VERSION ""

NS_ :

BS_:

BU_: ETH

BO_ 800 BMS_alertMatrix: 8 Vector__XXX
 SG_ BMS_matrixIndex M : 0|4@1+ (1,0) [0|0] "" Vector__XXX
 SG_ BMS_a001_Pack_Config_Mismatch m0 : 4|1@1+ (1,0) [0|0] "" Vector__XXX
 SG_ BMS_a061_SW_BrickV_Change m1 : 4|1@1+ (1,0) [0|0] "" Vector__XXX
 SG_ BMS_a121_SW_NVRAM_Config_Error m2 : 4|1@1+ (1,0) [0|0] "" Vector__XXX
 SG_ BMS_a181_SW_Shunt_Over_Temperature m3 : 4|1@1+ (1,0) [0|0] "" Vector__XXX
 SG_ BMS_a002_Pack_Performance_Config_Mismatch m0 : 5|1@1+ (1,0) [0|0] "" Vector__XXX
 SG_ BMS_a062_SW_BrickV_Imbalance m1 : 5|1@1+ (1,0) [0|0] "" Vector__XXX
 SG_ BMS_a122_SW_BMS_Therm_Irrational m2 : 5|1@1+ (1,0) [0|0] "" Vector__XXX
 SG_ BMS_a182_LifeModel_NoCurrentLoss_Change m3 : 5|1@1+ (1,0) [0|0] "" Vector__XXX
 SG_ BMS_a003_SW_Pack_Birth_Date_Missing m0 : 6|1@1+ (1,0) [0|0] "" Vector__XXX
 SG_ BMS_a063_SW_ChargePort_Fault m1 : 6|1@1+ (1,0) [0|0] "" Vector__XXX
 SG_ BMS_a123_SW_Internal_Isolation m2 : 6|1@1+ (1,0) [0|0] "" Vector__XXX
 SG_ BMS_a183_LifeModel_StoDcrGrowth_Change m3 : 6|1@1+ (1,0) [0|0] "" Vector__XXX
 SG_ BMS_a004_Cal_Vs_Serial_Birth_Date_Mismatch m0 : 7|1@1+ (1,0) [0|0] "" Vector__XXX
 SG_ BMS_a064_SW_SOC_Imbalance m1 : 7|1@1+ (1,0) [0|0] "" Vector__XXX
 SG_ BMS_a124_Battery_Coolant_Flood m2 : 7|1@1+ (1,0) [0|0] "" Vector__XXX
 SG_ BMS_a184_LifeModel_CyclingLoss_Change m3 : 7|1@1+ (1,0) [0|0] "" Vector__XXX
 SG_ BMS_a065_SW_CAC_Imbalance m1 : 8|1@1+ (1,0) [0|0] "" Vector__XXX
 SG_ BMS_a185_LifeModel_CyclingDcrGrowth_Change m3 : 8|1@1+ (1,0) [0|0] "" Vector__XXX
 SG_ BMS_a066_SOC_Imbalance_Warning m1 : 9|1@1+ (1,0) [0|0] "" Vector__XXX
 SG_ BMS_a126_SW_Thermistor_Failure m2 : 9|1@1+ (1,0) [0|0] "" Vector__XXX
 SG_ BMS_a186_RippleHeatingChargeFault m3 : 9|1@1+ (1,0) [0|0] "" Vector__XXX
 SG_ BMS_a067_CAC_Imbalance_Limiting m1 : 10|1@1+ (1,0) [0|0] "" Vector__XXX
 SG_ BMS_a127_SW_shunt_SNA m2 : 10|1@1+ (1,0) [0|0] "" Vector__XXX
 SG_ BMS_a187_RippleHeatingEmergencyShutdown m3 : 10|1@1+ (1,0) [0|0] "" Vector__XXX
 SG_ BMS_a068_CAC_Imbalance_Limp m1 : 11|1@1+ (1,0) [0|0] "" Vector__XXX
 SG_ BMS_a128_SW_shunt_MIA m2 : 11|1@1+ (1,0) [0|0] "" Vector__XXX
 SG_ BMS_a188_PowershareChargeCurrentViolation m3 : 11|1@1+ (1,0) [0|0] "" Vector__XXX
 SG_ BMS_a069_SW_Low_Power m1 : 12|1@1+ (1,0) [0|0] "" Vector__XXX
 SG_ BMS_a129_SW_VSH_Failure m2 : 12|1@1+ (1,0) [0|0] "" Vector__XXX
 SG_ BMS_a189_PowershareDischargeCurrentViolation m3 : 12|1@1+ (1,0) [0|0] "" Vector__XXX
 SG_ BMS_a070_BrickV_Imbalance_Limiting m1 : 13|1@1+ (1,0) [0|0] "" Vector__XXX
 SG_ BMS_a130_IO_CAN_Error m2 : 13|1@1+ (1,0) [0|0] "" Vector__XXX
 SG_ BMS_a190_PowershareMaxVoltageViolation m3 : 13|1@1+ (1,0) [0|0] "" Vector__XXX
 SG_ BMS_a071_SW_SM_TransCon_Not_Met m1 : 14|1@1+ (1,0) [0|0] "" Vector__XXX
 SG_ BMS_a131_Bleed_FET_Failure m2 : 14|1@1+ (1,0) [0|0] "" Vector__XXX
 SG_ BMS_a191_PowershareMinVoltageViolation m3 : 14|1@1+ (1,0) [0|0] "" Vector__XXX
 SG_ BMS_a072_Module_Brick_Split m1 : 15|1@1+ (1,0) [0|0] "" Vector__XXX
 SG_ BMS_a132_HW_BMB_OTP_Uncorrctbl m2 : 15|1@1+ (1,0) [0|0] "" Vector__XXX
 SG_ BMS_a192_PowershareExternalChargeRegulation m3 : 15|1@1+ (1,0) [0|0] "" Vector__XXX
 SG_ BMS_a073_Unexpected_Loss_Of_Lv m1 : 16|1@1+ (1,0) [0|0] "" Vector__XXX
 SG_ BMS_a133_IO_CAN_Bus_Off m2 : 16|1@1+ (1,0) [0|0] "" Vector__XXX
 SG_ BMS_a193_PowershareMaxBrickVoltageViolation m3 : 16|1@1+ (1,0) [0|0] "" Vector__XXX
 SG_ BMS_a074_Max_Charge_Level_Reduced m1 : 17|1@1+ (1,0) [0|0] "" Vector__XXX
 SG_ BMS_a134_SW_Delayed_Ctr_Off m2 : 17|1@1+ (1,0) [0|0] "" Vector__XXX
 SG_ BMS_a194_PowershareLimitViolation m3 : 17|1@1+ (1,0) [0|0] "" Vector__XXX
 SG_ BMS_a075_SW_Chg_Disable_Failure m1 : 18|1@1+ (1,0) [0|0] "" Vector__XXX
 SG_ BMS_a135_HW_BMB_Diagnostics_Failure m2 : 18|1@1+ (1,0) [0|0] "" Vector__XXX
 SG_ BMS_a195_SW_DeltaTempOverThreshold m3 : 18|1@1+ (1,0) [0|0] "" Vector__XXX
 SG_ BMS_a016_Pack_Module_Id_Mismatch m0 : 19|1@1+ (1,0) [0|0] "" Vector__XXX
 SG_ BMS_a076_SW_Dch_While_Charging m1 : 19|1@1+ (1,0) [0|0] "" Vector__XXX
 SG_ BMS_a136_SW_Module_OT_Warning m2 : 19|1@1+ (1,0) [0|0] "" Vector__XXX
 SG_ BMS_a196_SW_PackVoltageUnderThreshold m3 : 19|1@1+ (1,0) [0|0] "" Vector__XXX
 SG_ BMS_a017_SW_Brick_OV m0 : 20|1@1+ (1,0) [0|0] "" Vector__XXX
 SG_ BMS_a077_SW_Charger_Regulation m1 : 20|1@1+ (1,0) [0|0] "" Vector__XXX
 SG_ BMS_a137_SW_Brick_UV_Warning m2 : 20|1@1+ (1,0) [0|0] "" Vector__XXX
 SG_ BMS_a197_SW_High_SOC_OV m3 : 20|1@1+ (1,0) [0|0] "" Vector__XXX
 SG_ BMS_d257_internalIsolationFault m4 : 20|1@1+ (1,0) [0|0] "" Vector__XXX
 SG_ BMS_a018_SW_Brick_UV m0 : 21|1@1+ (1,0) [0|0] "" Vector__XXX
 SG_ BMS_a078_Rapid_Dch_While_Charging m1 : 21|1@1+ (1,0) [0|0] "" Vector__XXX
 SG_ BMS_a138_SW_Brick_OV_Warning m2 : 21|1@1+ (1,0) [0|0] "" Vector__XXX
 SG_ BMS_a198_SW_SOC_Abrupt_Change m3 : 21|1@1+ (1,0) [0|0] "" Vector__XXX
 SG_ BMS_d258_externalIsolationFault m4 : 21|1@1+ (1,0) [0|0] "" Vector__XXX
 SG_ BMS_a019_SW_Module_OT m0 : 22|1@1+ (1,0) [0|0] "" Vector__XXX
 SG_ BMS_a079_Max_Charge_Level_Exceeded m1 : 22|1@1+ (1,0) [0|0] "" Vector__XXX
 SG_ BMS_a139_SW_DC_Link_V_Irrational m2 : 22|1@1+ (1,0) [0|0] "" Vector__XXX
 SG_ BMS_d259_highVoltageInterlockFailure m4 : 22|1@1+ (1,0) [0|0] "" Vector__XXX
 SG_ BMS_a020_SW_Brick_Instability m0 : 23|1@1+ (1,0) [0|0] "" Vector__XXX
 SG_ BMS_a080_SW_Pack_Ctr_Impedance m1 : 23|1@1+ (1,0) [0|0] "" Vector__XXX
 SG_ BMS_a140_HW_BMB_Status_Fault m2 : 23|1@1+ (1,0) [0|0] "" Vector__XXX
 SG_ BMS_d260_chargePortInterlockFailure m4 : 23|1@1+ (1,0) [0|0] "" Vector__XXX
 SG_ BMS_a021_SW_Dr_Limits_Regulation m0 : 24|1@1+ (1,0) [0|0] "" Vector__XXX
 SG_ BMS_a081_SW_Ctr_Close_Blocked m1 : 24|1@1+ (1,0) [0|0] "" Vector__XXX
 SG_ BMS_a141_SW_BMB_Status_Warning m2 : 24|1@1+ (1,0) [0|0] "" Vector__XXX
 SG_ BMS_d261_batteryPackCellVoltageHigh m4 : 24|1@1+ (1,0) [0|0] "" Vector__XXX
 SG_ BMS_a022_SW_Over_Current m0 : 25|1@1+ (1,0) [0|0] "" Vector__XXX
 SG_ BMS_a082_SW_Ctr_Force_Open m1 : 25|1@1+ (1,0) [0|0] "" Vector__XXX
 SG_ BMS_a142_SW_Isolation_Degradation m2 : 25|1@1+ (1,0) [0|0] "" Vector__XXX
 SG_ BMS_d262_batteryPackLowStateOfCharge m4 : 25|1@1+ (1,0) [0|0] "" Vector__XXX
 SG_ BMS_a023_SW_Stack_OV m0 : 26|1@1+ (1,0) [0|0] "" Vector__XXX
 SG_ BMS_a083_SW_Ctr_Close_Failure m1 : 26|1@1+ (1,0) [0|0] "" Vector__XXX
 SG_ BMS_a143_SW_CAC_Change m2 : 26|1@1+ (1,0) [0|0] "" Vector__XXX
 SG_ BMS_d263_batterySystemCurrentHigh m4 : 26|1@1+ (1,0) [0|0] "" Vector__XXX
 SG_ BMS_a024_SW_Islanded_Brick m0 : 27|1@1+ (1,0) [0|0] "" Vector__XXX
 SG_ BMS_a084_SW_Sleep_Wake_Aborted m1 : 27|1@1+ (1,0) [0|0] "" Vector__XXX
 SG_ BMS_a144_Hvp_Config_Mismatch m2 : 27|1@1+ (1,0) [0|0] "" Vector__XXX
 SG_ BMS_d264_invalidFirmwareConfig m4 : 27|1@1+ (1,0) [0|0] "" Vector__XXX
 SG_ BMS_a025_SW_PwrBalance_Anomaly m0 : 28|1@1+ (1,0) [0|0] "" Vector__XXX
 SG_ BMS_a085_SW_Pack_Contactor_Mismatch m1 : 28|1@1+ (1,0) [0|0] "" Vector__XXX
 SG_ BMS_a145_SW_SOC_Change m2 : 28|1@1+ (1,0) [0|0] "" Vector__XXX
 SG_ BMS_d265_replaceBatteryPack m4 : 28|1@1+ (1,0) [0|0] "" Vector__XXX
 SG_ BMS_a026_SW_HFCurrent_Anomaly m0 : 29|1@1+ (1,0) [0|0] "" Vector__XXX
 SG_ BMS_a086_SW_FC_Contactor_Mismatch m1 : 29|1@1+ (1,0) [0|0] "" Vector__XXX
 SG_ BMS_a146_SW_Brick_Overdischarged m2 : 29|1@1+ (1,0) [0|0] "" Vector__XXX
 SG_ BMS_d266_energyReserveVoltageLow m4 : 29|1@1+ (1,0) [0|0] "" Vector__XXX
 SG_ BMS_a027_SW_Repeated_Isolation_Failure_In_Drive m0 : 30|1@1+ (1,0) [0|0] "" Vector__XXX
 SG_ BMS_a087_SW_Feim_Test_Blocked m1 : 30|1@1+ (1,0) [0|0] "" Vector__XXX
 SG_ BMS_a147_SW_SOC_High_Ah_Error m2 : 30|1@1+ (1,0) [0|0] "" Vector__XXX
 SG_ BMS_d267_batteryPackCellVoltageSenseHarnessFailure m4 : 30|1@1+ (1,0) [0|0] "" Vector__XXX
 SG_ BMS_a028_ShuntAsicCurrentOffsetDeviation m0 : 31|1@1+ (1,0) [0|0] "" Vector__XXX
 SG_ BMS_a088_SW_VcFront_MIA_InDrive m1 : 31|1@1+ (1,0) [0|0] "" Vector__XXX
 SG_ BMS_a148_SW_Unsupported_BMB_ASIC_Type m2 : 31|1@1+ (1,0) [0|0] "" Vector__XXX
 SG_ BMS_d268_hvpInvalidFirmwareConfig m4 : 31|1@1+ (1,0) [0|0] "" Vector__XXX
 SG_ BMS_a029_dSoc_Limiting m0 : 32|1@1+ (1,0) [0|0] "" Vector__XXX
 SG_ BMS_a089_SW_VcFront_MIA m1 : 32|1@1+ (1,0) [0|0] "" Vector__XXX
 SG_ BMS_a149_SW_Missing_Config_Block m2 : 32|1@1+ (1,0) [0|0] "" Vector__XXX
 SG_ BMS_d269_highVoltageFuseABlown m4 : 32|1@1+ (1,0) [0|0] "" Vector__XXX
 SG_ BMS_a030_Impedance_Deviation m0 : 33|1@1+ (1,0) [0|0] "" Vector__XXX
 SG_ BMS_a090_SW_Gateway_MIA m1 : 33|1@1+ (1,0) [0|0] "" Vector__XXX
 SG_ BMS_a150_SW_Missing_Part_Number m2 : 33|1@1+ (1,0) [0|0] "" Vector__XXX
 SG_ BMS_d270_hvpCommsLost m4 : 33|1@1+ (1,0) [0|0] "" Vector__XXX
 SG_ BMS_a031_AlertsSetDuringSleep m0 : 34|1@1+ (1,0) [0|0] "" Vector__XXX
 SG_ BMS_a091_SW_ChargePort_MIA m1 : 34|1@1+ (1,0) [0|0] "" Vector__XXX
 SG_ BMS_a151_SW_external_isolation m2 : 34|1@1+ (1,0) [0|0] "" Vector__XXX
 SG_ BMS_d271_batteryPackSensorFailure m4 : 34|1@1+ (1,0) [0|0] "" Vector__XXX
 SG_ BMS_a032_VoltageLoss m0 : 35|1@1+ (1,0) [0|0] "" Vector__XXX
 SG_ BMS_a092_SW_ChargePort_Mia_On_Hvs m1 : 35|1@1+ (1,0) [0|0] "" Vector__XXX
 SG_ BMS_a152_Isolation_In_Dc_Charge m2 : 35|1@1+ (1,0) [0|0] "" Vector__XXX
 SG_ BMS_d272_batteryPackSensorCommsLost m4 : 35|1@1+ (1,0) [0|0] "" Vector__XXX
 SG_ BMS_a033_VoltageDeviation m0 : 36|1@1+ (1,0) [0|0] "" Vector__XXX
 SG_ BMS_a153_GridFormFaulted m2 : 36|1@1+ (1,0) [0|0] "" Vector__XXX
 SG_ BMS_d273_vcFrontCommsLost m4 : 36|1@1+ (1,0) [0|0] "" Vector__XXX
 SG_ BMS_a034_SW_Passive_Isolation m0 : 37|1@1+ (1,0) [0|0] "" Vector__XXX
 SG_ BMS_a094_SW_Drive_Inverter_MIA m1 : 37|1@1+ (1,0) [0|0] "" Vector__XXX
 SG_ BMS_a154_SW_Brick_OV_Warning_Stop_Charge m2 : 37|1@1+ (1,0) [0|0] "" Vector__XXX
 SG_ BMS_d274_packCurrentSensorACircuitFailure m4 : 37|1@1+ (1,0) [0|0] "" Vector__XXX
 SG_ BMS_a035_SW_Isolation m0 : 38|1@1+ (1,0) [0|0] "" Vector__XXX
 SG_ BMS_a095_SW_UI_MIA m1 : 38|1@1+ (1,0) [0|0] "" Vector__XXX
 SG_ BMS_a155_SW_Weak_short_impedence m2 : 38|1@1+ (1,0) [0|0] "" Vector__XXX
 SG_ BMS_d275_packPosContactorACircuitFailure m4 : 38|1@1+ (1,0) [0|0] "" Vector__XXX
 SG_ BMS_a036_SW_HvpHvilFault m0 : 39|1@1+ (1,0) [0|0] "" Vector__XXX
 SG_ BMS_a156_SW_BMB_Vref_bad m2 : 39|1@1+ (1,0) [0|0] "" Vector__XXX
 SG_ BMS_d276_packPosContactorAStuckClosed m4 : 39|1@1+ (1,0) [0|0] "" Vector__XXX
 SG_ BMS_a037_SW_Flood_Port_Open m0 : 40|1@1+ (1,0) [0|0] "" Vector__XXX
 SG_ BMS_a097_SW_BMB_Over_CAN_Communication m1 : 40|1@1+ (1,0) [0|0] "" Vector__XXX
 SG_ BMS_a157_SW_Hist_Update_Missed m2 : 40|1@1+ (1,0) [0|0] "" Vector__XXX
 SG_ BMS_d277_packNegContactorACircuitFailure m4 : 40|1@1+ (1,0) [0|0] "" Vector__XXX
 SG_ BMS_a098_SW_BMB_Data_Integrity_Loss m1 : 41|1@1+ (1,0) [0|0] "" Vector__XXX
 SG_ BMS_a158_SW_HVP_HVI_Comms m2 : 41|1@1+ (1,0) [0|0] "" Vector__XXX
 SG_ BMS_d278_packNegContactorAStuckClosed m4 : 41|1@1+ (1,0) [0|0] "" Vector__XXX
 SG_ BMS_a039_SW_DC_Link_Over_Voltage m0 : 42|1@1+ (1,0) [0|0] "" Vector__XXX
 SG_ BMS_a099_SW_BMB_Communication m1 : 42|1@1+ (1,0) [0|0] "" Vector__XXX
 SG_ BMS_a159_SW_HVP_ECU_Error m2 : 42|1@1+ (1,0) [0|0] "" Vector__XXX
 SG_ BMS_d279_fastChargePosContactorACircuitFailure m4 : 42|1@1+ (1,0) [0|0] "" Vector__XXX
 SG_ BMS_a040_SW_Watch_Dog_HW_Triggered m0 : 43|1@1+ (1,0) [0|0] "" Vector__XXX
 SG_ BMS_a100_ThermalEventSuspected m1 : 43|1@1+ (1,0) [0|0] "" Vector__XXX
 SG_ BMS_a160_SW_FC_Ctr_Clean_Failed m2 : 43|1@1+ (1,0) [0|0] "" Vector__XXX
 SG_ BMS_d280_fastChargePosContactorAStuckClosed m4 : 43|1@1+ (1,0) [0|0] "" Vector__XXX
 SG_ BMS_a041_SW_Destructive_Reset_Source m0 : 44|1@1+ (1,0) [0|0] "" Vector__XXX
 SG_ BMS_a161_SW_BMB_Vref_warning m2 : 44|1@1+ (1,0) [0|0] "" Vector__XXX
 SG_ BMS_d281_fastChargePosContactorAStuckOpen m4 : 44|1@1+ (1,0) [0|0] "" Vector__XXX
 SG_ BMS_a042_SW_MPU_Error m0 : 45|1@1+ (1,0) [0|0] "" Vector__XXX
 SG_ BMS_a162_SW_No_Power_For_Support m2 : 45|1@1+ (1,0) [0|0] "" Vector__XXX
 SG_ BMS_d282_fastChargeNegContactorACircuitFailure m4 : 45|1@1+ (1,0) [0|0] "" Vector__XXX
 SG_ BMS_a043_SW_Watch_Dog_Reset m0 : 46|1@1+ (1,0) [0|0] "" Vector__XXX
 SG_ BMS_a163_GridFormAborted m2 : 46|1@1+ (1,0) [0|0] "" Vector__XXX
 SG_ BMS_d283_fastChargeNegContactorAStuckClosed m4 : 46|1@1+ (1,0) [0|0] "" Vector__XXX
 SG_ BMS_a044_SW_Assertion m0 : 47|1@1+ (1,0) [0|0] "" Vector__XXX
 SG_ BMS_a164_SW_Uncontrolled_Regen m2 : 47|1@1+ (1,0) [0|0] "" Vector__XXX
 SG_ BMS_d284_fastChargeNegContactorAStuckOpen m4 : 47|1@1+ (1,0) [0|0] "" Vector__XXX
 SG_ BMS_a045_SW_Exception m0 : 48|1@1+ (1,0) [0|0] "" Vector__XXX
 SG_ BMS_a105_SW_One_Module_Tsense m1 : 48|1@1+ (1,0) [0|0] "" Vector__XXX
 SG_ BMS_a165_SW_Pack_Partial_Weld m2 : 48|1@1+ (1,0) [0|0] "" Vector__XXX
 SG_ BMS_d285_packVoltageSensorACircuitFailure m4 : 48|1@1+ (1,0) [0|0] "" Vector__XXX
 SG_ BMS_a046_SW_Task_Stack_Usage m0 : 49|1@1+ (1,0) [0|0] "" Vector__XXX
 SG_ BMS_a106_SW_All_Module_Tsense m1 : 49|1@1+ (1,0) [0|0] "" Vector__XXX
 SG_ BMS_a166_SW_Pack_Full_Weld m2 : 49|1@1+ (1,0) [0|0] "" Vector__XXX
 SG_ BMS_d286_dcLinkVoltageHigh m4 : 49|1@1+ (1,0) [0|0] "" Vector__XXX
 SG_ BMS_a047_SW_Task_Stack_Overflow m0 : 50|1@1+ (1,0) [0|0] "" Vector__XXX
 SG_ BMS_a107_SW_Stack_Voltage_MIA m1 : 50|1@1+ (1,0) [0|0] "" Vector__XXX
 SG_ BMS_a167_SW_FC_Partial_Weld m2 : 50|1@1+ (1,0) [0|0] "" Vector__XXX
 SG_ BMS_d287_systemIsolationWarning m4 : 50|1@1+ (1,0) [0|0] "" Vector__XXX
 SG_ BMS_a048_SW_Watch_Dog_Warning m0 : 51|1@1+ (1,0) [0|0] "" Vector__XXX
 SG_ BMS_a108_SW_BMB_Device_OT m1 : 51|1@1+ (1,0) [0|0] "" Vector__XXX
 SG_ BMS_a168_SW_FC_Full_Weld m2 : 51|1@1+ (1,0) [0|0] "" Vector__XXX
 SG_ BMS_d288_batteryPackCellVoltageLow m4 : 51|1@1+ (1,0) [0|0] "" Vector__XXX
 SG_ BMS_a049_SW_Thermal_Event m0 : 52|1@1+ (1,0) [0|0] "" Vector__XXX
 SG_ BMS_a109_HW_BMB_Mute_Status_Mismatch m1 : 52|1@1+ (1,0) [0|0] "" Vector__XXX
 SG_ BMS_a169_SW_FC_Pack_Weld m2 : 52|1@1+ (1,0) [0|0] "" Vector__XXX
 SG_ BMS_d289_batteryPackAOverTemperature m4 : 52|1@1+ (1,0) [0|0] "" Vector__XXX
 SG_ BMS_a050_SW_Brick_Voltage_MIA m0 : 53|1@1+ (1,0) [0|0] "" Vector__XXX
 SG_ BMS_a110_LifeModel_AvgOffset_Change m1 : 53|1@1+ (1,0) [0|0] "" Vector__XXX
 SG_ BMS_a170_SW_Limp_Mode m2 : 53|1@1+ (1,0) [0|0] "" Vector__XXX
 SG_ BMS_d290_batteryPackTempSensorACircuitFailure m4 : 53|1@1+ (1,0) [0|0] "" Vector__XXX
 SG_ BMS_a051_SW_HVC_Vref_Bad m0 : 54|1@1+ (1,0) [0|0] "" Vector__XXX
 SG_ BMS_a111_LifeModel_Spread_Change m1 : 54|1@1+ (1,0) [0|0] "" Vector__XXX
 SG_ BMS_a171_SW_Stack_Voltage_Sense m2 : 54|1@1+ (1,0) [0|0] "" Vector__XXX
 SG_ BMS_a052_SW_PCS_MIA m0 : 55|1@1+ (1,0) [0|0] "" Vector__XXX
 SG_ BMS_a112_LifeModel_Discontinuity m1 : 55|1@1+ (1,0) [0|0] "" Vector__XXX
 SG_ BMS_a172_SW_Isolation_Failure_In_Drive_Warning m2 : 55|1@1+ (1,0) [0|0] "" Vector__XXX
 SG_ BMS_a173_FullPackEnergyDegraded m2 : 56|1@1+ (1,0) [0|0] "" Vector__XXX
 SG_ BMS_a054_SW_Ver_Supply_Fault m0 : 57|1@1+ (1,0) [0|0] "" Vector__XXX
 SG_ BMS_a174_SW_Charge_Failure m2 : 57|1@1+ (1,0) [0|0] "" Vector__XXX
 SG_ BMS_a055_SW_HvChain_Model_Fault m0 : 58|1@1+ (1,0) [0|0] "" Vector__XXX
 SG_ BMS_a115_Energy_Rubberbanding_Reset m1 : 58|1@1+ (1,0) [0|0] "" Vector__XXX
 SG_ BMS_a175_Charge_Failure_External m2 : 58|1@1+ (1,0) [0|0] "" Vector__XXX
 SG_ BMS_a056_SW_Standby_Supply_Fault m0 : 59|1@1+ (1,0) [0|0] "" Vector__XXX
 SG_ BMS_a176_SW_GracefulPowerOff m2 : 59|1@1+ (1,0) [0|0] "" Vector__XXX
 SG_ BMS_a057_SW_Bandolier_Model_Warning m0 : 60|1@1+ (1,0) [0|0] "" Vector__XXX
 SG_ BMS_a117_SW_Delta_SOC_Weak_Short m1 : 60|1@1+ (1,0) [0|0] "" Vector__XXX
 SG_ BMS_a177_SW_Energy_Buffer_Size m2 : 60|1@1+ (1,0) [0|0] "" Vector__XXX
 SG_ BMS_a058_SW_Bandolier_Model_Reset m0 : 61|1@1+ (1,0) [0|0] "" Vector__XXX
 SG_ BMS_a178_SW_Uncontrolled_Regen_PwrB m2 : 61|1@1+ (1,0) [0|0] "" Vector__XXX
 SG_ BMS_a059_SW_Pack_Voltage_Sensing m0 : 62|1@1+ (1,0) [0|0] "" Vector__XXX
 SG_ BMS_a119_Fast_Open_Vsh_Detected m1 : 62|1@1+ (1,0) [0|0] "" Vector__XXX
 SG_ BMS_a179_HvpGpoRequestActive m2 : 62|1@1+ (1,0) [0|0] "" Vector__XXX
 SG_ BMS_a060_SW_Leakage_Test_Failure m0 : 63|1@1+ (1,0) [0|0] "" Vector__XXX
 SG_ BMS_a180_SW_ECU_reset_blocked m2 : 63|1@1+ (1,0) [0|0] "" Vector__XXX

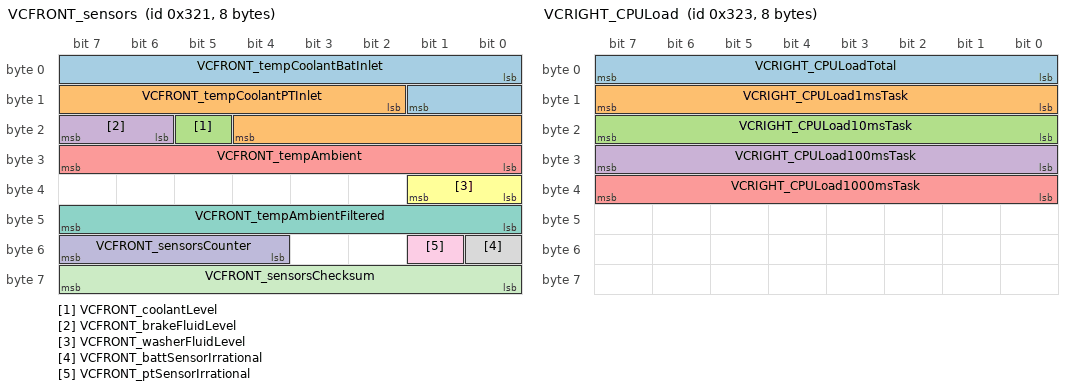
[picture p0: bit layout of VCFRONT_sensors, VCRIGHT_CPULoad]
BO_ 801 VCFRONT_sensors: 8 Vector__XXX
 SG_ VCFRONT_tempCoolantBatInlet : 0|10@1+ (0.125,-40) [0|0] "" Vector__XXX
 SG_ VCFRONT_tempCoolantPTInlet : 10|11@1+ (0.125,-40) [0|0] "" Vector__XXX
 SG_ VCFRONT_coolantLevel : 21|1@1+ (1,0) [0|0] "" Vector__XXX
 SG_ VCFRONT_brakeFluidLevel : 22|2@1+ (1,0) [0|0] "" Vector__XXX
 SG_ VCFRONT_tempAmbient : 24|8@1+ (0.5,-40) [0|0] "" Vector__XXX
 SG_ VCFRONT_washerFluidLevel : 32|2@1+ (1,0) [0|0] "" Vector__XXX
 SG_ VCFRONT_tempAmbientFiltered : 40|8@1+ (0.5,-40) [0|0] "" Vector__XXX
 SG_ VCFRONT_battSensorIrrational : 48|1@1+ (1,0) [0|0] "" Vector__XXX
 SG_ VCFRONT_ptSensorIrrational : 49|1@1+ (1,0) [0|0] "" Vector__XXX
 SG_ VCFRONT_sensorsCounter : 52|4@1+ (1,0) [0|0] "" Vector__XXX
 SG_ VCFRONT_sensorsChecksum : 56|8@1+ (1,0) [0|0] "" Vector__XXX

BO_ 803 VCRIGHT_CPULoad: 8 Vector__XXX
 SG_ VCRIGHT_CPULoadTotal : 0|8@1+ (1,0) [0|0] "" Vector__XXX
 SG_ VCRIGHT_CPULoad1msTask : 8|8@1+ (1,0) [0|0] "" Vector__XXX
 SG_ VCRIGHT_CPULoad10msTask : 16|8@1+ (1,0) [0|0] "" Vector__XXX
 SG_ VCRIGHT_CPULoad100msTask : 24|8@1+ (1,0) [0|0] "" Vector__XXX
 SG_ VCRIGHT_CPULoad1000msTask : 32|8@1+ (1,0) [0|0] "" Vector__XXX

BO_ 804 UI_gpsTime: 8 Vector__XXX
 SG_ UI_gpsTime : 0|64@1+ (1,0) [0|0] "" Vector__XXX

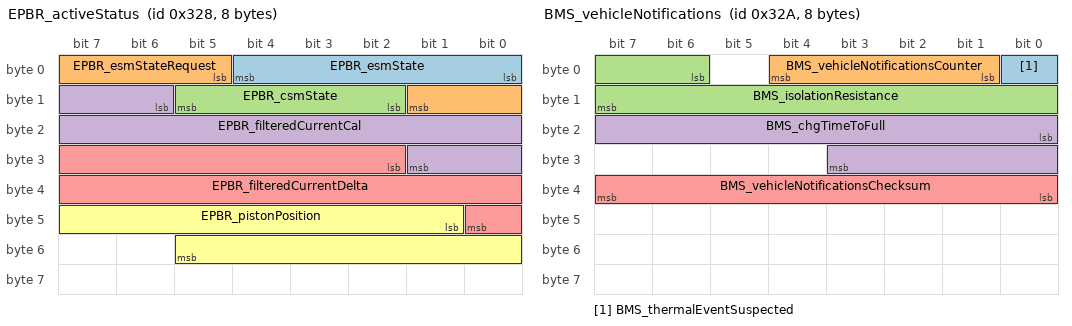
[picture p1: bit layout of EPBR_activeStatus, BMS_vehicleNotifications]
BO_ 808 EPBR_activeStatus: 8 Vector__XXX
 SG_ EPBR_esmState : 0|5@1+ (1,0) [0|0] "" Vector__XXX
 SG_ EPBR_esmStateRequest : 5|5@1+ (1,0) [0|0] "" Vector__XXX
 SG_ EPBR_csmState : 10|4@1+ (1,0) [0|0] "" Vector__XXX
 SG_ EPBR_filteredCurrentCal : 14|12@1+ (0.01,0) [0|0] "" Vector__XXX
 SG_ EPBR_filteredCurrentDelta : 26|15@1- (0.01,0) [0|0] "" Vector__XXX
 SG_ EPBR_pistonPosition : 41|13@1- (9.768009768009769,0) [0|0] "" Vector__XXX

BO_ 810 BMS_vehicleNotifications: 8 Vector__XXX
 SG_ BMS_thermalEventSuspected : 0|1@1+ (1,0) [0|0] "" Vector__XXX
 SG_ BMS_vehicleNotificationsCounter : 1|4@1+ (1,0) [0|0] "" Vector__XXX
 SG_ BMS_isolationResistance : 6|10@1+ (10,0) [0|0] "" Vector__XXX
 SG_ BMS_chgTimeToFull : 16|12@1+ (0.01666667,0) [0|0] "" Vector__XXX
 SG_ BMS_vehicleNotificationsChecksum : 32|8@1+ (1,0) [0|0] "" Vector__XXX

BO_ 812 CC_logData: 8 Vector__XXX
 SG_ CC_logIndex M : 0|8@1+ (1,0) [0|0] "" Vector__XXX
 SG_ CC_activeConnectorID m0 : 8|8@1+ (1,0) [0|0] "" Vector__XXX
 SG_ CC_conn1Current m1 : 8|8@1+ (0.5,0) [0|0] "" Vector__XXX
 SG_ CC_conn2Current m2 : 8|8@1+ (0.5,0) [0|0] "" Vector__XXX
 SG_ CC_conn3Current m3 : 8|8@1+ (0.5,0) [0|0] "" Vector__XXX
 SG_ CC_conn4Current m4 : 8|8@1+ (0.5,0) [0|0] "" Vector__XXX
 SG_ CC_lifetimeAlertCount m12 : 8|28@1+ (1,0) [0|0] "" Vector__XXX
 SG_ CC_lifetimeCtrCycles m11 : 8|28@1+ (1,0) [0|0] "" Vector__XXX
 SG_ CC_temperature1 m0 : 16|8@1- (1,88) [0|0] "" Vector__XXX
 SG_ CC_temperature2 m0 : 24|8@1- (1,88) [0|0] "" Vector__XXX
 SG_ CC_lifetimei2t m10 : 32|32@1+ (0.1,0) [0|0] "" Vector__XXX
 SG_ CC_temperature3 m0 : 32|8@1- (1,88) [0|0] "" Vector__XXX
 SG_ CC_lifetimeAvgStartupTemp m13 : 36|28@1- (0.1,0) [0|0] "" Vector__XXX
 SG_ CC_lifetimeCtrCyclesLoaded m11 : 36|28@1+ (1,0) [0|0] "" Vector__XXX
 SG_ CC_lifetimeThermalFoldbacks m12 : 36|28@1+ (1,0) [0|0] "" Vector__XXX
 SG_ CC_contactor1Closed m0 : 40|2@1+ (1,0) [0|0] "" Vector__XXX
 SG_ CC_contactor2Closed m0 : 42|2@1+ (1,0) [0|0] "" Vector__XXX
 SG_ CC_temperature4 m0 : 44|8@1- (1,88) [0|0] "" Vector__XXX

BO_ 815 SCM_alertMatrix1: 8 Vector__XXX
 SG_ SCM_a027_externalIsolationLow : 26|1@1+ (1,0) [0|0] "" Vector__XXX
 SG_ SCM_a044_proximityRationality : 43|1@1+ (1,0) [0|0] "" Vector__XXX

BO_ 816 SCCM_info: 12 Vector__XXX
 SG_ SCCM_infoIndex M : 0|8@1+ (1,0) [0|0] "" Vector__XXX
 SG_ SCCM_infoAppSvnHash m17 : 8|56@1+ (1,0) [0|0] "" Vector__XXX
 SG_ SCCM_infoBootSvnHash m18 : 8|56@1+ (1,0) [0|0] "" Vector__XXX
 SG_ SCCM_infoBootSvnRev m14 : 8|24@1+ (1,0) [0|0] "" Vector__XXX
 SG_ SCCM_infoBuildType m10 : 8|8@1+ (1,0) [0|0] "" Vector__XXX
 SG_ SCCM_infoPlatformType m13 : 8|8@1+ (1,0) [0|0] "" Vector__XXX
 SG_ SCCM_infoUdsProtoVersion m20 : 8|8@1+ (1,0) [0|0] "" Vector__XXX
 SG_ SCCM_infoBuildConfigId m10 : 16|16@1+ (1,0) [0|0] "" Vector__XXX
 SG_ SCCM_infoPcbaId m11 : 16|8@1+ (1,0) [0|0] "" Vector__XXX
 SG_ SCCM_infoSubcomponent1Version m16 : 16|32@1+ (1,0) [0|0] "" Vector__XXX
 SG_ SCCM_infoAssemblyId m11 : 24|8@1+ (1,0) [0|0] "" Vector__XXX
 SG_ SCCM_infoBootCrc m20 : 32|32@1+ (1,0) [0|0] "" Vector__XXX
 SG_ SCCM_infoBootSvnUrlHash m14 : 32|32@1+ (1,0) [0|0] "" Vector__XXX
 SG_ SCCM_infoHardwareId m10 : 32|16@1+ (1,0) [0|0] "" Vector__XXX
 SG_ SCCM_infoUsageId m11 : 32|16@1+ (1,0) [0|0] "" Vector__XXX
 SG_ SCCM_infoAppCrc m13 : 39|32@0+ (1,0) [0|0] "" Vector__XXX
 SG_ SCCM_infoComponentId m10 : 48|16@1+ (1,0) [0|0] "" Vector__XXX
 SG_ SCCM_infoSubUsageId m11 : 48|16@1+ (1,0) [0|0] "" Vector__XXX

BO_ 818 BMS_bmbMinMax: 8 Vector__XXX
 SG_ BMS_bmbMinMaxMultiplexer M : 0|2@1+ (1,0) [0|0] "" Vector__XXX
 SG_ BMS_brickVoltageMax m1 : 2|12@1+ (0.002,0) [0|0] "" Vector__XXX
 SG_ BMS_thermistorNumTMin m0 : 2|4@1+ (1,0) [0|0] "" Vector__XXX
 SG_ BMS_thermistorNumTMax m0 : 8|4@1+ (1,0) [0|0] "" Vector__XXX
 SG_ BMS_brickVoltageMin m1 : 16|12@1+ (0.002,0) [0|0] "" Vector__XXX
 SG_ BMS_thermistorTMax m0 : 16|8@1+ (0.5,-40) [0|0] "" Vector__XXX
 SG_ BMS_thermistorTMin m0 : 24|8@1+ (0.5,-40) [0|0] "" Vector__XXX
 SG_ BMS_brickNumVoltageMax m1 : 32|7@1+ (1,1) [0|0] "" Vector__XXX
 SG_ BMS_thermistorTAvg m0 : 32|8@1+ (0.5,-40) [0|0] "" Vector__XXX
 SG_ BMS_brickNumVoltageMin m1 : 40|7@1+ (1,1) [0|0] "" Vector__XXX

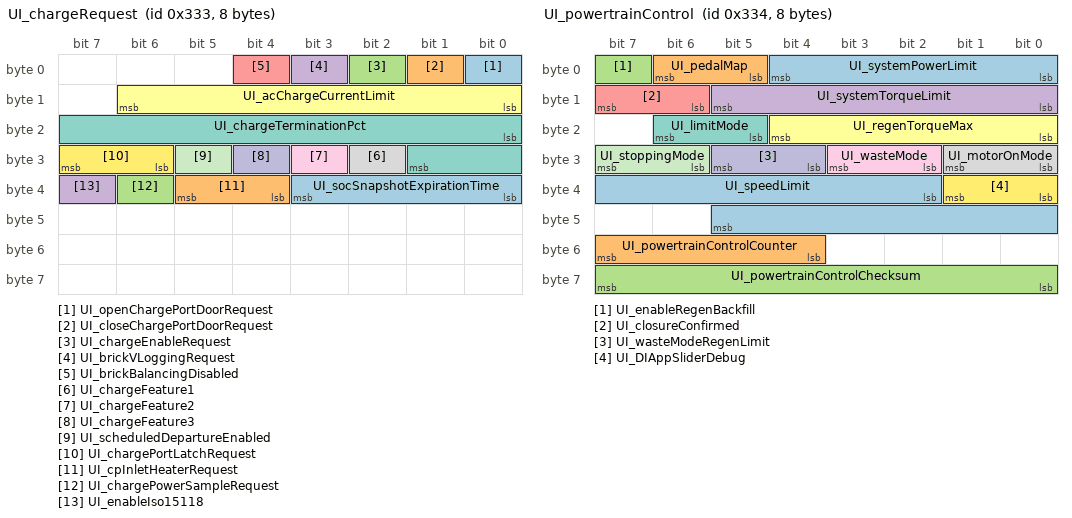
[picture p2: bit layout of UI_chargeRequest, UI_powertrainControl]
BO_ 819 UI_chargeRequest: 8 Vector__XXX
 SG_ UI_openChargePortDoorRequest : 0|1@1+ (1,0) [0|0] "" Vector__XXX
 SG_ UI_closeChargePortDoorRequest : 1|1@1+ (1,0) [0|0] "" Vector__XXX
 SG_ UI_chargeEnableRequest : 2|1@1+ (1,0) [0|0] "" Vector__XXX
 SG_ UI_brickVLoggingRequest : 3|1@1+ (1,0) [0|0] "" Vector__XXX
 SG_ UI_brickBalancingDisabled : 4|1@1+ (1,0) [0|0] "" Vector__XXX
 SG_ UI_acChargeCurrentLimit : 8|7@1+ (1,0) [0|0] "" Vector__XXX
 SG_ UI_chargeTerminationPct : 16|10@1+ (0.1,0) [0|0] "" Vector__XXX
 SG_ UI_chargeFeature1 : 26|1@1+ (1,0) [0|0] "" Vector__XXX
 SG_ UI_chargeFeature2 : 27|1@1+ (1,0) [0|0] "" Vector__XXX
 SG_ UI_chargeFeature3 : 28|1@1+ (1,0) [0|0] "" Vector__XXX
 SG_ UI_scheduledDepartureEnabled : 29|1@1+ (1,0) [0|0] "" Vector__XXX
 SG_ UI_chargePortLatchRequest : 30|2@1+ (1,0) [0|0] "" Vector__XXX
 SG_ UI_socSnapshotExpirationTime : 32|4@1+ (2,2) [0|0] "" Vector__XXX
 SG_ UI_cpInletHeaterRequest : 36|2@1+ (1,0) [0|0] "" Vector__XXX
 SG_ UI_chargePowerSampleRequest : 38|1@1+ (1,0) [0|0] "" Vector__XXX
 SG_ UI_enableIso15118 : 39|1@1+ (1,0) [0|0] "" Vector__XXX

BO_ 820 UI_powertrainControl: 8 Vector__XXX
 SG_ UI_systemPowerLimit : 0|5@1+ (20,20) [0|0] "" Vector__XXX
 SG_ UI_pedalMap : 5|2@1+ (1,0) [0|0] "" Vector__XXX
 SG_ UI_enableRegenBackfill : 7|1@1+ (1,0) [0|0] "" Vector__XXX
 SG_ UI_systemTorqueLimit : 8|6@1+ (150,1000) [0|0] "" Vector__XXX
 SG_ UI_closureConfirmed : 14|2@1+ (1,0) [0|0] "" Vector__XXX
 SG_ UI_regenTorqueMax : 16|5@1+ (5,0) [0|0] "" Vector__XXX
 SG_ UI_limitMode : 21|2@1+ (1,0) [0|0] "" Vector__XXX
 SG_ UI_motorOnMode : 24|2@1+ (1,0) [0|0] "" Vector__XXX
 SG_ UI_wasteMode : 26|2@1+ (1,0) [0|0] "" Vector__XXX
 SG_ UI_wasteModeRegenLimit : 28|2@1+ (1,0) [0|0] "" Vector__XXX
 SG_ UI_stoppingMode : 30|2@1+ (1,0) [0|0] "" Vector__XXX
 SG_ UI_DIAppSliderDebug : 32|2@1+ (1,0) [0|0] "" Vector__XXX
 SG_ UI_speedLimit : 34|12@1+ (0.1,0) [0|0] "" Vector__XXX
 SG_ UI_powertrainControlCounter : 52|4@1+ (1,0) [0|0] "" Vector__XXX
 SG_ UI_powertrainControlChecksum : 56|8@1+ (1,0) [0|0] "" Vector__XXX

BO_ 821 DIR_info: 8 Vector__XXX
 SG_ DIR_infoIndex M : 0|8@1+ (1,0) [0|0] "" Vector__XXX
 SG_ DIR_appGitHash m17 : 8|56@1+ (1,0) [0|0] "" Vector__XXX
 SG_ DIR_bootGitHash m18 : 8|56@1+ (1,0) [0|0] "" Vector__XXX
 SG_ DIR_buildType m10 : 8|3@1+ (1,0) [0|0] "" Vector__XXX
 SG_ DIR_infoBootLdUdsProtocolVersion m20 : 8|8@1+ (1,0) [0|0] "" Vector__XXX
 SG_ DIR_motorType m12 : 8|6@1+ (1,0) [0|0] "" Vector__XXX
 SG_ DIR_oilPumpBuildType m16 : 8|3@1+ (1,0) [0|0] "" Vector__XXX
 SG_ DIR_oilPumpPcbaId m33 : 8|8@1+ (1,0) [0|0] "" Vector__XXX
 SG_ DIR_platformTyp m19 : 8|8@1+ (1,0) [0|0] "" Vector__XXX
 SG_ DIR_refRotorFlux m35 : 8|16@1+ (0.0001,0) [0|0] "" Vector__XXX
 SG_ DIR_speedWearTotal m36 : 8|8@1+ (0.4,0) [0|0] "" Vector__XXX
 SG_ DIR_subcomponentGitHash m31 : 8|56@1+ (1,0) [0|0] "" Vector__XXX
 SG_ DIR_buildConfigurationId m10 : 16|16@1+ (1,0) [0|0] "" Vector__XXX
 SG_ DIR_oilPumpAppCrc m16 : 16|32@1+ (1,0) [0|0] "" Vector__XXX
 SG_ DIR_oilPumpAssemblyId m33 : 16|8@1+ (1,0) [0|0] "" Vector__XXX
 SG_ DIR_pcbaId m11 : 16|8@1+ (1,0) [0|0] "" Vector__XXX
 SG_ DIR_siliconType m12 : 16|1@1+ (1,0) [0|0] "" Vector__XXX
 SG_ DIR_assemblyId m11 : 24|8@1+ (1,0) [0|0] "" Vector__XXX
 SG_ DIR_mechSafeStateType m12 : 24|2@1+ (1,0) [0|0] "" Vector__XXX
 SG_ DIR_oilPumpUsageId m33 : 24|16@1+ (1,0) [0|0] "" Vector__XXX
 SG_ DIR_refRotorOffset m35 : 24|12@1- (0.1,0) [0|0] "" Vector__XXX
 SG_ DIR_torqueWearTotal m36 : 24|8@1+ (0.02,0) [0|0] "" Vector__XXX
 SG_ DIR_applicationCrc m13 : 32|32@1+ (1,0) [0|0] "" Vector__XXX
 SG_ DIR_bootloaderCrc m20 : 32|32@1+ (1,0) [0|0] "" Vector__XXX
 SG_ DIR_hardwareId m10 : 32|8@1+ (1,0) [0|0] "" Vector__XXX
 SG_ DIR_usageId m11 : 32|16@1+ (1,0) [0|0] "" Vector__XXX
 SG_ DIR_FPGA_version m16 : 48|8@1+ (1,0) [0|0] "" Vector__XXX
 SG_ DIR_componentId m10 : 48|16@1+ (1,0) [0|0] "" Vector__XXX
 SG_ DIR_subUsageId m11 : 48|16@1+ (1,0) [0|0] "" Vector__XXX

BO_ 824 UMC_alertMatrix1: 8 Vector__XXX
 SG_ UMC_a001_gndMonIntrptLineSide : 0|1@1+ (1,0) [0|0] "" Vector__XXX
 SG_ UMC_a002_GFCITripped : 1|1@1+ (1,0) [0|0] "" Vector__XXX
 SG_ UMC_a003_GFCISelfTestFault : 2|1@1+ (1,0) [0|0] "" Vector__XXX
 SG_ UMC_a004_inputOverVoltage : 3|1@1+ (1,0) [0|0] "" Vector__XXX
 SG_ UMC_a005_inputUnderVoltage : 4|1@1+ (1,0) [0|0] "" Vector__XXX
 SG_ UMC_a006_contactorWelded : 5|1@1+ (1,0) [0|0] "" Vector__XXX
 SG_ UMC_a007_pcbaOT : 6|1@1+ (1,0) [0|0] "" Vector__XXX
 SG_ UMC_a008_wallPlugOT : 7|1@1+ (1,0) [0|0] "" Vector__XXX
 SG_ UMC_a009_vehConnOT : 8|1@1+ (1,0) [0|0] "" Vector__XXX
 SG_ UMC_a010_inputOT : 9|1@1+ (1,0) [0|0] "" Vector__XXX
 SG_ UMC_a011_proxDisconnected : 10|1@1+ (1,0) [0|0] "" Vector__XXX
 SG_ UMC_a012_pilotFault : 11|1@1+ (1,0) [0|0] "" Vector__XXX
 SG_ UMC_a013_SA_Temperature : 12|1@1+ (1,0) [0|0] "" Vector__XXX
 SG_ UMC_a014_SA_Genealogy : 13|1@1+ (1,0) [0|0] "" Vector__XXX
 SG_ UMC_a015_SA_Connection : 14|1@1+ (1,0) [0|0] "" Vector__XXX
 SG_ UMC_a016_pcbaOTFoldback : 15|1@1+ (1,0) [0|0] "" Vector__XXX
 SG_ UMC_a017_wallPlugOTFoldback : 16|1@1+ (1,0) [0|0] "" Vector__XXX
 SG_ UMC_a018_vehConnOTFoldback : 17|1@1+ (1,0) [0|0] "" Vector__XXX
 SG_ UMC_a019_inputOTFoldback : 18|1@1+ (1,0) [0|0] "" Vector__XXX
 SG_ UMC_a020_applicationCRC : 19|1@1+ (1,0) [0|0] "" Vector__XXX
 SG_ UMC_a021_dataBus : 20|1@1+ (1,0) [0|0] "" Vector__XXX
 SG_ UMC_a022_criticalRAM : 21|1@1+ (1,0) [0|0] "" Vector__XXX
 SG_ UMC_a023_adcSelfTest : 22|1@1+ (1,0) [0|0] "" Vector__XXX
 SG_ UMC_a024_gndResistanceHigh : 23|1@1+ (1,0) [0|0] "" Vector__XXX
 SG_ UMC_a025_cntrOpenExpectedClose : 24|1@1+ (1,0) [0|0] "" Vector__XXX
 SG_ UMC_a026_vRefOutOfRange : 25|1@1+ (1,0) [0|0] "" Vector__XXX
 SG_ UMC_a027_watchdogExpired : 26|1@1+ (1,0) [0|0] "" Vector__XXX
 SG_ UMC_a028_processorBooted : 27|1@1+ (1,0) [0|0] "" Vector__XXX
 SG_ UMC_a029_acPowerLoss : 28|1@1+ (1,0) [0|0] "" Vector__XXX
 SG_ UMC_a030_acLostPllLock : 29|1@1+ (1,0) [0|0] "" Vector__XXX
 SG_ UMC_a031_relayCoilVIrrational : 30|1@1+ (1,0) [0|0] "" Vector__XXX
 SG_ UMC_a032_chcVitalsRequestFailure : 31|1@1+ (1,0) [0|0] "" Vector__XXX
 SG_ UMC_a033_chcUpdateFault : 32|1@1+ (1,0) [0|0] "" Vector__XXX
 SG_ UMC_a034_v2lSAUnsupported : 33|1@1+ (1,0) [0|0] "" Vector__XXX
 SG_ UMC_a035_v2lHVACDetected : 34|1@1+ (1,0) [0|0] "" Vector__XXX
 SG_ UMC_a037_GFCICalibration : 36|1@1+ (1,0) [0|0] "" Vector__XXX
 SG_ UMC_a038_chcVitalsFault : 37|1@1+ (1,0) [0|0] "" Vector__XXX
 SG_ UMC_a039_inputOverCurrent : 38|1@1+ (1,0) [0|0] "" Vector__XXX
 SG_ UMC_a040_gndDisconnected : 39|1@1+ (1,0) [0|0] "" Vector__XXX
 SG_ UMC_a041_handleTempIrrational : 40|1@1+ (1,0) [0|0] "" Vector__XXX

BO_ 825 VCSEC_authentication: 8 Vector__XXX
 SG_ VCSEC_BLEConnectionCounter : 0|4@1+ (1,0) [0|0] "" Vector__XXX
 SG_ VCSEC_authRejectionReason : 4|3@1+ (1,0) [0|0] "" Vector__XXX
 SG_ VCSEC_IDRequested : 7|1@1+ (1,0) [0|0] "" Vector__XXX
 SG_ VCSEC_operationMode : 8|2@1+ (1,0) [0|0] "" Vector__XXX
 SG_ VCSEC_vehicleLockStatus : 12|4@1+ (1,0) [0|0] "" Vector__XXX
 SG_ VCSEC_authenticationStatus : 16|2@1+ (1,0) [0|0] "" Vector__XXX
 SG_ VCSEC_chargePortLockStatus : 18|1@1+ (1,0) [0|0] "" Vector__XXX
 SG_ VCSEC_leftFrontLockStatus : 19|1@1+ (1,0) [0|0] "" Vector__XXX
 SG_ VCSEC_leftRearLockStatus : 20|1@1+ (1,0) [0|0] "" Vector__XXX
 SG_ VCSEC_rightFrontLockStatus : 21|1@1+ (1,0) [0|0] "" Vector__XXX
 SG_ VCSEC_rightRearLockStatus : 22|1@1+ (1,0) [0|0] "" Vector__XXX
 SG_ VCSEC_trunkLockStatus : 23|1@1+ (1,0) [0|0] "" Vector__XXX
 SG_ VCSEC_lockRequestType : 24|5@1+ (1,0) [0|0] "" Vector__XXX
 SG_ VCSEC_summonRequest : 29|3@1+ (1,0) [0|0] "" Vector__XXX
 SG_ VCSEC_3rdPartyPLGRequest : 32|2@1+ (1,0) [0|0] "" Vector__XXX
 SG_ VCSEC_3rdPartyFrunkPLGRequest : 34|2@1+ (1,0) [0|0] "" Vector__XXX
 SG_ VCSEC_MCUCommandType : 36|3@1+ (1,0) [0|0] "" Vector__XXX
 SG_ VCSEC_frunkLockStatus : 39|1@1+ (1,0) [0|0] "" Vector__XXX
 SG_ VCSEC_usingModifiedMACAddress : 40|1@1+ (1,0) [0|0] "" Vector__XXX
 SG_ VCSEC_isKeyWithinSummonRange : 41|1@1+ (1,0) [0|0] "" Vector__XXX
 SG_ VCSEC_isBLEDeviceWithinSummonRange : 42|1@1+ (1,0) [0|0] "" Vector__XXX
 SG_ VCSEC_alarmStatus : 43|4@1+ (1,0) [0|0] "" Vector__XXX
 SG_ VCSEC_serviceDiagnosticRequest : 47|1@1+ (1,0) [0|0] "" Vector__XXX
 SG_ VCSEC_immobilizerState : 48|3@1+ (1,0) [0|0] "" Vector__XXX
 SG_ VCSEC_lockIndicationRequest : 51|3@1+ (1,0) [0|0] "" Vector__XXX
 SG_ VCSEC_simpleLockStatus : 54|2@1+ (1,0) [0|0] "" Vector__XXX
 SG_ VCSEC_keyChannelIndexed : 56|4@1+ (1,0) [0|0] "" Vector__XXX
 SG_ VCSEC_authRequested : 60|1@1+ (1,0) [0|0] "" Vector__XXX
 SG_ VCSEC_remoteStartActive : 61|2@1+ (1,0) [0|0] "" Vector__XXX
 SG_ VCSEC_keyPairDesired : 63|1@1+ (1,0) [0|0] "" Vector__XXX

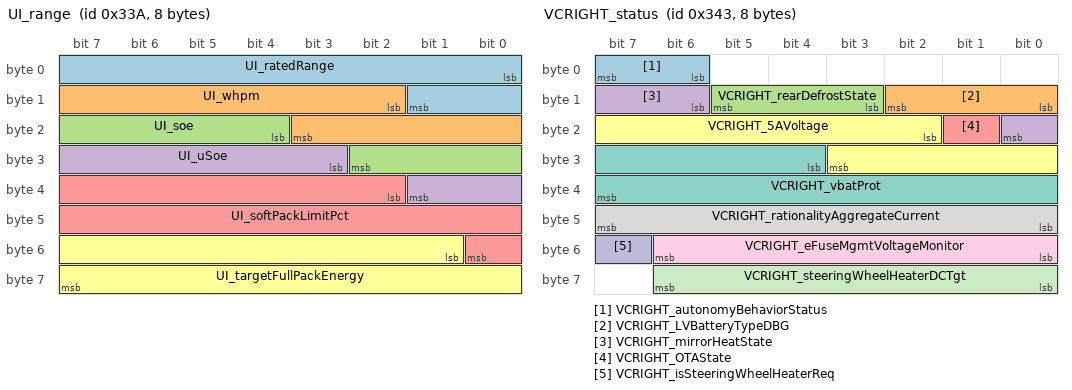
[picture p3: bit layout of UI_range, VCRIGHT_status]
BO_ 826 UI_range: 8 Vector__XXX
 SG_ UI_ratedRange : 0|10@1+ (1,0) [0|0] "" Vector__XXX
 SG_ UI_whpm : 10|10@1+ (1,0) [0|0] "" Vector__XXX
 SG_ UI_soe : 20|7@1+ (1,0) [0|0] "" Vector__XXX
 SG_ UI_uSoe : 27|7@1+ (1,0) [0|0] "" Vector__XXX
 SG_ UI_softPackLimitPct : 34|15@1+ (0.0030518509475997192,0) [0|0] "" Vector__XXX
 SG_ UI_targetFullPackEnergy : 49|15@1+ (0.0061037018951994385,0) [0|0] "" Vector__XXX

BO_ 829 CP_plcInfo: 8 Vector__XXX
 SG_ CP_plcFwCrc : 0|32@1+ (1,0) [0|0] "" Vector__XXX
 SG_ CP_plcPibCrc : 32|32@1+ (1,0) [0|0] "" Vector__XXX

BO_ 832 VCFRONT_alertMatrix: 8 Vector__XXX
 SG_ VCFRONT_matrixIndex M : 0|4@1+ (1,0) [0|0] "" Vector__XXX
 SG_ VCFRONT_a001_WatchdogReset m0 : 4|1@1+ (1,0) [0|0] "" Vector__XXX
 SG_ VCFRONT_a061_XCPConnected m1 : 4|1@1+ (1,0) [0|0] "" Vector__XXX
 SG_ VCFRONT_a121_pumpBatICLatchFault m2 : 4|1@1+ (1,0) [0|0] "" Vector__XXX
 SG_ VCFRONT_a181_homelinkMIA m3 : 4|1@1+ (1,0) [0|0] "" Vector__XXX
 SG_ VCFRONT_a301_wipersFactoryDisabled m5 : 4|1@1+ (1,0) [0|0] "" Vector__XXX
 SG_ VCFRONT_a361_washerFluidLowMomentary m6 : 4|1@1+ (1,0) [0|0] "" Vector__XXX
 SG_ VCFRONT_a421_leftHeadlampUartCondition m7 : 4|1@1+ (1,0) [0|0] "" Vector__XXX
 SG_ VCFRONT_a481_vnf1048SelfTestFailure m8 : 4|1@1+ (1,0) [0|0] "" Vector__XXX
 SG_ VCFRONT_a541_LVBatteryChargeOCLevel1 m9 : 4|1@1+ (1,0) [0|0] "" Vector__XXX
 SG_ VCFRONT_a601_autopilotAirPurgeLimitReached m10 : 4|1@1+ (1,0) [0|0] "" Vector__XXX
 SG_ VCFRONT_a661_mculessLeftHeadlampCurrentAlertDbg m11 : 4|1@1+ (1,0) [0|0] "" Vector__XXX
 SG_ VCFRONT_a002_PowerLossReset m0 : 5|1@1+ (1,0) [0|0] "" Vector__XXX
 SG_ VCFRONT_a062_XCPWasConnected m1 : 5|1@1+ (1,0) [0|0] "" Vector__XXX
 SG_ VCFRONT_a122_pumpBatICWarning m2 : 5|1@1+ (1,0) [0|0] "" Vector__XXX
 SG_ VCFRONT_a182_replaceLVBattery m3 : 5|1@1+ (1,0) [0|0] "" Vector__XXX
 SG_ VCFRONT_a242_drveBlckdVltgeTooLow m4 : 5|1@1+ (1,0) [0|0] "" Vector__XXX
 SG_ VCFRONT_a302_wiperCommError m5 : 5|1@1+ (1,0) [0|0] "" Vector__XXX
 SG_ VCFRONT_a362_TLVBMS_AllSocCorrectionTimeout m6 : 5|1@1+ (1,0) [0|0] "" Vector__XXX
 SG_ VCFRONT_a482_rightHeadlampMigrationDebug m8 : 5|1@1+ (1,0) [0|0] "" Vector__XXX
 SG_ VCFRONT_a542_refrigerantReclaim m9 : 5|1@1+ (1,0) [0|0] "" Vector__XXX
 SG_ VCFRONT_a662_mculessRightHeadlampCurrentAlertDbg m11 : 5|1@1+ (1,0) [0|0] "" Vector__XXX
 SG_ VCFRONT_a003_SWAssertion m0 : 6|1@1+ (1,0) [0|0] "" Vector__XXX
 SG_ VCFRONT_a063_SwitchFault m1 : 6|1@1+ (1,0) [0|0] "" Vector__XXX
 SG_ VCFRONT_a123_pumpPtICLatchFault m2 : 6|1@1+ (1,0) [0|0] "" Vector__XXX
 SG_ VCFRONT_a183_replaceLVBattery2 m3 : 6|1@1+ (1,0) [0|0] "" Vector__XXX
 SG_ VCFRONT_a243_LVOverchargeInstc m4 : 6|1@1+ (1,0) [0|0] "" Vector__XXX
 SG_ VCFRONT_a303_frunkAccessPostActive m5 : 6|1@1+ (1,0) [0|0] "" Vector__XXX
 SG_ VCFRONT_a363_TLVBMS_BleedBasedWeakShort m6 : 6|1@1+ (1,0) [0|0] "" Vector__XXX
 SG_ VCFRONT_a423_TLVBMS_BrickUnderVoltageFault m7 : 6|1@1+ (1,0) [0|0] "" Vector__XXX
 SG_ VCFRONT_a483_leftHeadlampStepperMotorFault m8 : 6|1@1+ (1,0) [0|0] "" Vector__XXX
 SG_ VCFRONT_a543_compressorLowFlowDeliveryDetected m9 : 6|1@1+ (1,0) [0|0] "" Vector__XXX
 SG_ VCFRONT_a663_leftHeadlampUartWaterMarkWarning m11 : 6|1@1+ (1,0) [0|0] "" Vector__XXX
 SG_ VCFRONT_a004_adaptiveHeadlightsUnavailable m0 : 7|1@1+ (1,0) [0|0] "" Vector__XXX
 SG_ VCFRONT_a064_busSleepReqTimeout m1 : 7|1@1+ (1,0) [0|0] "" Vector__XXX
 SG_ VCFRONT_a124_pumpPtICWarning m2 : 7|1@1+ (1,0) [0|0] "" Vector__XXX
 SG_ VCFRONT_a184_cabinCoolingPerformanceAbnormal m3 : 7|1@1+ (1,0) [0|0] "" Vector__XXX
 SG_ VCFRONT_a244_sleepBypassFault m4 : 7|1@1+ (1,0) [0|0] "" Vector__XXX
 SG_ VCFRONT_a304_frunkReleaseFailed m5 : 7|1@1+ (1,0) [0|0] "" Vector__XXX
 SG_ VCFRONT_a364_heaterTypeEstimationChanged m6 : 7|1@1+ (1,0) [0|0] "" Vector__XXX
 SG_ VCFRONT_a424_TLVBMS_BrickUnderVoltageOcv m7 : 7|1@1+ (1,0) [0|0] "" Vector__XXX
 SG_ VCFRONT_a484_headlampLevelingRideHeightDebug m8 : 7|1@1+ (1,0) [0|0] "" Vector__XXX
 SG_ VCFRONT_a544_LVBatteryCommsBusTurnedOff m9 : 7|1@1+ (1,0) [0|0] "" Vector__XXX
 SG_ VCFRONT_a664_rightHeadlampUartWaterMarkWarning m11 : 7|1@1+ (1,0) [0|0] "" Vector__XXX
 SG_ VCFRONT_a005_CANTXError m0 : 8|1@1+ (1,0) [0|0] "" Vector__XXX
 SG_ VCFRONT_a125_thmlFanICLatchFault m2 : 8|1@1+ (1,0) [0|0] "" Vector__XXX
 SG_ VCFRONT_a185_washerFluidLow m3 : 8|1@1+ (1,0) [0|0] "" Vector__XXX
 SG_ VCFRONT_a245_pump1EFuseFault m4 : 8|1@1+ (1,0) [0|0] "" Vector__XXX
 SG_ VCFRONT_a305_frunkPriOverCurrent m5 : 8|1@1+ (1,0) [0|0] "" Vector__XXX
 SG_ VCFRONT_a365_burnInRoutineEntered m6 : 8|1@1+ (1,0) [0|0] "" Vector__XXX
 SG_ VCFRONT_a425_TLVBMS_BusVoltageTooHigh m7 : 8|1@1+ (1,0) [0|0] "" Vector__XXX
 SG_ VCFRONT_a485_leftHeadlampMigrationDebug m8 : 8|1@1+ (1,0) [0|0] "" Vector__XXX
 SG_ VCFRONT_a545_LVBatteryTypeUnknown m9 : 8|1@1+ (1,0) [0|0] "" Vector__XXX
 SG_ VCFRONT_a605_sleepBypassPowerOff m10 : 8|1@1+ (1,0) [0|0] "" Vector__XXX
 SG_ VCFRONT_a665_leftHeadlampRetryInfo m11 : 8|1@1+ (1,0) [0|0] "" Vector__XXX
 SG_ VCFRONT_a006_CANTX_cyclicError m0 : 9|1@1+ (1,0) [0|0] "" Vector__XXX
 SG_ VCFRONT_a126_thmlFanICWarning m2 : 9|1@1+ (1,0) [0|0] "" Vector__XXX
 SG_ VCFRONT_a186_noDriveChgCableCon m3 : 9|1@1+ (1,0) [0|0] "" Vector__XXX
 SG_ VCFRONT_a246_pump2EFuseFault m4 : 9|1@1+ (1,0) [0|0] "" Vector__XXX
 SG_ VCFRONT_a306_frunkPriUnderCurrent m5 : 9|1@1+ (1,0) [0|0] "" Vector__XXX
 SG_ VCFRONT_a366_burnInRoutineExited m6 : 9|1@1+ (1,0) [0|0] "" Vector__XXX
 SG_ VCFRONT_a426_TLVBMS_BusVoltageTooLow m7 : 9|1@1+ (1,0) [0|0] "" Vector__XXX
 SG_ VCFRONT_a486_mcuGraphicsEFuseFault m8 : 9|1@1+ (1,0) [0|0] "" Vector__XXX
 SG_ VCFRONT_a546_leftLowOrHighBeamLightCondition m9 : 9|1@1+ (1,0) [0|0] "" Vector__XXX
 SG_ VCFRONT_a606_chillerBattHeatingExit m10 : 9|1@1+ (1,0) [0|0] "" Vector__XXX
 SG_ VCFRONT_a666_rightHeadlampRetryInfo m11 : 9|1@1+ (1,0) [0|0] "" Vector__XXX
 SG_ VCFRONT_a127_vcleftEFuseTrip m2 : 10|1@1+ (1,0) [0|0] "" Vector__XXX
 SG_ VCFRONT_a187_busesNotSleeping m3 : 10|1@1+ (1,0) [0|0] "" Vector__XXX
 SG_ VCFRONT_a247_evapSolenoidFault m4 : 10|1@1+ (1,0) [0|0] "" Vector__XXX
 SG_ VCFRONT_a307_frunkSecOverCurrent m5 : 10|1@1+ (1,0) [0|0] "" Vector__XXX
 SG_ VCFRONT_a367_dischargeRoutineEntered m6 : 10|1@1+ (1,0) [0|0] "" Vector__XXX
 SG_ VCFRONT_a427_TLVBMS_CacChange m7 : 10|1@1+ (1,0) [0|0] "" Vector__XXX
 SG_ VCFRONT_a487_leftHeadlampLastPositionUpdate m8 : 10|1@1+ (1,0) [0|0] "" Vector__XXX
 SG_ VCFRONT_a547_postCrashLoadShed m9 : 10|1@1+ (1,0) [0|0] "" Vector__XXX
 SG_ VCFRONT_a607_sleepPowerDebug m10 : 10|1@1+ (1,0) [0|0] "" Vector__XXX
 SG_ VCFRONT_a667_leftHeadlampRegionOrSideMismatch m11 : 10|1@1+ (1,0) [0|0] "" Vector__XXX
 SG_ VCFRONT_a008_adaptiveHeadlightsUnavailableStalk m0 : 11|1@1+ (1,0) [0|0] "" Vector__XXX
 SG_ VCFRONT_a128_vcrightEFuseTrip m2 : 11|1@1+ (1,0) [0|0] "" Vector__XXX
 SG_ VCFRONT_a188_sleepFailed m3 : 11|1@1+ (1,0) [0|0] "" Vector__XXX
 SG_ VCFRONT_a248_voltageOutOfSpec m4 : 11|1@1+ (1,0) [0|0] "" Vector__XXX
 SG_ VCFRONT_a308_frunkSecUnderCurrent m5 : 11|1@1+ (1,0) [0|0] "" Vector__XXX
 SG_ VCFRONT_a368_dischargeRoutineExited m6 : 11|1@1+ (1,0) [0|0] "" Vector__XXX
 SG_ VCFRONT_a428_TLVBMS_CacImbalance m7 : 11|1@1+ (1,0) [0|0] "" Vector__XXX
 SG_ VCFRONT_a488_rightHeadlampStepperMotorFault m8 : 11|1@1+ (1,0) [0|0] "" Vector__XXX
 SG_ VCFRONT_a548_HVFaultLoadShed m9 : 11|1@1+ (1,0) [0|0] "" Vector__XXX
 SG_ VCFRONT_a608_TLVBMS_BleedFetFailure m10 : 11|1@1+ (1,0) [0|0] "" Vector__XXX
 SG_ VCFRONT_a668_rightHeadlampRegionOrSideMismatch m11 : 11|1@1+ (1,0) [0|0] "" Vector__XXX
 SG_ VCFRONT_a009_LCCPurgeAttempted m0 : 12|1@1+ (1,0) [0|0] "" Vector__XXX
 SG_ VCFRONT_a129_pcsEFuseTrip m2 : 12|1@1+ (1,0) [0|0] "" Vector__XXX
 SG_ VCFRONT_a189_IBSMIA m3 : 12|1@1+ (1,0) [0|0] "" Vector__XXX
 SG_ VCFRONT_a249_coolantValveBadMode m4 : 12|1@1+ (1,0) [0|0] "" Vector__XXX
 SG_ VCFRONT_a309_frunkEmergencyReleasePressed m5 : 12|1@1+ (1,0) [0|0] "" Vector__XXX
 SG_ VCFRONT_a369_reducedPowerDischarge m6 : 12|1@1+ (1,0) [0|0] "" Vector__XXX
 SG_ VCFRONT_a429_TLVBMS_CapacityTestResults m7 : 12|1@1+ (1,0) [0|0] "" Vector__XXX
 SG_ VCFRONT_a489_ValveStuckFlagged m8 : 12|1@1+ (1,0) [0|0] "" Vector__XXX
 SG_ VCFRONT_a609_autopilotDriveNotAuthed m10 : 12|1@1+ (1,0) [0|0] "" Vector__XXX
 SG_ VCFRONT_a669_thermalHVPowerBudgetActive m11 : 12|1@1+ (1,0) [0|0] "" Vector__XXX
 SG_ VCFRONT_a010_ExtSupplyVoltError m0 : 13|1@1+ (1,0) [0|0] "" Vector__XXX
 SG_ VCFRONT_a130_epas3pEFuseTrip m2 : 13|1@1+ (1,0) [0|0] "" Vector__XXX
 SG_ VCFRONT_a190_linSchedulingInfo m3 : 13|1@1+ (1,0) [0|0] "" Vector__XXX
 SG_ VCFRONT_a250_headlampsNotAimed m4 : 13|1@1+ (1,0) [0|0] "" Vector__XXX
 SG_ VCFRONT_a310_vcleftOvertempSlope m5 : 13|1@1+ (1,0) [0|0] "" Vector__XXX
 SG_ VCFRONT_a370_noLVSupportSocTooLow m6 : 13|1@1+ (1,0) [0|0] "" Vector__XXX
 SG_ VCFRONT_a430_TLVBMS_ChargeCurrentLimitExceeded m7 : 13|1@1+ (1,0) [0|0] "" Vector__XXX
 SG_ VCFRONT_a490_coolantPumpsNotIdentified m8 : 13|1@1+ (1,0) [0|0] "" Vector__XXX
 SG_ VCFRONT_a610_frunkOpenFailureMetricSet m10 : 13|1@1+ (1,0) [0|0] "" Vector__XXX
 SG_ VCFRONT_a670_TLVBMS_EfuseStateIrrational m11 : 13|1@1+ (1,0) [0|0] "" Vector__XXX
 SG_ VCFRONT_a131_epas3sEFuseTrip m2 : 14|1@1+ (1,0) [0|0] "" Vector__XXX
 SG_ VCFRONT_a191_exitDriveLowLVBusVoltage m3 : 14|1@1+ (1,0) [0|0] "" Vector__XXX
 SG_ VCFRONT_a251_UIWakeupTrigger m4 : 14|1@1+ (1,0) [0|0] "" Vector__XXX
 SG_ VCFRONT_a311_vcrightOvertempSlope m5 : 14|1@1+ (1,0) [0|0] "" Vector__XXX
 SG_ VCFRONT_a371_failureToPrechargeRisk m6 : 14|1@1+ (1,0) [0|0] "" Vector__XXX
 SG_ VCFRONT_a431_TLVBMS_ChargeOverCurrent m7 : 14|1@1+ (1,0) [0|0] "" Vector__XXX
 SG_ VCFRONT_a491_rightHeadlampLastPositionUpdate m8 : 14|1@1+ (1,0) [0|0] "" Vector__XXX
 SG_ VCFRONT_a551_leftHeadlampSoftShort m9 : 14|1@1+ (1,0) [0|0] "" Vector__XXX
 SG_ VCFRONT_a611_poorRadiatorHeatRejection m10 : 14|1@1+ (1,0) [0|0] "" Vector__XXX
 SG_ VCFRONT_a012_CPUReset m0 : 15|1@1+ (1,0) [0|0] "" Vector__XXX
 SG_ VCFRONT_a132_iBoosterEFuseTrip m2 : 15|1@1+ (1,0) [0|0] "" Vector__XXX
 SG_ VCFRONT_a192_vehicleLoadShed m3 : 15|1@1+ (1,0) [0|0] "" Vector__XXX
 SG_ VCFRONT_a252_controllerWakeup m4 : 15|1@1+ (1,0) [0|0] "" Vector__XXX
 SG_ VCFRONT_a312_pcsOvertempSlope m5 : 15|1@1+ (1,0) [0|0] "" Vector__XXX
 SG_ VCFRONT_a372_TLVBMS_BmbHwOverVoltageFault m6 : 15|1@1+ (1,0) [0|0] "" Vector__XXX
 SG_ VCFRONT_a432_TLVBMS_ChargeRegulationFault m7 : 15|1@1+ (1,0) [0|0] "" Vector__XXX
 SG_ VCFRONT_a492_TLVBMS_SocImbalance m8 : 15|1@1+ (1,0) [0|0] "" Vector__XXX
 SG_ VCFRONT_a552_eFuseSelfTestFailure m9 : 15|1@1+ (1,0) [0|0] "" Vector__XXX
 SG_ VCFRONT_a612_LVUnhealthyLoadShed m10 : 15|1@1+ (1,0) [0|0] "" Vector__XXX
 SG_ VCFRONT_a013_AlertManagerFault m0 : 16|1@1+ (1,0) [0|0] "" Vector__XXX
 SG_ VCFRONT_a133_espEFuseTrip m2 : 16|1@1+ (1,0) [0|0] "" Vector__XXX
 SG_ VCFRONT_a193_mcuAudioRetry m3 : 16|1@1+ (1,0) [0|0] "" Vector__XXX
 SG_ VCFRONT_a253_maxChrgeSssionTmeout m4 : 16|1@1+ (1,0) [0|0] "" Vector__XXX
 SG_ VCFRONT_a313_epas3pOvertempSlope m5 : 16|1@1+ (1,0) [0|0] "" Vector__XXX
 SG_ VCFRONT_a373_chillerControlFlooding m6 : 16|1@1+ (1,0) [0|0] "" Vector__XXX
 SG_ VCFRONT_a433_TLVBMS_ConfigFromBmbModIdFailed m7 : 16|1@1+ (1,0) [0|0] "" Vector__XXX
 SG_ VCFRONT_a493_TLVBMS_SocImbalanceWarning m8 : 16|1@1+ (1,0) [0|0] "" Vector__XXX
 SG_ VCFRONT_a553_rightHeadlampSoftShort m9 : 16|1@1+ (1,0) [0|0] "" Vector__XXX
 SG_ VCFRONT_a613_selfTestsBlockingDrive m10 : 16|1@1+ (1,0) [0|0] "" Vector__XXX
 SG_ VCFRONT_a134_fusedHighEFuseTrip m2 : 17|1@1+ (1,0) [0|0] "" Vector__XXX
 SG_ VCFRONT_a194_iBoosterRetry m3 : 17|1@1+ (1,0) [0|0] "" Vector__XXX
 SG_ VCFRONT_a254_pumpBatStopped m4 : 17|1@1+ (1,0) [0|0] "" Vector__XXX
 SG_ VCFRONT_a314_epas3sOvertempSlope m5 : 17|1@1+ (1,0) [0|0] "" Vector__XXX
 SG_ VCFRONT_a374_lccInletSolenoidFault m6 : 17|1@1+ (1,0) [0|0] "" Vector__XXX
 SG_ VCFRONT_a434_TLVBMS_ConfigInitFailed m7 : 17|1@1+ (1,0) [0|0] "" Vector__XXX
 SG_ VCFRONT_a494_LVBatteryTempBlockingOTA m8 : 17|1@1+ (1,0) [0|0] "" Vector__XXX
 SG_ VCFRONT_a614_coolantSysDriverlessSelfTest m10 : 17|1@1+ (1,0) [0|0] "" Vector__XXX
 SG_ VCFRONT_a015_NVMMError m0 : 18|1@1+ (1,0) [0|0] "" Vector__XXX
 SG_ VCFRONT_a135_coolantLevelLow m2 : 18|1@1+ (1,0) [0|0] "" Vector__XXX
 SG_ VCFRONT_a195_drveBlckdVltgeTooHgh m3 : 18|1@1+ (1,0) [0|0] "" Vector__XXX
 SG_ VCFRONT_a255_pumpPtStopped m4 : 18|1@1+ (1,0) [0|0] "" Vector__XXX
 SG_ VCFRONT_a315_iboosterOvertempSlope m5 : 18|1@1+ (1,0) [0|0] "" Vector__XXX
 SG_ VCFRONT_a375_refVoltageOutOfSpec m6 : 18|1@1+ (1,0) [0|0] "" Vector__XXX
 SG_ VCFRONT_a435_TLVBMS_DchgCurrentLimitExceeded m7 : 18|1@1+ (1,0) [0|0] "" Vector__XXX
 SG_ VCFRONT_a495_LVBatteryRecoveryBlocked m8 : 18|1@1+ (1,0) [0|0] "" Vector__XXX
 SG_ VCFRONT_a555_LVBatteryCellRebalancing m9 : 18|1@1+ (1,0) [0|0] "" Vector__XXX
 SG_ VCFRONT_a615_TLVBMS_BatteryHeaterFault m10 : 18|1@1+ (1,0) [0|0] "" Vector__XXX
 SG_ VCFRONT_a016_NVMMRecordError m0 : 19|1@1+ (1,0) [0|0] "" Vector__XXX
 SG_ VCFRONT_a136_refrigDischTempSns m2 : 19|1@1+ (1,0) [0|0] "" Vector__XXX
 SG_ VCFRONT_a196_discnctdLVBattery m3 : 19|1@1+ (1,0) [0|0] "" Vector__XXX
 SG_ VCFRONT_a256_compTornShaftSeal m4 : 19|1@1+ (1,0) [0|0] "" Vector__XXX
 SG_ VCFRONT_a316_espOvertempSlope m5 : 19|1@1+ (1,0) [0|0] "" Vector__XXX
 SG_ VCFRONT_a376_controllerWakeupDebug m6 : 19|1@1+ (1,0) [0|0] "" Vector__XXX
 SG_ VCFRONT_a436_TLVBMS_DischargeOverCurrent m7 : 19|1@1+ (1,0) [0|0] "" Vector__XXX
 SG_ VCFRONT_a496_LVBatteryExitDriveWarning m8 : 19|1@1+ (1,0) [0|0] "" Vector__XXX
 SG_ VCFRONT_a556_falseTriggerOfDiscnctdBatteryTest m9 : 19|1@1+ (1,0) [0|0] "" Vector__XXX
 SG_ VCFRONT_a017_NVMMStatusDbg m0 : 20|1@1+ (1,0) [0|0] "" Vector__XXX
 SG_ VCFRONT_a137_refrigDischPresSns m2 : 20|1@1+ (1,0) [0|0] "" Vector__XXX
 SG_ VCFRONT_a197_prechargeDCRData3 m3 : 20|1@1+ (1,0) [0|0] "" Vector__XXX
 SG_ VCFRONT_a257_portExpanderVOR m4 : 20|1@1+ (1,0) [0|0] "" Vector__XXX
 SG_ VCFRONT_a317_vbatFusedOvertempSlope m5 : 20|1@1+ (1,0) [0|0] "" Vector__XXX
 SG_ VCFRONT_a377_wiperParkFault m6 : 20|1@1+ (1,0) [0|0] "" Vector__XXX
 SG_ VCFRONT_a437_TLVBMS_NvmRegistrationError m7 : 20|1@1+ (1,0) [0|0] "" Vector__XXX
 SG_ VCFRONT_a497_LVBatteryWarnDisconnect m8 : 20|1@1+ (1,0) [0|0] "" Vector__XXX
 SG_ VCFRONT_a138_refrigSuctTempSns m2 : 21|1@1+ (1,0) [0|0] "" Vector__XXX
 SG_ VCFRONT_a198_PRVCANOverterminate m3 : 21|1@1+ (1,0) [0|0] "" Vector__XXX
 SG_ VCFRONT_a258_resistanceEstimationRun m4 : 21|1@1+ (1,0) [0|0] "" Vector__XXX
 SG_ VCFRONT_a318_vcleftOvertempMax m5 : 21|1@1+ (1,0) [0|0] "" Vector__XXX
 SG_ VCFRONT_a378_wiperECUDebug m6 : 21|1@1+ (1,0) [0|0] "" Vector__XXX
 SG_ VCFRONT_a438_TLVBMS_PackOverTemperatureFault m7 : 21|1@1+ (1,0) [0|0] "" Vector__XXX
 SG_ VCFRONT_a498_TLVBMS_ImpedanceTestResults m8 : 21|1@1+ (1,0) [0|0] "" Vector__XXX
 SG_ VCFRONT_a558_rightHeadlampAimingDebug m9 : 21|1@1+ (1,0) [0|0] "" Vector__XXX
 SG_ VCFRONT_a618_cabinCoolingCapacityLimited m10 : 21|1@1+ (1,0) [0|0] "" Vector__XXX
 SG_ VCFRONT_a139_refrigSuctPresSns m2 : 22|1@1+ (1,0) [0|0] "" Vector__XXX
 SG_ VCFRONT_a199_PRVCANUndertrminate m3 : 22|1@1+ (1,0) [0|0] "" Vector__XXX
 SG_ VCFRONT_a259_LVVoltageDropOnHighLoadCurrent m4 : 22|1@1+ (1,0) [0|0] "" Vector__XXX
 SG_ VCFRONT_a319_vcrightOvertempMax m5 : 22|1@1+ (1,0) [0|0] "" Vector__XXX
 SG_ VCFRONT_a379_shortedCellTestRunDebug m6 : 22|1@1+ (1,0) [0|0] "" Vector__XXX
 SG_ VCFRONT_a439_TLVBMS_PackOverTemperatureWarning m7 : 22|1@1+ (1,0) [0|0] "" Vector__XXX
 SG_ VCFRONT_a499_loadShedPumpFlowRequest m8 : 22|1@1+ (1,0) [0|0] "" Vector__XXX
 SG_ VCFRONT_a559_LVBatteryLowSOC m9 : 22|1@1+ (1,0) [0|0] "" Vector__XXX
 SG_ VCFRONT_a619_frunkSwitchReleaseTimeDBG m10 : 22|1@1+ (1,0) [0|0] "" Vector__XXX
 SG_ VCFRONT_a140_coolantTempPtSns m2 : 23|1@1+ (1,0) [0|0] "" Vector__XXX
 SG_ VCFRONT_a200_vcleftSelfTestFail m3 : 23|1@1+ (1,0) [0|0] "" Vector__XXX
 SG_ VCFRONT_a260_deadLVBattery m4 : 23|1@1+ (1,0) [0|0] "" Vector__XXX
 SG_ VCFRONT_a320_pcsOvertempMax m5 : 23|1@1+ (1,0) [0|0] "" Vector__XXX
 SG_ VCFRONT_a380_chillerExvWarning m6 : 23|1@1+ (1,0) [0|0] "" Vector__XXX
 SG_ VCFRONT_a440_TLVBMS_PackSNInvalidForNvm m7 : 23|1@1+ (1,0) [0|0] "" Vector__XXX
 SG_ VCFRONT_a500_eFuseASICStateMismatch m8 : 23|1@1+ (1,0) [0|0] "" Vector__XXX
 SG_ VCFRONT_a560_compressorHighSuperheat m9 : 23|1@1+ (1,0) [0|0] "" Vector__XXX
 SG_ VCFRONT_a021_TaskSchedulerError m0 : 24|1@1+ (1,0) [0|0] "" Vector__XXX
 SG_ VCFRONT_a141_coolantTempBatSns m2 : 24|1@1+ (1,0) [0|0] "" Vector__XXX
 SG_ VCFRONT_a201_vcrightSelfTestFail m3 : 24|1@1+ (1,0) [0|0] "" Vector__XXX
 SG_ VCFRONT_a261_vcleftVoltageMismatch m4 : 24|1@1+ (1,0) [0|0] "" Vector__XXX
 SG_ VCFRONT_a321_epas3pOvertempMax m5 : 24|1@1+ (1,0) [0|0] "" Vector__XXX
 SG_ VCFRONT_a381_evaporatorExvWarning m6 : 24|1@1+ (1,0) [0|0] "" Vector__XXX
 SG_ VCFRONT_a441_TLVBMS_ResetNeededForNvmPackSwap m7 : 24|1@1+ (1,0) [0|0] "" Vector__XXX
 SG_ VCFRONT_a501_vnf1048ConfigurationMismatch m8 : 24|1@1+ (1,0) [0|0] "" Vector__XXX
 SG_ VCFRONT_a561_LVBMSEFuseOvertemperature m9 : 24|1@1+ (1,0) [0|0] "" Vector__XXX
 SG_ VCFRONT_a022_TaskInitError m0 : 25|1@1+ (1,0) [0|0] "" Vector__XXX
 SG_ VCFRONT_a082_VCRIGHT_IPC_MIA m1 : 25|1@1+ (1,0) [0|0] "" Vector__XXX
 SG_ VCFRONT_a142_exvMotorFault m2 : 25|1@1+ (1,0) [0|0] "" Vector__XXX
 SG_ VCFRONT_a202_pcsSelfTestFail m3 : 25|1@1+ (1,0) [0|0] "" Vector__XXX
 SG_ VCFRONT_a262_vcrightVoltageMismatch m4 : 25|1@1+ (1,0) [0|0] "" Vector__XXX
 SG_ VCFRONT_a322_epas3sOvertempMax m5 : 25|1@1+ (1,0) [0|0] "" Vector__XXX
 SG_ VCFRONT_a382_recircExvWarning m6 : 25|1@1+ (1,0) [0|0] "" Vector__XXX
 SG_ VCFRONT_a442_TLVBMS_SocChange m7 : 25|1@1+ (1,0) [0|0] "" Vector__XXX
 SG_ VCFRONT_a502_TLVBMS_WeakShortImpedance m8 : 25|1@1+ (1,0) [0|0] "" Vector__XXX
 SG_ VCFRONT_a562_LVBMSModuleOvertemperature m9 : 25|1@1+ (1,0) [0|0] "" Vector__XXX
 SG_ VCFRONT_a083_VCLEFT_IPC_MIA m1 : 26|1@1+ (1,0) [0|0] "" Vector__XXX
 SG_ VCFRONT_a143_pumpBatICTransFault m2 : 26|1@1+ (1,0) [0|0] "" Vector__XXX
 SG_ VCFRONT_a203_epas3pSelfTestFail m3 : 26|1@1+ (1,0) [0|0] "" Vector__XXX
 SG_ VCFRONT_a263_pcsVoltageMismatch m4 : 26|1@1+ (1,0) [0|0] "" Vector__XXX
 SG_ VCFRONT_a323_iboosterOvertempMax m5 : 26|1@1+ (1,0) [0|0] "" Vector__XXX
 SG_ VCFRONT_a383_lccExvWarning m6 : 26|1@1+ (1,0) [0|0] "" Vector__XXX
 SG_ VCFRONT_a443_TLVBMS_BmbDieOverTemperature m7 : 26|1@1+ (1,0) [0|0] "" Vector__XXX
 SG_ VCFRONT_a503_TLVBMS_BrickExtendedOvFault m8 : 26|1@1+ (1,0) [0|0] "" Vector__XXX
 SG_ VCFRONT_a563_chargePortDoorOpenBlockedByBrake m9 : 26|1@1+ (1,0) [0|0] "" Vector__XXX
 SG_ VCFRONT_a623_LVUnhealthy m10 : 26|1@1+ (1,0) [0|0] "" Vector__XXX
 SG_ VCFRONT_a084_TPMS_MIA m1 : 27|1@1+ (1,0) [0|0] "" Vector__XXX
 SG_ VCFRONT_a144_pumpPtICTransFault m2 : 27|1@1+ (1,0) [0|0] "" Vector__XXX
 SG_ VCFRONT_a204_epas3sSelfTestFail m3 : 27|1@1+ (1,0) [0|0] "" Vector__XXX
 SG_ VCFRONT_a264_iBoosterVoltageMismatch m4 : 27|1@1+ (1,0) [0|0] "" Vector__XXX
 SG_ VCFRONT_a324_espOvertempMax m5 : 27|1@1+ (1,0) [0|0] "" Vector__XXX
 SG_ VCFRONT_a384_ccLeftExvWarning m6 : 27|1@1+ (1,0) [0|0] "" Vector__XXX
 SG_ VCFRONT_a444_drv8703Fault m7 : 27|1@1+ (1,0) [0|0] "" Vector__XXX
 SG_ VCFRONT_a504_airInRefrigerantDetected m8 : 27|1@1+ (1,0) [0|0] "" Vector__XXX
 SG_ VCFRONT_a564_leftHeadlampAimingDebug m9 : 27|1@1+ (1,0) [0|0] "" Vector__XXX
 SG_ VCFRONT_a085_CCCM_MIA m1 : 28|1@1+ (1,0) [0|0] "" Vector__XXX
 SG_ VCFRONT_a145_thmlFanICTransFault m2 : 28|1@1+ (1,0) [0|0] "" Vector__XXX
 SG_ VCFRONT_a205_iBoosterSelfTestFail m3 : 28|1@1+ (1,0) [0|0] "" Vector__XXX
 SG_ VCFRONT_a265_ESPVoltageMismatch m4 : 28|1@1+ (1,0) [0|0] "" Vector__XXX
 SG_ VCFRONT_a325_vbatFusedOvertempMax m5 : 28|1@1+ (1,0) [0|0] "" Vector__XXX
 SG_ VCFRONT_a385_ccRightExvWarning m6 : 28|1@1+ (1,0) [0|0] "" Vector__XXX
 SG_ VCFRONT_a445_drv8703SpiFaultDBG m7 : 28|1@1+ (1,0) [0|0] "" Vector__XXX
 SG_ VCFRONT_a505_BLEFrontUnderVoltage m8 : 28|1@1+ (1,0) [0|0] "" Vector__XXX
 SG_ VCFRONT_a565_userPresenceDisplayStateMismatch m9 : 28|1@1+ (1,0) [0|0] "" Vector__XXX
 SG_ VCFRONT_a086_VCBATT_MIA m1 : 29|1@1+ (1,0) [0|0] "" Vector__XXX
 SG_ VCFRONT_a146_pumpBatSoftStall m2 : 29|1@1+ (1,0) [0|0] "" Vector__XXX
 SG_ VCFRONT_a206_espSelfTestFail m3 : 29|1@1+ (1,0) [0|0] "" Vector__XXX
 SG_ VCFRONT_a266_EPAS3pVoltageMismatch m4 : 29|1@1+ (1,0) [0|0] "" Vector__XXX
 SG_ VCFRONT_a326_vcleftSlowTripOC m5 : 29|1@1+ (1,0) [0|0] "" Vector__XXX
 SG_ VCFRONT_a386_exvMotorWarning m6 : 29|1@1+ (1,0) [0|0] "" Vector__XXX
 SG_ VCFRONT_a446_cabinHVACUnavailableContext m7 : 29|1@1+ (1,0) [0|0] "" Vector__XXX
 SG_ VCFRONT_a506_invalidRefrigerantSystemConfig m8 : 29|1@1+ (1,0) [0|0] "" Vector__XXX
 SG_ VCFRONT_a566_leftFrontTurnLightFault m9 : 29|1@1+ (1,0) [0|0] "" Vector__XXX
 SG_ VCFRONT_a626_LVBatteryResistanceIncrease m10 : 29|1@1+ (1,0) [0|0] "" Vector__XXX
 SG_ VCFRONT_a087_DIREL_MIA m1 : 30|1@1+ (1,0) [0|0] "" Vector__XXX
 SG_ VCFRONT_a147_pumpPtSoftStall m2 : 30|1@1+ (1,0) [0|0] "" Vector__XXX
 SG_ VCFRONT_a207_vbatFusdSelfTestFail m3 : 30|1@1+ (1,0) [0|0] "" Vector__XXX
 SG_ VCFRONT_a267_EPAS3sVoltageMismatch m4 : 30|1@1+ (1,0) [0|0] "" Vector__XXX
 SG_ VCFRONT_a327_vcrightSlowTripOC m5 : 30|1@1+ (1,0) [0|0] "" Vector__XXX
 SG_ VCFRONT_a387_shortedCellInstc m6 : 30|1@1+ (1,0) [0|0] "" Vector__XXX
 SG_ VCFRONT_a447_cabinHVACUnavailable m7 : 30|1@1+ (1,0) [0|0] "" Vector__XXX
 SG_ VCFRONT_a507_leftHeadlampAimingFault m8 : 30|1@1+ (1,0) [0|0] "" Vector__XXX
 SG_ VCFRONT_a567_rightFrontTurnLightFault m9 : 30|1@1+ (1,0) [0|0] "" Vector__XXX
 SG_ VCFRONT_a627_LVBatteryUnrecoverableByAnyDevice m10 : 30|1@1+ (1,0) [0|0] "" Vector__XXX
 SG_ VCFRONT_a088_DIRER_MIA m1 : 31|1@1+ (1,0) [0|0] "" Vector__XXX
 SG_ VCFRONT_a148_thmlFanSoftStall m2 : 31|1@1+ (1,0) [0|0] "" Vector__XXX
 SG_ VCFRONT_a208_brakeFluidLow m3 : 31|1@1+ (1,0) [0|0] "" Vector__XXX
 SG_ VCFRONT_a268_vbatFusedVoltageMismatch m4 : 31|1@1+ (1,0) [0|0] "" Vector__XXX
 SG_ VCFRONT_a328_pcsSlowTripOC m5 : 31|1@1+ (1,0) [0|0] "" Vector__XXX
 SG_ VCFRONT_a388_shortedCell m6 : 31|1@1+ (1,0) [0|0] "" Vector__XXX
 SG_ VCFRONT_a448_gtwSteeringBtnReset m7 : 31|1@1+ (1,0) [0|0] "" Vector__XXX
 SG_ VCFRONT_a508_TLVBMS_ImpedanceGrowth m8 : 31|1@1+ (1,0) [0|0] "" Vector__XXX
 SG_ VCFRONT_a568_leftDaytimeRunningLightFault m9 : 31|1@1+ (1,0) [0|0] "" Vector__XXX
 SG_ VCFRONT_a628_TLVBMS_BmbThermistorFault m10 : 31|1@1+ (1,0) [0|0] "" Vector__XXX
 SG_ VCFRONT_a029_CoreDump m0 : 32|1@1+ (1,0) [0|0] "" Vector__XXX
 SG_ VCFRONT_a089_IBST_MIA m1 : 32|1@1+ (1,0) [0|0] "" Vector__XXX
 SG_ VCFRONT_a149_BLEFrontPowerCycled m2 : 32|1@1+ (1,0) [0|0] "" Vector__XXX
 SG_ VCFRONT_a209_brakeFluidSNA m3 : 32|1@1+ (1,0) [0|0] "" Vector__XXX
 SG_ VCFRONT_a269_drveBlckdVltgeTooLow2 m4 : 32|1@1+ (1,0) [0|0] "" Vector__XXX
 SG_ VCFRONT_a329_epas3pSlowTripOC m5 : 32|1@1+ (1,0) [0|0] "" Vector__XXX
 SG_ VCFRONT_a389_frunkInhibitingReleaseAtSpeed m6 : 32|1@1+ (1,0) [0|0] "" Vector__XXX
 SG_ VCFRONT_a449_hornSwitchStuckOn m7 : 32|1@1+ (1,0) [0|0] "" Vector__XXX
 SG_ VCFRONT_a509_vcrightEFuseLoadShed m8 : 32|1@1+ (1,0) [0|0] "" Vector__XXX
 SG_ VCFRONT_a569_rightDaytimeRunningLightFault m9 : 32|1@1+ (1,0) [0|0] "" Vector__XXX
 SG_ VCFRONT_a629_TLVBMS_PackTemperatureIrrational m10 : 32|1@1+ (1,0) [0|0] "" Vector__XXX
 SG_ VCFRONT_a030_ECULogUploadRequest m0 : 33|1@1+ (1,0) [0|0] "" Vector__XXX
 SG_ VCFRONT_a090_APS_MIA m1 : 33|1@1+ (1,0) [0|0] "" Vector__XXX
 SG_ VCFRONT_a150_pumpBatLowRPMCBang m2 : 33|1@1+ (1,0) [0|0] "" Vector__XXX
 SG_ VCFRONT_a210_coolantValveCalib m3 : 33|1@1+ (1,0) [0|0] "" Vector__XXX
 SG_ VCFRONT_a330_epas3sSlowTripOC m5 : 33|1@1+ (1,0) [0|0] "" Vector__XXX
 SG_ VCFRONT_a390_heatPumpModeConvergence m6 : 33|1@1+ (1,0) [0|0] "" Vector__XXX
 SG_ VCFRONT_a450_hornSwitchNotPressedFactory m7 : 33|1@1+ (1,0) [0|0] "" Vector__XXX
 SG_ VCFRONT_a510_LVBatteryRecoveryTimeout m8 : 33|1@1+ (1,0) [0|0] "" Vector__XXX
 SG_ VCFRONT_a570_headlampsAdaptedToLeftHandTraffic m9 : 33|1@1+ (1,0) [0|0] "" Vector__XXX
 SG_ VCFRONT_a630_leftHeadlampFactoryFault m10 : 33|1@1+ (1,0) [0|0] "" Vector__XXX
 SG_ VCFRONT_a031_UDSActive m0 : 34|1@1+ (1,0) [0|0] "" Vector__XXX
 SG_ VCFRONT_a091_CMPD_MIA m1 : 34|1@1+ (1,0) [0|0] "" Vector__XXX
 SG_ VCFRONT_a151_pumpPtLowRPMCBang m2 : 34|1@1+ (1,0) [0|0] "" Vector__XXX
 SG_ VCFRONT_a211_I2CFault m3 : 34|1@1+ (1,0) [0|0] "" Vector__XXX
 SG_ VCFRONT_a271_LVBatteryPermSupported m4 : 34|1@1+ (1,0) [0|0] "" Vector__XXX
 SG_ VCFRONT_a331_iboosterSlowTripOC m5 : 34|1@1+ (1,0) [0|0] "" Vector__XXX
 SG_ VCFRONT_a391_frunkLatchSwitchFault m6 : 34|1@1+ (1,0) [0|0] "" Vector__XXX
 SG_ VCFRONT_a451_refrigerantNotCommissioned m7 : 34|1@1+ (1,0) [0|0] "" Vector__XXX
 SG_ VCFRONT_a511_DCDCSaturationLoadShed m8 : 34|1@1+ (1,0) [0|0] "" Vector__XXX
 SG_ VCFRONT_a571_headlampsAdaptedToRightHandTraffic m9 : 34|1@1+ (1,0) [0|0] "" Vector__XXX
 SG_ VCFRONT_a631_rightHeadlampFactoryFault m10 : 34|1@1+ (1,0) [0|0] "" Vector__XXX
 SG_ VCFRONT_a032_ipcWatchdogExpired m0 : 35|1@1+ (1,0) [0|0] "" Vector__XXX
 SG_ VCFRONT_a092_VCSEATD_MIA m1 : 35|1@1+ (1,0) [0|0] "" Vector__XXX
 SG_ VCFRONT_a152_thmlFanLowRPMCBang m2 : 35|1@1+ (1,0) [0|0] "" Vector__XXX
 SG_ VCFRONT_a212_IBSOverTemp m3 : 35|1@1+ (1,0) [0|0] "" Vector__XXX
 SG_ VCFRONT_a332_espSlowTripOC m5 : 35|1@1+ (1,0) [0|0] "" Vector__XXX
 SG_ VCFRONT_a392_TLVBMS_BmbHwUnderVoltageFault m6 : 35|1@1+ (1,0) [0|0] "" Vector__XXX
 SG_ VCFRONT_a452_dischargePresSensIntermittent m7 : 35|1@1+ (1,0) [0|0] "" Vector__XXX
 SG_ VCFRONT_a512_LVBMSFault_MOS_Open_hardwareOC m8 : 35|1@1+ (1,0) [0|0] "" Vector__XXX
 SG_ VCFRONT_a572_hvacCompressorEFuseTrip m9 : 35|1@1+ (1,0) [0|0] "" Vector__XXX
 SG_ VCFRONT_a033_eccNonCorrectableError m0 : 36|1@1+ (1,0) [0|0] "" Vector__XXX
 SG_ VCFRONT_a093_VCSEATP_MIA m1 : 36|1@1+ (1,0) [0|0] "" Vector__XXX
 SG_ VCFRONT_a153_userPresenceDisplayMismatchClrd m2 : 36|1@1+ (1,0) [0|0] "" Vector__XXX
 SG_ VCFRONT_a213_LVOvercharge m3 : 36|1@1+ (1,0) [0|0] "" Vector__XXX
 SG_ VCFRONT_a273_wiperFrictionModelFault m4 : 36|1@1+ (1,0) [0|0] "" Vector__XXX
 SG_ VCFRONT_a333_vbatFusedSlowTripOC m5 : 36|1@1+ (1,0) [0|0] "" Vector__XXX
 SG_ VCFRONT_a393_ambientTempNetworkSna m6 : 36|1@1+ (1,0) [0|0] "" Vector__XXX
 SG_ VCFRONT_a453_dischargeTempSensIntermittent m7 : 36|1@1+ (1,0) [0|0] "" Vector__XXX
 SG_ VCFRONT_a513_LVBMSFault_MOS_Open_chgOC m8 : 36|1@1+ (1,0) [0|0] "" Vector__XXX
 SG_ VCFRONT_a573_radarEFuseTrip m9 : 36|1@1+ (1,0) [0|0] "" Vector__XXX
 SG_ VCFRONT_a094_EPAS3P_MIA m1 : 37|1@1+ (1,0) [0|0] "" Vector__XXX
 SG_ VCFRONT_a154_prechargeDCRData1 m2 : 37|1@1+ (1,0) [0|0] "" Vector__XXX
 SG_ VCFRONT_a274_failureToPrechargeRisk2 m4 : 37|1@1+ (1,0) [0|0] "" Vector__XXX
 SG_ VCFRONT_a334_vcleftFastTripOCMax m5 : 37|1@1+ (1,0) [0|0] "" Vector__XXX
 SG_ VCFRONT_a394_pressureSensorCheckFault m6 : 37|1@1+ (1,0) [0|0] "" Vector__XXX
 SG_ VCFRONT_a454_suctionPresSensIntermittent m7 : 37|1@1+ (1,0) [0|0] "" Vector__XXX
 SG_ VCFRONT_a514_LVBMSFault_MOS_Open_cellUV m8 : 37|1@1+ (1,0) [0|0] "" Vector__XXX
 SG_ VCFRONT_a574_frontDriveInverterEFuseTrip m9 : 37|1@1+ (1,0) [0|0] "" Vector__XXX
 SG_ VCFRONT_a634_indeterminateSwitchTransitionDetectedDbg m10 : 37|1@1+ (1,0) [0|0] "" Vector__XXX
 SG_ VCFRONT_a095_CHG_MIA m1 : 38|1@1+ (1,0) [0|0] "" Vector__XXX
 SG_ VCFRONT_a155_prechargeDCRData2 m2 : 38|1@1+ (1,0) [0|0] "" Vector__XXX
 SG_ VCFRONT_a275_TLVBMS_BmbCommunication m4 : 38|1@1+ (1,0) [0|0] "" Vector__XXX
 SG_ VCFRONT_a335_vcrightFastTripOCMax m5 : 38|1@1+ (1,0) [0|0] "" Vector__XXX
 SG_ VCFRONT_a395_pressureSensorCheckInconclusive m6 : 38|1@1+ (1,0) [0|0] "" Vector__XXX
 SG_ VCFRONT_a455_suctionTempSensIntermittent m7 : 38|1@1+ (1,0) [0|0] "" Vector__XXX
 SG_ VCFRONT_a515_LVBMSFault_MOS_Open_cellOV m8 : 38|1@1+ (1,0) [0|0] "" Vector__XXX
 SG_ VCFRONT_a575_frontOilPumpEFuseTrip m9 : 38|1@1+ (1,0) [0|0] "" Vector__XXX
 SG_ VCFRONT_a635_rtosSleepFailed m10 : 38|1@1+ (1,0) [0|0] "" Vector__XXX
 SG_ VCFRONT_a096_OCS1P_MIA m1 : 39|1@1+ (1,0) [0|0] "" Vector__XXX
 SG_ VCFRONT_a156_louverBlockage m2 : 39|1@1+ (1,0) [0|0] "" Vector__XXX
 SG_ VCFRONT_a216_powerCutoffImminent m3 : 39|1@1+ (1,0) [0|0] "" Vector__XXX
 SG_ VCFRONT_a276_TLVBMS_BmbDataIntegrityLoss m4 : 39|1@1+ (1,0) [0|0] "" Vector__XXX
 SG_ VCFRONT_a336_pcsFastTripOCMax m5 : 39|1@1+ (1,0) [0|0] "" Vector__XXX
 SG_ VCFRONT_a396_coolantLevelLowUserFacing m6 : 39|1@1+ (1,0) [0|0] "" Vector__XXX
 SG_ VCFRONT_a456_liquidPresSensIntermittent m7 : 39|1@1+ (1,0) [0|0] "" Vector__XXX
 SG_ VCFRONT_a516_hibernationActive m8 : 39|1@1+ (1,0) [0|0] "" Vector__XXX
 SG_ VCFRONT_a576_mcuLogicEFuseTrip m9 : 39|1@1+ (1,0) [0|0] "" Vector__XXX
 SG_ VCFRONT_d636_ptCoolantPumpDetectsAirInSystem m10 : 39|1@1+ (1,0) [0|0] "" Vector__XXX
 SG_ VCFRONT_a097_CMP_MIA m1 : 40|1@1+ (1,0) [0|0] "" Vector__XXX
 SG_ VCFRONT_a157_louverBreakage m2 : 40|1@1+ (1,0) [0|0] "" Vector__XXX
 SG_ VCFRONT_a277_TLVBMS_BmbStatusRegError m4 : 40|1@1+ (1,0) [0|0] "" Vector__XXX
 SG_ VCFRONT_a337_epas3pFastTripOCMax m5 : 40|1@1+ (1,0) [0|0] "" Vector__XXX
 SG_ VCFRONT_a397_temperatureSensorCheckFault m6 : 40|1@1+ (1,0) [0|0] "" Vector__XXX
 SG_ VCFRONT_a457_liquidTempSensIntermittent m7 : 40|1@1+ (1,0) [0|0] "" Vector__XXX
 SG_ VCFRONT_a517_hibernationRecovery m8 : 40|1@1+ (1,0) [0|0] "" Vector__XXX
 SG_ VCFRONT_a577_tasEFuseTrip m9 : 40|1@1+ (1,0) [0|0] "" Vector__XXX
 SG_ VCFRONT_a697_leftHeadlampNotAimed m11 : 40|1@1+ (1,0) [0|0] "" Vector__XXX
 SG_ VCFRONT_d637_battCoolantPumpDetectsAirInSystem m10 : 40|1@1+ (1,0) [0|0] "" Vector__XXX
 SG_ VCFRONT_a038_ProtFaultInfo m0 : 41|1@1+ (1,0) [0|0] "" Vector__XXX
 SG_ VCFRONT_a098_DIR_MIA m1 : 41|1@1+ (1,0) [0|0] "" Vector__XXX
 SG_ VCFRONT_a158_louverDisconnected m2 : 41|1@1+ (1,0) [0|0] "" Vector__XXX
 SG_ VCFRONT_a218_socMonitorDetectedThresholdSoc m3 : 41|1@1+ (1,0) [0|0] "" Vector__XXX
 SG_ VCFRONT_a278_TLVBMS_BmbHwOverCurrentFault m4 : 41|1@1+ (1,0) [0|0] "" Vector__XXX
 SG_ VCFRONT_a338_epas3sFastTripOCMax m5 : 41|1@1+ (1,0) [0|0] "" Vector__XXX
 SG_ VCFRONT_a398_tempSensorCheckInconclusive m6 : 41|1@1+ (1,0) [0|0] "" Vector__XXX
 SG_ VCFRONT_a458_grosslyLowRefrigerant m7 : 41|1@1+ (1,0) [0|0] "" Vector__XXX
 SG_ VCFRONT_a518_LVBMSFault_MOS_Open_packOV m8 : 41|1@1+ (1,0) [0|0] "" Vector__XXX
 SG_ VCFRONT_a578_vbatFusedLowCurrentFeedEFuseTrip m9 : 41|1@1+ (1,0) [0|0] "" Vector__XXX
 SG_ VCFRONT_a698_rightHeadlampNotAimed m11 : 41|1@1+ (1,0) [0|0] "" Vector__XXX
 SG_ VCFRONT_d638_ptCoolantTempSensorIssue m10 : 41|1@1+ (1,0) [0|0] "" Vector__XXX
 SG_ VCFRONT_a039_ProtFaultAddress m0 : 42|1@1+ (1,0) [0|0] "" Vector__XXX
 SG_ VCFRONT_a099_PARK_MIA m1 : 42|1@1+ (1,0) [0|0] "" Vector__XXX
 SG_ VCFRONT_a159_coolantValveFault m2 : 42|1@1+ (1,0) [0|0] "" Vector__XXX
 SG_ VCFRONT_a219_LVVoltFloorRchd m3 : 42|1@1+ (1,0) [0|0] "" Vector__XXX
 SG_ VCFRONT_a279_refrigLiquidTempSns m4 : 42|1@1+ (1,0) [0|0] "" Vector__XXX
 SG_ VCFRONT_a339_iboosterFastTripOCMax m5 : 42|1@1+ (1,0) [0|0] "" Vector__XXX
 SG_ VCFRONT_a399_frunkNeverReportedOpen m6 : 42|1@1+ (1,0) [0|0] "" Vector__XXX
 SG_ VCFRONT_a459_thermalFillAndDrive m7 : 42|1@1+ (1,0) [0|0] "" Vector__XXX
 SG_ VCFRONT_a579_leftHeadlightEFuseTrip m9 : 42|1@1+ (1,0) [0|0] "" Vector__XXX
 SG_ VCFRONT_d639_batteryCoolantTempSensorIssue m10 : 42|1@1+ (1,0) [0|0] "" Vector__XXX
 SG_ VCFRONT_a040_Backtrace m0 : 43|1@1+ (1,0) [0|0] "" Vector__XXX
 SG_ VCFRONT_a100_CANbus_MIA m1 : 43|1@1+ (1,0) [0|0] "" Vector__XXX
 SG_ VCFRONT_a160_compressorInhibited m2 : 43|1@1+ (1,0) [0|0] "" Vector__XXX
 SG_ VCFRONT_a220_reverseBatteryFault m3 : 43|1@1+ (1,0) [0|0] "" Vector__XXX
 SG_ VCFRONT_a280_refrigLiquidPresSns m4 : 43|1@1+ (1,0) [0|0] "" Vector__XXX
 SG_ VCFRONT_a340_espFastTripOCMax m5 : 43|1@1+ (1,0) [0|0] "" Vector__XXX
 SG_ VCFRONT_a400_TLVBMS_BmbVrefBad m6 : 43|1@1+ (1,0) [0|0] "" Vector__XXX
 SG_ VCFRONT_a460_hardIsentropicTdFailed m7 : 43|1@1+ (1,0) [0|0] "" Vector__XXX
 SG_ VCFRONT_a580_rightHeadlightEFuseTrip m9 : 43|1@1+ (1,0) [0|0] "" Vector__XXX
 SG_ VCFRONT_d640_firmwareVersionMismatch m10 : 43|1@1+ (1,0) [0|0] "" Vector__XXX
 SG_ VCFRONT_a041_HighCPULoad m0 : 44|1@1+ (1,0) [0|0] "" Vector__XXX
 SG_ VCFRONT_a101_PM_MIA m1 : 44|1@1+ (1,0) [0|0] "" Vector__XXX
 SG_ VCFRONT_a161_compressorSelfFault m2 : 44|1@1+ (1,0) [0|0] "" Vector__XXX
 SG_ VCFRONT_a221_leftTurnLightFault m3 : 44|1@1+ (1,0) [0|0] "" Vector__XXX
 SG_ VCFRONT_a281_alcoholInterlockBlockingDrive m4 : 44|1@1+ (1,0) [0|0] "" Vector__XXX
 SG_ VCFRONT_a341_vbatFusedFastTripOCMax m5 : 44|1@1+ (1,0) [0|0] "" Vector__XXX
 SG_ VCFRONT_a401_deadLVMinimalAhDischarged m6 : 44|1@1+ (1,0) [0|0] "" Vector__XXX
 SG_ VCFRONT_a461_TLVBMS_SocHighAhError m7 : 44|1@1+ (1,0) [0|0] "" Vector__XXX
 SG_ VCFRONT_a521_vcleftEFuseLoadShed m8 : 44|1@1+ (1,0) [0|0] "" Vector__XXX
 SG_ VCFRONT_a581_windshieldWiperEFuseTrip m9 : 44|1@1+ (1,0) [0|0] "" Vector__XXX
 SG_ VCFRONT_d641_ptCoolantPumpCircuitOpen m10 : 44|1@1+ (1,0) [0|0] "" Vector__XXX
 SG_ VCFRONT_a042_HighStackUsage m0 : 45|1@1+ (1,0) [0|0] "" Vector__XXX
 SG_ VCFRONT_a102_PTC_MIA m1 : 45|1@1+ (1,0) [0|0] "" Vector__XXX
 SG_ VCFRONT_a162_compressorInhibitedContext m2 : 45|1@1+ (1,0) [0|0] "" Vector__XXX
 SG_ VCFRONT_a222_rightTurnLightFault m3 : 45|1@1+ (1,0) [0|0] "" Vector__XXX
 SG_ VCFRONT_a282_coolantLevelSensorFault m4 : 45|1@1+ (1,0) [0|0] "" Vector__XXX
 SG_ VCFRONT_a342_vcleftFastTripSlope m5 : 45|1@1+ (1,0) [0|0] "" Vector__XXX
 SG_ VCFRONT_a402_LVBatteryCannotSupportVehicle m6 : 45|1@1+ (1,0) [0|0] "" Vector__XXX
 SG_ VCFRONT_a462_LVBMSFault m7 : 45|1@1+ (1,0) [0|0] "" Vector__XXX
 SG_ VCFRONT_a522_hibernationActiveLogCapture m8 : 45|1@1+ (1,0) [0|0] "" Vector__XXX
 SG_ VCFRONT_a582_goodForPCSPowerCycle m9 : 45|1@1+ (1,0) [0|0] "" Vector__XXX
 SG_ VCFRONT_d642_batteryCoolantPumpCircuitOpen m10 : 45|1@1+ (1,0) [0|0] "" Vector__XXX
 SG_ VCFRONT_a043_Task1msError m0 : 46|1@1+ (1,0) [0|0] "" Vector__XXX
 SG_ VCFRONT_a103_CP_MIA m1 : 46|1@1+ (1,0) [0|0] "" Vector__XXX
 SG_ VCFRONT_a163_compressorDisabledFSR m2 : 46|1@1+ (1,0) [0|0] "" Vector__XXX
 SG_ VCFRONT_a223_12VTempSensDiscnect m3 : 46|1@1+ (1,0) [0|0] "" Vector__XXX
 SG_ VCFRONT_a283_thmlFanLimitedByCurrent m4 : 46|1@1+ (1,0) [0|0] "" Vector__XXX
 SG_ VCFRONT_a343_vcrightFastTripSlope m5 : 46|1@1+ (1,0) [0|0] "" Vector__XXX
 SG_ VCFRONT_a403_chargeExitHardCurrentLimit m6 : 46|1@1+ (1,0) [0|0] "" Vector__XXX
 SG_ VCFRONT_a463_frunkSensorService m7 : 46|1@1+ (1,0) [0|0] "" Vector__XXX
 SG_ VCFRONT_a523_eFuseThresholdsIncorrect m8 : 46|1@1+ (1,0) [0|0] "" Vector__XXX
 SG_ VCFRONT_a583_frunkSwitchGroupDisagreementDebug m9 : 46|1@1+ (1,0) [0|0] "" Vector__XXX
 SG_ VCFRONT_a643_rightHeadlampUartCondition m10 : 46|1@1+ (1,0) [0|0] "" Vector__XXX
 SG_ VCFRONT_a044_Task10msError m0 : 47|1@1+ (1,0) [0|0] "" Vector__XXX
 SG_ VCFRONT_a104_DAS_MIA m1 : 47|1@1+ (1,0) [0|0] "" Vector__XXX
 SG_ VCFRONT_a164_eFuseLckoutMissing m2 : 47|1@1+ (1,0) [0|0] "" Vector__XXX
 SG_ VCFRONT_a224_revBatChrgPmpFault m3 : 47|1@1+ (1,0) [0|0] "" Vector__XXX
 SG_ VCFRONT_a284_chillerExvFault m4 : 47|1@1+ (1,0) [0|0] "" Vector__XXX
 SG_ VCFRONT_a344_pcsFastTripSlope m5 : 47|1@1+ (1,0) [0|0] "" Vector__XXX
 SG_ VCFRONT_a404_resistanceEstimationHardFailure m6 : 47|1@1+ (1,0) [0|0] "" Vector__XXX
 SG_ VCFRONT_a464_highFlowIndexHighSubcoolFlagged m7 : 47|1@1+ (1,0) [0|0] "" Vector__XXX
 SG_ VCFRONT_a524_rightHeadlampAimingFault m8 : 47|1@1+ (1,0) [0|0] "" Vector__XXX
 SG_ VCFRONT_a584_frunkSwitchGroupDebug m9 : 47|1@1+ (1,0) [0|0] "" Vector__XXX
 SG_ VCFRONT_a644_washPumpHealthCalculationDbg0 m10 : 47|1@1+ (1,0) [0|0] "" Vector__XXX
 SG_ VCFRONT_a045_Task100msError m0 : 48|1@1+ (1,0) [0|0] "" Vector__XXX
 SG_ VCFRONT_a105_TAS_MIA m1 : 48|1@1+ (1,0) [0|0] "" Vector__XXX
 SG_ VCFRONT_a165_unxpctdEFuseLckout m2 : 48|1@1+ (1,0) [0|0] "" Vector__XXX
 SG_ VCFRONT_a225_driveBlckdByShowroom m3 : 48|1@1+ (1,0) [0|0] "" Vector__XXX
 SG_ VCFRONT_a285_evaporatorExvFault m4 : 48|1@1+ (1,0) [0|0] "" Vector__XXX
 SG_ VCFRONT_a345_epas3pFastTripSlope m5 : 48|1@1+ (1,0) [0|0] "" Vector__XXX
 SG_ VCFRONT_a405_dcrData1 m6 : 48|1@1+ (1,0) [0|0] "" Vector__XXX
 SG_ VCFRONT_a465_lowFlowIndexHighSubcoolFlagged m7 : 48|1@1+ (1,0) [0|0] "" Vector__XXX
 SG_ VCFRONT_a525_LVBatterySWMisconfiguration m8 : 48|1@1+ (1,0) [0|0] "" Vector__XXX
 SG_ VCFRONT_a585_bothHeadlampsInternalError m9 : 48|1@1+ (1,0) [0|0] "" Vector__XXX
 SG_ VCFRONT_a645_washPumpHealthCalculationDbg1 m10 : 48|1@1+ (1,0) [0|0] "" Vector__XXX
 SG_ VCFRONT_a046_Task1000msError m0 : 49|1@1+ (1,0) [0|0] "" Vector__XXX
 SG_ VCFRONT_a106_PCS_MIA m1 : 49|1@1+ (1,0) [0|0] "" Vector__XXX
 SG_ VCFRONT_a166_rightHCMMIA m2 : 49|1@1+ (1,0) [0|0] "" Vector__XXX
 SG_ VCFRONT_a286_recircExvFault m4 : 49|1@1+ (1,0) [0|0] "" Vector__XXX
 SG_ VCFRONT_a346_epas3sFastTripSlope m5 : 49|1@1+ (1,0) [0|0] "" Vector__XXX
 SG_ VCFRONT_a406_dcrData2 m6 : 49|1@1+ (1,0) [0|0] "" Vector__XXX
 SG_ VCFRONT_a466_highFlowIndexLowSubcoolFlagged m7 : 49|1@1+ (1,0) [0|0] "" Vector__XXX
 SG_ VCFRONT_a586_rightLowOrHighBeamLightCondition m9 : 49|1@1+ (1,0) [0|0] "" Vector__XXX
 SG_ VCFRONT_a646_washPumpHealthCalculationDbg2 m10 : 49|1@1+ (1,0) [0|0] "" Vector__XXX
 SG_ VCFRONT_a047_resetReason m0 : 50|1@1+ (1,0) [0|0] "" Vector__XXX
 SG_ VCFRONT_a107_BMS_MIA m1 : 50|1@1+ (1,0) [0|0] "" Vector__XXX
 SG_ VCFRONT_a167_leftHCMMIA m2 : 50|1@1+ (1,0) [0|0] "" Vector__XXX
 SG_ VCFRONT_a287_lccExvFault m4 : 50|1@1+ (1,0) [0|0] "" Vector__XXX
 SG_ VCFRONT_a347_iboosterFastTripSlope m5 : 50|1@1+ (1,0) [0|0] "" Vector__XXX
 SG_ VCFRONT_a407_dcrMilliOhmsAboveThreshold m6 : 50|1@1+ (1,0) [0|0] "" Vector__XXX
 SG_ VCFRONT_a467_lowPowerIndexFlagged m7 : 50|1@1+ (1,0) [0|0] "" Vector__XXX
 SG_ VCFRONT_a527_LVBatteryCellImbalance m8 : 50|1@1+ (1,0) [0|0] "" Vector__XXX
 SG_ VCFRONT_a587_externalLVPowerSupply m9 : 50|1@1+ (1,0) [0|0] "" Vector__XXX
 SG_ VCFRONT_d647_louverCommLost m10 : 50|1@1+ (1,0) [0|0] "" Vector__XXX
 SG_ VCFRONT_a108_DIF_MIA m1 : 51|1@1+ (1,0) [0|0] "" Vector__XXX
 SG_ VCFRONT_a168_hcmShortToVBAT m2 : 51|1@1+ (1,0) [0|0] "" Vector__XXX
 SG_ VCFRONT_a228_pumpBatFbkSanity m3 : 51|1@1+ (1,0) [0|0] "" Vector__XXX
 SG_ VCFRONT_a288_ccLeftExvFault m4 : 51|1@1+ (1,0) [0|0] "" Vector__XXX
 SG_ VCFRONT_a348_espFastTripSlope m5 : 51|1@1+ (1,0) [0|0] "" Vector__XXX
 SG_ VCFRONT_a408_standbyChargeProfileHardExit m6 : 51|1@1+ (1,0) [0|0] "" Vector__XXX
 SG_ VCFRONT_a468_highPowerIndexFlagged m7 : 51|1@1+ (1,0) [0|0] "" Vector__XXX
 SG_ VCFRONT_a528_LVBatteryCommsDiscnctd m8 : 51|1@1+ (1,0) [0|0] "" Vector__XXX
 SG_ VCFRONT_a588_vcleftPwrRationalityCurve m9 : 51|1@1+ (1,0) [0|0] "" Vector__XXX
 SG_ VCFRONT_d648_louverBlocked m10 : 51|1@1+ (1,0) [0|0] "" Vector__XXX
 SG_ VCFRONT_a109_RCM_MIA m1 : 52|1@1+ (1,0) [0|0] "" Vector__XXX
 SG_ VCFRONT_a169_hcmPhaseEnableFail m2 : 52|1@1+ (1,0) [0|0] "" Vector__XXX
 SG_ VCFRONT_a229_pumpPtFbkSanity m3 : 52|1@1+ (1,0) [0|0] "" Vector__XXX
 SG_ VCFRONT_a289_ccRightExvFault m4 : 52|1@1+ (1,0) [0|0] "" Vector__XXX
 SG_ VCFRONT_a349_vbatFusedFastTripSlope m5 : 52|1@1+ (1,0) [0|0] "" Vector__XXX
 SG_ VCFRONT_a409_invalidConfiguration m6 : 52|1@1+ (1,0) [0|0] "" Vector__XXX
 SG_ VCFRONT_a469_prvPopDetected m7 : 52|1@1+ (1,0) [0|0] "" Vector__XXX
 SG_ VCFRONT_a529_discnctdBatteryStateUnknown m8 : 52|1@1+ (1,0) [0|0] "" Vector__XXX
 SG_ VCFRONT_a589_vcleftFastBlowDetection m9 : 52|1@1+ (1,0) [0|0] "" Vector__XXX
 SG_ VCFRONT_a649_persistAccPortPowerReqOverridden m10 : 52|1@1+ (1,0) [0|0] "" Vector__XXX
 SG_ VCFRONT_a110_GTW_MIA m1 : 53|1@1+ (1,0) [0|0] "" Vector__XXX
 SG_ VCFRONT_a170_hcmUnderVoltage m2 : 53|1@1+ (1,0) [0|0] "" Vector__XXX
 SG_ VCFRONT_a230_thmlFanFbkSanity m3 : 53|1@1+ (1,0) [0|0] "" Vector__XXX
 SG_ VCFRONT_a290_leftFogLightFault m4 : 53|1@1+ (1,0) [0|0] "" Vector__XXX
 SG_ VCFRONT_a350_espValveCurrentSenseSaturated m5 : 53|1@1+ (1,0) [0|0] "" Vector__XXX
 SG_ VCFRONT_a410_LVBatteryDataCollection1 m6 : 53|1@1+ (1,0) [0|0] "" Vector__XXX
 SG_ VCFRONT_a470_implausiblePdPlDetected m7 : 53|1@1+ (1,0) [0|0] "" Vector__XXX
 SG_ VCFRONT_a530_sharpCurrentRise m8 : 53|1@1+ (1,0) [0|0] "" Vector__XXX
 SG_ VCFRONT_a590_vcrightPwrRationalityCurve m9 : 53|1@1+ (1,0) [0|0] "" Vector__XXX
 SG_ VCFRONT_d650_lowCoolantLevel m10 : 53|1@1+ (1,0) [0|0] "" Vector__XXX
 SG_ VCFRONT_a111_EPBR_MIA m1 : 54|1@1+ (1,0) [0|0] "" Vector__XXX
 SG_ VCFRONT_a171_driveBlckdByMsmtch m2 : 54|1@1+ (1,0) [0|0] "" Vector__XXX
 SG_ VCFRONT_a231_12VTempSensShort m3 : 54|1@1+ (1,0) [0|0] "" Vector__XXX
 SG_ VCFRONT_a291_rightFogLightFault m4 : 54|1@1+ (1,0) [0|0] "" Vector__XXX
 SG_ VCFRONT_a351_emergencyFrunkButtonPressIgnored m5 : 54|1@1+ (1,0) [0|0] "" Vector__XXX
 SG_ VCFRONT_a411_LVBatteryDataCollection2 m6 : 54|1@1+ (1,0) [0|0] "" Vector__XXX
 SG_ VCFRONT_a531_lowPowerIndexFlaggedUserFacing m8 : 54|1@1+ (1,0) [0|0] "" Vector__XXX
 SG_ VCFRONT_a591_vcrightFastBlowDetection m9 : 54|1@1+ (1,0) [0|0] "" Vector__XXX
 SG_ VCFRONT_d651_ptCoolantPumpStall m10 : 54|1@1+ (1,0) [0|0] "" Vector__XXX
 SG_ VCFRONT_a112_EPBL_MIA m1 : 55|1@1+ (1,0) [0|0] "" Vector__XXX
 SG_ VCFRONT_a172_wsteHtBlckdByMsmtch m2 : 55|1@1+ (1,0) [0|0] "" Vector__XXX
 SG_ VCFRONT_a232_lowSideControllerHighFdbk m3 : 55|1@1+ (1,0) [0|0] "" Vector__XXX
 SG_ VCFRONT_a292_sideMarkerLightPipeFault m4 : 55|1@1+ (1,0) [0|0] "" Vector__XXX
 SG_ VCFRONT_a352_audioCurrentSpikeData m5 : 55|1@1+ (1,0) [0|0] "" Vector__XXX
 SG_ VCFRONT_a412_dcrData3 m6 : 55|1@1+ (1,0) [0|0] "" Vector__XXX
 SG_ VCFRONT_a472_leftHeadlampRangeUpdate m7 : 55|1@1+ (1,0) [0|0] "" Vector__XXX
 SG_ VCFRONT_a532_gtwMIAInDrive m8 : 55|1@1+ (1,0) [0|0] "" Vector__XXX
 SG_ VCFRONT_a592_vcleftCurvePowerCutoff m9 : 55|1@1+ (1,0) [0|0] "" Vector__XXX
 SG_ VCFRONT_d652_ptCoolantPumpCircuitIssue m10 : 55|1@1+ (1,0) [0|0] "" Vector__XXX
 SG_ VCFRONT_a053_wiperCommErrorUser m0 : 56|1@1+ (1,0) [0|0] "" Vector__XXX
 SG_ VCFRONT_a113_UI_MIA m1 : 56|1@1+ (1,0) [0|0] "" Vector__XXX
 SG_ VCFRONT_a173_HVBlckdByMsmtch m2 : 56|1@1+ (1,0) [0|0] "" Vector__XXX
 SG_ VCFRONT_a233_autopilot1EFuseFault m3 : 56|1@1+ (1,0) [0|0] "" Vector__XXX
 SG_ VCFRONT_a293_interiorFrunkLightFault m4 : 56|1@1+ (1,0) [0|0] "" Vector__XXX
 SG_ VCFRONT_a353_wiperHeaterUndercurrent m5 : 56|1@1+ (1,0) [0|0] "" Vector__XXX
 SG_ VCFRONT_a413_TLVBMS_BmbVrefWarning m6 : 56|1@1+ (1,0) [0|0] "" Vector__XXX
 SG_ VCFRONT_a473_rightHeadlampRangeUpdate m7 : 56|1@1+ (1,0) [0|0] "" Vector__XXX
 SG_ VCFRONT_a533_TLVBMS_MosfetOverTemperatureFault m8 : 56|1@1+ (1,0) [0|0] "" Vector__XXX
 SG_ VCFRONT_a593_vcleftFastBlowPowerCutoff m9 : 56|1@1+ (1,0) [0|0] "" Vector__XXX
 SG_ VCFRONT_d653_ptCoolantPumpCommLost m10 : 56|1@1+ (1,0) [0|0] "" Vector__XXX
 SG_ VCFRONT_a054_compressorLowFlowUserFacing m0 : 57|1@1+ (1,0) [0|0] "" Vector__XXX
 SG_ VCFRONT_a114_ESP_MIA m1 : 57|1@1+ (1,0) [0|0] "" Vector__XXX
 SG_ VCFRONT_a174_driveNotAuthed m2 : 57|1@1+ (1,0) [0|0] "" Vector__XXX
 SG_ VCFRONT_a234_autopilot2EFuseFault m3 : 57|1@1+ (1,0) [0|0] "" Vector__XXX
 SG_ VCFRONT_a294_leftSideRepeaterLightFault m4 : 57|1@1+ (1,0) [0|0] "" Vector__XXX
 SG_ VCFRONT_a354_windshieldCameraHeaterUndercurrent m5 : 57|1@1+ (1,0) [0|0] "" Vector__XXX
 SG_ VCFRONT_a414_prechargeLVLoadReduction m6 : 57|1@1+ (1,0) [0|0] "" Vector__XXX
 SG_ VCFRONT_a474_leftHeadlampInternalError m7 : 57|1@1+ (1,0) [0|0] "" Vector__XXX
 SG_ VCFRONT_a534_chillerExvCalibInitDebug m8 : 57|1@1+ (1,0) [0|0] "" Vector__XXX
 SG_ VCFRONT_a594_virtualPitchConversionDebug m9 : 57|1@1+ (1,0) [0|0] "" Vector__XXX
 SG_ VCFRONT_d654_batteryCoolantPumpStall m10 : 57|1@1+ (1,0) [0|0] "" Vector__XXX
 SG_ VCFRONT_a115_VCSEC_MIA m1 : 58|1@1+ (1,0) [0|0] "" Vector__XXX
 SG_ VCFRONT_a175_ambientTempSns m2 : 58|1@1+ (1,0) [0|0] "" Vector__XXX
 SG_ VCFRONT_a235_ptTempSnsIrrational m3 : 58|1@1+ (1,0) [0|0] "" Vector__XXX
 SG_ VCFRONT_a295_rightSideRepeaterLightFault m4 : 58|1@1+ (1,0) [0|0] "" Vector__XXX
 SG_ VCFRONT_a355_coolantSysLockout m5 : 58|1@1+ (1,0) [0|0] "" Vector__XXX
 SG_ VCFRONT_a415_prechargeLVLoadReduction2 m6 : 58|1@1+ (1,0) [0|0] "" Vector__XXX
 SG_ VCFRONT_a475_rightHeadlampInternalError m7 : 58|1@1+ (1,0) [0|0] "" Vector__XXX
 SG_ VCFRONT_a535_evapExvCalibInitDebug m8 : 58|1@1+ (1,0) [0|0] "" Vector__XXX
 SG_ VCFRONT_a595_voltageSensorMismatch m9 : 58|1@1+ (1,0) [0|0] "" Vector__XXX
 SG_ VCFRONT_d655_batteryCoolantPumpCircuitIssue m10 : 58|1@1+ (1,0) [0|0] "" Vector__XXX
 SG_ VCFRONT_a116_VCRIGHT_MIA m1 : 59|1@1+ (1,0) [0|0] "" Vector__XXX
 SG_ VCFRONT_a176_vehicleInSelfTest m2 : 59|1@1+ (1,0) [0|0] "" Vector__XXX
 SG_ VCFRONT_a236_batTempSnsIrrational m3 : 59|1@1+ (1,0) [0|0] "" Vector__XXX
 SG_ VCFRONT_a296_turnSignalIssue m4 : 59|1@1+ (1,0) [0|0] "" Vector__XXX
 SG_ VCFRONT_a356_refrigSysLockout m5 : 59|1@1+ (1,0) [0|0] "" Vector__XXX
 SG_ VCFRONT_a416_TLVBMS_BrickOverDischarged m6 : 59|1@1+ (1,0) [0|0] "" Vector__XXX
 SG_ VCFRONT_a476_LVBMSMIA m7 : 59|1@1+ (1,0) [0|0] "" Vector__XXX
 SG_ VCFRONT_a536_recircExvCalibInitDebug m8 : 59|1@1+ (1,0) [0|0] "" Vector__XXX
 SG_ VCFRONT_a596_vcrightCurvePowerCutoff m9 : 59|1@1+ (1,0) [0|0] "" Vector__XXX
 SG_ VCFRONT_d656_batteryCoolantPumpCommLost m10 : 59|1@1+ (1,0) [0|0] "" Vector__XXX
 SG_ VCFRONT_a057_HVP_MIA m0 : 60|1@1+ (1,0) [0|0] "" Vector__XXX
 SG_ VCFRONT_a117_VCLEFT_MIA m1 : 60|1@1+ (1,0) [0|0] "" Vector__XXX
 SG_ VCFRONT_a177_mcuAudioEFuseFault m2 : 60|1@1+ (1,0) [0|0] "" Vector__XXX
 SG_ VCFRONT_a237_pumpBatChipComms m3 : 60|1@1+ (1,0) [0|0] "" Vector__XXX
 SG_ VCFRONT_a297_TLVBMS_BmbHwOverTemperatureFault m4 : 60|1@1+ (1,0) [0|0] "" Vector__XXX
 SG_ VCFRONT_a357_hornUndercurrent m5 : 60|1@1+ (1,0) [0|0] "" Vector__XXX
 SG_ VCFRONT_a417_TLVBMS_BrickOverVoltageFault m6 : 60|1@1+ (1,0) [0|0] "" Vector__XXX
 SG_ VCFRONT_a477_LVBatteryUnrecoverableByVehicle m7 : 60|1@1+ (1,0) [0|0] "" Vector__XXX
 SG_ VCFRONT_a537_lccExvCalibInitDebug m8 : 60|1@1+ (1,0) [0|0] "" Vector__XXX
 SG_ VCFRONT_a597_vcrightFastBlowPowerCutoff m9 : 60|1@1+ (1,0) [0|0] "" Vector__XXX
 SG_ VCFRONT_d657_radiatorFanOperationIssue m10 : 60|1@1+ (1,0) [0|0] "" Vector__XXX
 SG_ VCFRONT_a058_inputRHighSyncDebug m0 : 61|1@1+ (1,0) [0|0] "" Vector__XXX
 SG_ VCFRONT_a118_VCFRONT_MIA m1 : 61|1@1+ (1,0) [0|0] "" Vector__XXX
 SG_ VCFRONT_a178_compLiquidPumpOut m2 : 61|1@1+ (1,0) [0|0] "" Vector__XXX
 SG_ VCFRONT_a238_pumpPtChipComms m3 : 61|1@1+ (1,0) [0|0] "" Vector__XXX
 SG_ VCFRONT_a298_radiatorLowAirFlowDetected m4 : 61|1@1+ (1,0) [0|0] "" Vector__XXX
 SG_ VCFRONT_a358_hornOvercurrent m5 : 61|1@1+ (1,0) [0|0] "" Vector__XXX
 SG_ VCFRONT_a418_TLVBMS_BrickOverVoltageWarning m6 : 61|1@1+ (1,0) [0|0] "" Vector__XXX
 SG_ VCFRONT_a478_LVBMS_MOSFET_Open m7 : 61|1@1+ (1,0) [0|0] "" Vector__XXX
 SG_ VCFRONT_a538_cclExvCalibInitDebug m8 : 61|1@1+ (1,0) [0|0] "" Vector__XXX
 SG_ VCFRONT_a598_eFuseSelfTestFailureService m9 : 61|1@1+ (1,0) [0|0] "" Vector__XXX
 SG_ VCFRONT_d658_radiatorFanCircuitIssue m10 : 61|1@1+ (1,0) [0|0] "" Vector__XXX
 SG_ VCFRONT_a059_inputResistanceHigh m0 : 62|1@1+ (1,0) [0|0] "" Vector__XXX
 SG_ VCFRONT_a119_SCCM_MIA m1 : 62|1@1+ (1,0) [0|0] "" Vector__XXX
 SG_ VCFRONT_a179_highLVAmpsIntoPCS m2 : 62|1@1+ (1,0) [0|0] "" Vector__XXX
 SG_ VCFRONT_a239_thmlFanChipComms m3 : 62|1@1+ (1,0) [0|0] "" Vector__XXX
 SG_ VCFRONT_a299_homelinkConfigurationFailed m4 : 62|1@1+ (1,0) [0|0] "" Vector__XXX
 SG_ VCFRONT_a359_postPORExcessiveAh m5 : 62|1@1+ (1,0) [0|0] "" Vector__XXX
 SG_ VCFRONT_a419_TLVBMS_BrickSocLow m6 : 62|1@1+ (1,0) [0|0] "" Vector__XXX
 SG_ VCFRONT_a479_LVBMS_ECPA_NotClosed m7 : 62|1@1+ (1,0) [0|0] "" Vector__XXX
 SG_ VCFRONT_a539_ccrExvCalibInitDebug m8 : 62|1@1+ (1,0) [0|0] "" Vector__XXX
 SG_ VCFRONT_a599_LVBatteryTypeUnsupported m9 : 62|1@1+ (1,0) [0|0] "" Vector__XXX
 SG_ VCFRONT_d659_radiatorFanCommLost m10 : 62|1@1+ (1,0) [0|0] "" Vector__XXX
 SG_ VCFRONT_a060_engineeringBuild m0 : 63|1@1+ (1,0) [0|0] "" Vector__XXX
 SG_ VCFRONT_a120_DI_DRIVE_MIA m1 : 63|1@1+ (1,0) [0|0] "" Vector__XXX
 SG_ VCFRONT_a180_DCDCNotSupportingLVBus m2 : 63|1@1+ (1,0) [0|0] "" Vector__XXX
 SG_ VCFRONT_a240_lowSideCompromised m3 : 63|1@1+ (1,0) [0|0] "" Vector__XXX
 SG_ VCFRONT_a300_louverActuatorSwapDetected m4 : 63|1@1+ (1,0) [0|0] "" Vector__XXX
 SG_ VCFRONT_a360_ungracefulAccPlusExit m5 : 63|1@1+ (1,0) [0|0] "" Vector__XXX
 SG_ VCFRONT_a420_holidayParty m6 : 63|1@1+ (1,0) [0|0] "" Vector__XXX
 SG_ VCFRONT_a480_vnf1048Fault m7 : 63|1@1+ (1,0) [0|0] "" Vector__XXX
 SG_ VCFRONT_a540_radiatorSteamDetected m8 : 63|1@1+ (1,0) [0|0] "" Vector__XXX
 SG_ VCFRONT_a600_currentSensorMismatch m9 : 63|1@1+ (1,0) [0|0] "" Vector__XXX
 SG_ VCFRONT_d660_coolantValveCircuitIssue m10 : 63|1@1+ (1,0) [0|0] "" Vector__XXX

BO_ 833 VCFRONT1_alertMatrix: 8 Vector__XXX
 SG_ VCFRONT1_matrixIndex M : 0|4@1+ (1,0) [0|0] "" Vector__XXX
 SG_ VCFRONT1_a001_WatchdogReset m0 : 4|1@1+ (1,0) [0|0] "" Vector__XXX
 SG_ VCFRONT1_a061_XCPConnected m1 : 4|1@1+ (1,0) [0|0] "" Vector__XXX
 SG_ VCFRONT1_a002_PowerLossReset m0 : 5|1@1+ (1,0) [0|0] "" Vector__XXX
 SG_ VCFRONT1_a062_XCPWasConnected m1 : 5|1@1+ (1,0) [0|0] "" Vector__XXX
 SG_ VCFRONT1_a122_ICR_MIA m2 : 5|1@1+ (1,0) [0|0] "" Vector__XXX
 SG_ VCFRONT1_a482_lvBridgeEFuseTrip m8 : 5|1@1+ (1,0) [0|0] "" Vector__XXX
 SG_ VCFRONT1_a003_SWAssertion m0 : 6|1@1+ (1,0) [0|0] "" Vector__XXX
 SG_ VCFRONT1_a063_SwitchFault m1 : 6|1@1+ (1,0) [0|0] "" Vector__XXX
 SG_ VCFRONT1_a423_rtosSleepFailed m7 : 6|1@1+ (1,0) [0|0] "" Vector__XXX
 SG_ VCFRONT1_a064_busSleepReqTimeout m1 : 7|1@1+ (1,0) [0|0] "" Vector__XXX
 SG_ VCFRONT1_a124_BB_MIA m2 : 7|1@1+ (1,0) [0|0] "" Vector__XXX
 SG_ VCFRONT1_a484_undervoltageSelfTestStuckOn m8 : 7|1@1+ (1,0) [0|0] "" Vector__XXX
 SG_ VCFRONT1_a005_CANTXError m0 : 8|1@1+ (1,0) [0|0] "" Vector__XXX
 SG_ VCFRONT1_a125_SCCM_MIA m2 : 8|1@1+ (1,0) [0|0] "" Vector__XXX
 SG_ VCFRONT1_a485_uvSelfTestLoadUnattemptedOnDbg m8 : 8|1@1+ (1,0) [0|0] "" Vector__XXX
 SG_ VCFRONT1_a006_CANTX_cyclicError m0 : 9|1@1+ (1,0) [0|0] "" Vector__XXX
 SG_ VCFRONT1_a126_EPAS3P_MIA m2 : 9|1@1+ (1,0) [0|0] "" Vector__XXX
 SG_ VCFRONT1_a486_undervoltageSelfTestBridgeSyncFailure m8 : 9|1@1+ (1,0) [0|0] "" Vector__XXX
 SG_ VCFRONT1_a127_iBoosterEFuseTrip m2 : 10|1@1+ (1,0) [0|0] "" Vector__XXX
 SG_ VCFRONT1_a128_vcrightEFuseTrip m2 : 11|1@1+ (1,0) [0|0] "" Vector__XXX
 SG_ VCFRONT1_a188_sleepFailed m3 : 11|1@1+ (1,0) [0|0] "" Vector__XXX
 SG_ VCFRONT1_a129_pcsEFuseTrip m2 : 12|1@1+ (1,0) [0|0] "" Vector__XXX
 SG_ VCFRONT1_a249_pcsOvClampTripped m4 : 12|1@1+ (1,0) [0|0] "" Vector__XXX
 SG_ VCFRONT1_a489_vnf1248SelfTestDebug m8 : 12|1@1+ (1,0) [0|0] "" Vector__XXX
 SG_ VCFRONT1_a130_autopilot2EFuseTrip m2 : 13|1@1+ (1,0) [0|0] "" Vector__XXX
 SG_ VCFRONT1_a250_pcsOvShutdownTripped m4 : 13|1@1+ (1,0) [0|0] "" Vector__XXX
 SG_ VCFRONT1_a490_vnf1248SelfTestFailure m8 : 13|1@1+ (1,0) [0|0] "" Vector__XXX
 SG_ VCFRONT1_a131_PCSCOMMON_MIA m2 : 14|1@1+ (1,0) [0|0] "" Vector__XXX
 SG_ VCFRONT1_a191_exitDriveDomainDown m3 : 14|1@1+ (1,0) [0|0] "" Vector__XXX
 SG_ VCFRONT1_a251_pcsOvShutdownSelfTestFailure m4 : 14|1@1+ (1,0) [0|0] "" Vector__XXX
 SG_ VCFRONT1_a491_vnf1248ConfigurationMismatch m8 : 14|1@1+ (1,0) [0|0] "" Vector__XXX
 SG_ VCFRONT1_a012_CPUReset m0 : 15|1@1+ (1,0) [0|0] "" Vector__XXX
 SG_ VCFRONT1_a132_epas2EFuseTrip m2 : 15|1@1+ (1,0) [0|0] "" Vector__XXX
 SG_ VCFRONT1_a252_pcsOvShutdownSelfTestStageFailure m4 : 15|1@1+ (1,0) [0|0] "" Vector__XXX
 SG_ VCFRONT1_a013_AlertManagerFault m0 : 16|1@1+ (1,0) [0|0] "" Vector__XXX
 SG_ VCFRONT1_a133_BRAKE_MIA m2 : 16|1@1+ (1,0) [0|0] "" Vector__XXX
 SG_ VCFRONT1_a253_pcsOvShutdownHighSideSelfTestDebug m4 : 16|1@1+ (1,0) [0|0] "" Vector__XXX
 SG_ VCFRONT1_a134_hvContactorsEFuseTrip m2 : 17|1@1+ (1,0) [0|0] "" Vector__XXX
 SG_ VCFRONT1_a015_NVMMError m0 : 18|1@1+ (1,0) [0|0] "" Vector__XXX
 SG_ VCFRONT1_a135_leftHeadlightEFuseTrip m2 : 18|1@1+ (1,0) [0|0] "" Vector__XXX
 SG_ VCFRONT1_a016_NVMMRecordError m0 : 19|1@1+ (1,0) [0|0] "" Vector__XXX
 SG_ VCFRONT1_a496_exitDriveWarningDomainDown m8 : 19|1@1+ (1,0) [0|0] "" Vector__XXX
 SG_ VCFRONT1_a017_NVMMStatusDbg m0 : 20|1@1+ (1,0) [0|0] "" Vector__XXX
 SG_ VCFRONT1_a077_VCBATT0_MIA m1 : 20|1@1+ (1,0) [0|0] "" Vector__XXX
 SG_ VCFRONT1_a617_APP_MIA m10 : 20|1@1+ (1,0) [0|0] "" Vector__XXX
 SG_ VCFRONT1_a018_HardFault m0 : 21|1@1+ (1,0) [0|0] "" Vector__XXX
 SG_ VCFRONT1_a078_VCBATT1_MIA m1 : 21|1@1+ (1,0) [0|0] "" Vector__XXX
 SG_ VCFRONT1_a019_BusFault m0 : 22|1@1+ (1,0) [0|0] "" Vector__XXX
 SG_ VCFRONT1_a079_VCBATT2_MIA m1 : 22|1@1+ (1,0) [0|0] "" Vector__XXX
 SG_ VCFRONT1_a080_VCFRONT0_MIA m1 : 23|1@1+ (1,0) [0|0] "" Vector__XXX
 SG_ VCFRONT1_a021_TaskSchedulerError m0 : 24|1@1+ (1,0) [0|0] "" Vector__XXX
 SG_ VCFRONT1_a081_VCFRONT1_MIA m1 : 24|1@1+ (1,0) [0|0] "" Vector__XXX
 SG_ VCFRONT1_a022_TaskInitError m0 : 25|1@1+ (1,0) [0|0] "" Vector__XXX
 SG_ VCFRONT1_a082_VCFRONT2_MIA m1 : 25|1@1+ (1,0) [0|0] "" Vector__XXX
 SG_ VCFRONT1_a262_vcrightVoltageMismatch m4 : 25|1@1+ (1,0) [0|0] "" Vector__XXX
 SG_ VCFRONT1_a263_pcsVoltageMismatch m4 : 26|1@1+ (1,0) [0|0] "" Vector__XXX
 SG_ VCFRONT1_a144_EPAS3S_MIA m2 : 27|1@1+ (1,0) [0|0] "" Vector__XXX
 SG_ VCFRONT1_a204_undervoltageLoadshedTriggered m3 : 27|1@1+ (1,0) [0|0] "" Vector__XXX
 SG_ VCFRONT1_a264_iBoosterVoltageMismatch m4 : 27|1@1+ (1,0) [0|0] "" Vector__XXX
 SG_ VCFRONT1_a205_overvoltageProtectionTriggered m3 : 28|1@1+ (1,0) [0|0] "" Vector__XXX
 SG_ VCFRONT1_a086_VCBATT_MIA m1 : 29|1@1+ (1,0) [0|0] "" Vector__XXX
 SG_ VCFRONT1_a266_EPAS2VoltageMismatch m4 : 29|1@1+ (1,0) [0|0] "" Vector__XXX
 SG_ VCFRONT1_a028_UsageFault m0 : 31|1@1+ (1,0) [0|0] "" Vector__XXX
 SG_ VCFRONT1_a029_CoreDump m0 : 32|1@1+ (1,0) [0|0] "" Vector__XXX
 SG_ VCFRONT1_a509_eFuseASICManagerStateMismatch m8 : 32|1@1+ (1,0) [0|0] "" Vector__XXX
 SG_ VCFRONT1_a030_ECULogUploadRequest m0 : 33|1@1+ (1,0) [0|0] "" Vector__XXX
 SG_ VCFRONT1_a090_APS_MIA m1 : 33|1@1+ (1,0) [0|0] "" Vector__XXX
 SG_ VCFRONT1_a031_UDSActive m0 : 34|1@1+ (1,0) [0|0] "" Vector__XXX
 SG_ VCFRONT1_a091_CMPD_MIA m1 : 34|1@1+ (1,0) [0|0] "" Vector__XXX
 SG_ VCFRONT1_a214_openCircuitDetected m3 : 37|1@1+ (1,0) [0|0] "" Vector__XXX
 SG_ VCFRONT1_a574_frontDriveInverterEFuseTrip m9 : 37|1@1+ (1,0) [0|0] "" Vector__XXX
 SG_ VCFRONT1_a036_UnknownIrq m0 : 39|1@1+ (1,0) [0|0] "" Vector__XXX
 SG_ VCFRONT1_a096_OCS1P_MIA m1 : 39|1@1+ (1,0) [0|0] "" Vector__XXX
 SG_ VCFRONT1_a216_powerCutoffImminent m3 : 39|1@1+ (1,0) [0|0] "" Vector__XXX
 SG_ VCFRONT1_a037_MemManageFault m0 : 40|1@1+ (1,0) [0|0] "" Vector__XXX
 SG_ VCFRONT1_a038_ProtFaultInfo m0 : 41|1@1+ (1,0) [0|0] "" Vector__XXX
 SG_ VCFRONT1_a098_DIR_MIA m1 : 41|1@1+ (1,0) [0|0] "" Vector__XXX
 SG_ VCFRONT1_a578_vbusFusedLoadShedEFuseTrip m9 : 41|1@1+ (1,0) [0|0] "" Vector__XXX
 SG_ VCFRONT1_a039_ProtFaultAddress m0 : 42|1@1+ (1,0) [0|0] "" Vector__XXX
 SG_ VCFRONT1_a040_Backtrace m0 : 43|1@1+ (1,0) [0|0] "" Vector__XXX
 SG_ VCFRONT1_a100_CANbus_MIA m1 : 43|1@1+ (1,0) [0|0] "" Vector__XXX
 SG_ VCFRONT1_a220_LVUnhealthy m3 : 43|1@1+ (1,0) [0|0] "" Vector__XXX
 SG_ VCFRONT1_a041_HighCPULoad m0 : 44|1@1+ (1,0) [0|0] "" Vector__XXX
 SG_ VCFRONT1_a581_harnessResistanceInfo m9 : 44|1@1+ (1,0) [0|0] "" Vector__XXX
 SG_ VCFRONT1_a042_HighStackUsage m0 : 45|1@1+ (1,0) [0|0] "" Vector__XXX
 SG_ VCFRONT1_a043_Task1msError m0 : 46|1@1+ (1,0) [0|0] "" Vector__XXX
 SG_ VCFRONT1_a103_CP_MIA m1 : 46|1@1+ (1,0) [0|0] "" Vector__XXX
 SG_ VCFRONT1_a223_bridgeOvervoltageSelfTestFailure m3 : 46|1@1+ (1,0) [0|0] "" Vector__XXX
 SG_ VCFRONT1_a044_Task10msError m0 : 47|1@1+ (1,0) [0|0] "" Vector__XXX
 SG_ VCFRONT1_a104_DAS_MIA m1 : 47|1@1+ (1,0) [0|0] "" Vector__XXX
 SG_ VCFRONT1_a164_eFuseLckoutMissing m2 : 47|1@1+ (1,0) [0|0] "" Vector__XXX
 SG_ VCFRONT1_a045_Task100msError m0 : 48|1@1+ (1,0) [0|0] "" Vector__XXX
 SG_ VCFRONT1_a105_TAS_MIA m1 : 48|1@1+ (1,0) [0|0] "" Vector__XXX
 SG_ VCFRONT1_a165_unxpctdEFuseLckout m2 : 48|1@1+ (1,0) [0|0] "" Vector__XXX
 SG_ VCFRONT1_a046_Task1000msError m0 : 49|1@1+ (1,0) [0|0] "" Vector__XXX
 SG_ VCFRONT1_a106_PCS_MIA m1 : 49|1@1+ (1,0) [0|0] "" Vector__XXX
 SG_ VCFRONT1_a107_BMS_MIA m1 : 50|1@1+ (1,0) [0|0] "" Vector__XXX
 SG_ VCFRONT1_a108_DIF_MIA m1 : 51|1@1+ (1,0) [0|0] "" Vector__XXX
 SG_ VCFRONT1_a229_LVHealthCompromised m3 : 52|1@1+ (1,0) [0|0] "" Vector__XXX
 SG_ VCFRONT1_a110_GTW_MIA m1 : 53|1@1+ (1,0) [0|0] "" Vector__XXX
 SG_ VCFRONT1_a590_vcrightPwrRationalityCurve m9 : 53|1@1+ (1,0) [0|0] "" Vector__XXX
 SG_ VCFRONT1_a111_EPBR_MIA m1 : 54|1@1+ (1,0) [0|0] "" Vector__XXX
 SG_ VCFRONT1_a591_vcrightFastBlowDetection m9 : 54|1@1+ (1,0) [0|0] "" Vector__XXX
 SG_ VCFRONT1_a112_EPBL_MIA m1 : 55|1@1+ (1,0) [0|0] "" Vector__XXX
 SG_ VCFRONT1_a113_UI_MIA m1 : 56|1@1+ (1,0) [0|0] "" Vector__XXX
 SG_ VCFRONT1_a114_ESP_MIA m1 : 57|1@1+ (1,0) [0|0] "" Vector__XXX
 SG_ VCFRONT1_a414_undervoltageSelfTestFailure m6 : 57|1@1+ (1,0) [0|0] "" Vector__XXX
 SG_ VCFRONT1_a115_VCSEC_MIA m1 : 58|1@1+ (1,0) [0|0] "" Vector__XXX
 SG_ VCFRONT1_a415_undervoltageSelfTestStuckOff m6 : 58|1@1+ (1,0) [0|0] "" Vector__XXX
 SG_ VCFRONT1_a475_vnf1248Fault m7 : 58|1@1+ (1,0) [0|0] "" Vector__XXX
 SG_ VCFRONT1_a116_VCRIGHT_MIA m1 : 59|1@1+ (1,0) [0|0] "" Vector__XXX
 SG_ VCFRONT1_a596_vcrightCurvePowerCutoff m9 : 59|1@1+ (1,0) [0|0] "" Vector__XXX
 SG_ VCFRONT1_a117_VCLEFT_MIA m1 : 60|1@1+ (1,0) [0|0] "" Vector__XXX
 SG_ VCFRONT1_a177_mcuAudioEFuseTrip m2 : 60|1@1+ (1,0) [0|0] "" Vector__XXX
 SG_ VCFRONT1_a597_vcrightFastBlowPowerCutoff m9 : 60|1@1+ (1,0) [0|0] "" Vector__XXX
 SG_ VCFRONT1_a058_inputRHighSyncDebug m0 : 61|1@1+ (1,0) [0|0] "" Vector__XXX
 SG_ VCFRONT1_a118_VCFRONT_MIA m1 : 61|1@1+ (1,0) [0|0] "" Vector__XXX
 SG_ VCFRONT1_a059_inputResistanceHigh m0 : 62|1@1+ (1,0) [0|0] "" Vector__XXX
 SG_ VCFRONT1_a119_SCCM_MIA m1 : 62|1@1+ (1,0) [0|0] "" Vector__XXX
 SG_ VCFRONT1_a060_engineeringBuild m0 : 63|1@1+ (1,0) [0|0] "" Vector__XXX
 SG_ VCFRONT1_a120_DI_DRIVE_MIA m1 : 63|1@1+ (1,0) [0|0] "" Vector__XXX

BO_ 834 VCFRONT2_alertMatrix: 8 Vector__XXX
 SG_ VCFRONT2_matrixIndex M : 0|4@1+ (1,0) [0|0] "" Vector__XXX
 SG_ VCFRONT2_a001_WatchdogReset m0 : 4|1@1+ (1,0) [0|0] "" Vector__XXX
 SG_ VCFRONT2_a061_XCPConnected m1 : 4|1@1+ (1,0) [0|0] "" Vector__XXX
 SG_ VCFRONT2_a301_wipersFactoryDisabled m5 : 4|1@1+ (1,0) [0|0] "" Vector__XXX
 SG_ VCFRONT2_a421_leftHeadlampUartCondition m7 : 4|1@1+ (1,0) [0|0] "" Vector__XXX
 SG_ VCFRONT2_a601_autopilotAirPurgeLimitReached m10 : 4|1@1+ (1,0) [0|0] "" Vector__XXX
 SG_ VCFRONT2_a661_mculessLeftHeadlampCurrentAlertDbg m11 : 4|1@1+ (1,0) [0|0] "" Vector__XXX
 SG_ VCFRONT2_a002_PowerLossReset m0 : 5|1@1+ (1,0) [0|0] "" Vector__XXX
 SG_ VCFRONT2_a062_XCPWasConnected m1 : 5|1@1+ (1,0) [0|0] "" Vector__XXX
 SG_ VCFRONT2_a122_ICR_MIA m2 : 5|1@1+ (1,0) [0|0] "" Vector__XXX
 SG_ VCFRONT2_a302_wiperCommError m5 : 5|1@1+ (1,0) [0|0] "" Vector__XXX
 SG_ VCFRONT2_a542_refrigerantReclaim m9 : 5|1@1+ (1,0) [0|0] "" Vector__XXX
 SG_ VCFRONT2_a003_SWAssertion m0 : 6|1@1+ (1,0) [0|0] "" Vector__XXX
 SG_ VCFRONT2_a063_SwitchFault m1 : 6|1@1+ (1,0) [0|0] "" Vector__XXX
 SG_ VCFRONT2_a123_VC_SECONDARY_LIGHTING_LEADER_MIA m2 : 6|1@1+ (1,0) [0|0] "" Vector__XXX
 SG_ VCFRONT2_a423_rtosSleepFailed m7 : 6|1@1+ (1,0) [0|0] "" Vector__XXX
 SG_ VCFRONT2_a543_compressorLowFlowDeliveryDetected m9 : 6|1@1+ (1,0) [0|0] "" Vector__XXX
 SG_ VCFRONT2_a663_leftHeadlampUartWaterMarkWarning m11 : 6|1@1+ (1,0) [0|0] "" Vector__XXX
 SG_ VCFRONT2_a064_busSleepReqTimeout m1 : 7|1@1+ (1,0) [0|0] "" Vector__XXX
 SG_ VCFRONT2_a124_BB_MIA m2 : 7|1@1+ (1,0) [0|0] "" Vector__XXX
 SG_ VCFRONT2_a184_cabinCoolingPerformanceAbnormal m3 : 7|1@1+ (1,0) [0|0] "" Vector__XXX
 SG_ VCFRONT2_a005_CANTXError m0 : 8|1@1+ (1,0) [0|0] "" Vector__XXX
 SG_ VCFRONT2_a125_SCCM_MIA m2 : 8|1@1+ (1,0) [0|0] "" Vector__XXX
 SG_ VCFRONT2_a365_burnInRoutineEntered m6 : 8|1@1+ (1,0) [0|0] "" Vector__XXX
 SG_ VCFRONT2_a665_leftHeadlampRetryInfo m11 : 8|1@1+ (1,0) [0|0] "" Vector__XXX
 SG_ VCFRONT2_a006_CANTX_cyclicError m0 : 9|1@1+ (1,0) [0|0] "" Vector__XXX
 SG_ VCFRONT2_a126_EPAS3P_MIA m2 : 9|1@1+ (1,0) [0|0] "" Vector__XXX
 SG_ VCFRONT2_a186_noDriveChgCableCon m3 : 9|1@1+ (1,0) [0|0] "" Vector__XXX
 SG_ VCFRONT2_a366_burnInRoutineExited m6 : 9|1@1+ (1,0) [0|0] "" Vector__XXX
 SG_ VCFRONT2_a546_leftLowOrHighBeamLightCondition m9 : 9|1@1+ (1,0) [0|0] "" Vector__XXX
 SG_ VCFRONT2_a606_chillerBattHeatingExit m10 : 9|1@1+ (1,0) [0|0] "" Vector__XXX
 SG_ VCFRONT2_a187_busesNotSleeping m3 : 10|1@1+ (1,0) [0|0] "" Vector__XXX
 SG_ VCFRONT2_a247_evapSolenoidFault m4 : 10|1@1+ (1,0) [0|0] "" Vector__XXX
 SG_ VCFRONT2_a367_dischargeRoutineEntered m6 : 10|1@1+ (1,0) [0|0] "" Vector__XXX
 SG_ VCFRONT2_a667_leftHeadlampRegionOrSideMismatch m11 : 10|1@1+ (1,0) [0|0] "" Vector__XXX
 SG_ VCFRONT2_a008_adaptiveHeadlightsUnavailableStalk m0 : 11|1@1+ (1,0) [0|0] "" Vector__XXX
 SG_ VCFRONT2_a188_sleepFailed m3 : 11|1@1+ (1,0) [0|0] "" Vector__XXX
 SG_ VCFRONT2_a368_dischargeRoutineExited m6 : 11|1@1+ (1,0) [0|0] "" Vector__XXX
 SG_ VCFRONT2_a009_LCCPurgeAttempted m0 : 12|1@1+ (1,0) [0|0] "" Vector__XXX
 SG_ VCFRONT2_a249_coolantValveBadMode m4 : 12|1@1+ (1,0) [0|0] "" Vector__XXX
 SG_ VCFRONT2_a369_reducedPowerDischarge m6 : 12|1@1+ (1,0) [0|0] "" Vector__XXX
 SG_ VCFRONT2_a489_ValveStuckFlagged m8 : 12|1@1+ (1,0) [0|0] "" Vector__XXX
 SG_ VCFRONT2_a669_thermalHVPowerBudgetActive m11 : 12|1@1+ (1,0) [0|0] "" Vector__XXX
 SG_ VCFRONT2_a250_headlampsNotAimed m4 : 13|1@1+ (1,0) [0|0] "" Vector__XXX
 SG_ VCFRONT2_a490_coolantPumpsNotIdentified m8 : 13|1@1+ (1,0) [0|0] "" Vector__XXX
 SG_ VCFRONT2_a610_driveEntryDelayed m10 : 13|1@1+ (1,0) [0|0] "" Vector__XXX
 SG_ VCFRONT2_a131_PCSCOMMON_MIA m2 : 14|1@1+ (1,0) [0|0] "" Vector__XXX
 SG_ VCFRONT2_a251_UIWakeupTrigger m4 : 14|1@1+ (1,0) [0|0] "" Vector__XXX
 SG_ VCFRONT2_a611_poorRadiatorHeatRejection m10 : 14|1@1+ (1,0) [0|0] "" Vector__XXX
 SG_ VCFRONT2_a012_CPUReset m0 : 15|1@1+ (1,0) [0|0] "" Vector__XXX
 SG_ VCFRONT2_a612_selfTestsBlockingDrive m10 : 15|1@1+ (1,0) [0|0] "" Vector__XXX
 SG_ VCFRONT2_a013_AlertManagerFault m0 : 16|1@1+ (1,0) [0|0] "" Vector__XXX
 SG_ VCFRONT2_a133_BRAKE_MIA m2 : 16|1@1+ (1,0) [0|0] "" Vector__XXX
 SG_ VCFRONT2_a254_pumpBatStopped m4 : 17|1@1+ (1,0) [0|0] "" Vector__XXX
 SG_ VCFRONT2_a374_lccInletSolenoidFault m6 : 17|1@1+ (1,0) [0|0] "" Vector__XXX
 SG_ VCFRONT2_a614_coolantSysDriverlessSelfTest m10 : 17|1@1+ (1,0) [0|0] "" Vector__XXX
 SG_ VCFRONT2_a015_NVMMError m0 : 18|1@1+ (1,0) [0|0] "" Vector__XXX
 SG_ VCFRONT2_a135_coolantLevelLow m2 : 18|1@1+ (1,0) [0|0] "" Vector__XXX
 SG_ VCFRONT2_a195_drveBlckdVltgeTooHgh m3 : 18|1@1+ (1,0) [0|0] "" Vector__XXX
 SG_ VCFRONT2_a016_NVMMRecordError m0 : 19|1@1+ (1,0) [0|0] "" Vector__XXX
 SG_ VCFRONT2_a136_refrigDischTempSns m2 : 19|1@1+ (1,0) [0|0] "" Vector__XXX
 SG_ VCFRONT2_a017_NVMMStatusDbg m0 : 20|1@1+ (1,0) [0|0] "" Vector__XXX
 SG_ VCFRONT2_a077_VCBATT0_MIA m1 : 20|1@1+ (1,0) [0|0] "" Vector__XXX
 SG_ VCFRONT2_a137_refrigDischPresSns m2 : 20|1@1+ (1,0) [0|0] "" Vector__XXX
 SG_ VCFRONT2_a377_wiperParkFault m6 : 20|1@1+ (1,0) [0|0] "" Vector__XXX
 SG_ VCFRONT2_a617_APP_MIA m10 : 20|1@1+ (1,0) [0|0] "" Vector__XXX
 SG_ VCFRONT2_a018_HardFault m0 : 21|1@1+ (1,0) [0|0] "" Vector__XXX
 SG_ VCFRONT2_a078_VCBATT1_MIA m1 : 21|1@1+ (1,0) [0|0] "" Vector__XXX
 SG_ VCFRONT2_a138_refrigSuctTempSns m2 : 21|1@1+ (1,0) [0|0] "" Vector__XXX
 SG_ VCFRONT2_a378_wiperECUDebug m6 : 21|1@1+ (1,0) [0|0] "" Vector__XXX
 SG_ VCFRONT2_a618_cabinCoolingCapacityLimited m10 : 21|1@1+ (1,0) [0|0] "" Vector__XXX
 SG_ VCFRONT2_a019_BusFault m0 : 22|1@1+ (1,0) [0|0] "" Vector__XXX
 SG_ VCFRONT2_a079_VCBATT2_MIA m1 : 22|1@1+ (1,0) [0|0] "" Vector__XXX
 SG_ VCFRONT2_a139_refrigSuctPresSns m2 : 22|1@1+ (1,0) [0|0] "" Vector__XXX
 SG_ VCFRONT2_a499_loadShedPumpFlowRequest m8 : 22|1@1+ (1,0) [0|0] "" Vector__XXX
 SG_ VCFRONT2_a080_VCFRONT0_MIA m1 : 23|1@1+ (1,0) [0|0] "" Vector__XXX
 SG_ VCFRONT2_a140_coolantTempPtSns m2 : 23|1@1+ (1,0) [0|0] "" Vector__XXX
 SG_ VCFRONT2_a380_chillerExvWarning m6 : 23|1@1+ (1,0) [0|0] "" Vector__XXX
 SG_ VCFRONT2_a560_compressorHighSuperheat m9 : 23|1@1+ (1,0) [0|0] "" Vector__XXX
 SG_ VCFRONT2_a620_pumpAirLock m10 : 23|1@1+ (1,0) [0|0] "" Vector__XXX
 SG_ VCFRONT2_a021_TaskSchedulerError m0 : 24|1@1+ (1,0) [0|0] "" Vector__XXX
 SG_ VCFRONT2_a081_VCFRONT1_MIA m1 : 24|1@1+ (1,0) [0|0] "" Vector__XXX
 SG_ VCFRONT2_a141_coolantTempBatSns m2 : 24|1@1+ (1,0) [0|0] "" Vector__XXX
 SG_ VCFRONT2_a381_evaporatorExvWarning m6 : 24|1@1+ (1,0) [0|0] "" Vector__XXX
 SG_ VCFRONT2_a621_coolantAirPurgeIncomplete m10 : 24|1@1+ (1,0) [0|0] "" Vector__XXX
 SG_ VCFRONT2_a022_TaskInitError m0 : 25|1@1+ (1,0) [0|0] "" Vector__XXX
 SG_ VCFRONT2_a082_VCFRONT2_MIA m1 : 25|1@1+ (1,0) [0|0] "" Vector__XXX
 SG_ VCFRONT2_a142_exvMotorFault m2 : 25|1@1+ (1,0) [0|0] "" Vector__XXX
 SG_ VCFRONT2_a382_recircExvWarning m6 : 25|1@1+ (1,0) [0|0] "" Vector__XXX
 SG_ VCFRONT2_a622_pumpDetectsLowCoolantFlow m10 : 25|1@1+ (1,0) [0|0] "" Vector__XXX
 SG_ VCFRONT2_a143_powerLossDuringSleep m2 : 26|1@1+ (1,0) [0|0] "" Vector__XXX
 SG_ VCFRONT2_a383_lccExvWarning m6 : 26|1@1+ (1,0) [0|0] "" Vector__XXX
 SG_ VCFRONT2_a563_chargePortDoorOpenBlockedByBrake m9 : 26|1@1+ (1,0) [0|0] "" Vector__XXX
 SG_ VCFRONT2_a144_EPAS3S_MIA m2 : 27|1@1+ (1,0) [0|0] "" Vector__XXX
 SG_ VCFRONT2_a384_ccLeftExvWarning m6 : 27|1@1+ (1,0) [0|0] "" Vector__XXX
 SG_ VCFRONT2_a504_airInRefrigerantDetected m8 : 27|1@1+ (1,0) [0|0] "" Vector__XXX
 SG_ VCFRONT2_a564_leftHeadlampAimingDebug m9 : 27|1@1+ (1,0) [0|0] "" Vector__XXX
 SG_ VCFRONT2_a385_ccRightExvWarning m6 : 28|1@1+ (1,0) [0|0] "" Vector__XXX
 SG_ VCFRONT2_a565_userPresenceDisplayStateMismatch m9 : 28|1@1+ (1,0) [0|0] "" Vector__XXX
 SG_ VCFRONT2_a086_VCBATT_MIA m1 : 29|1@1+ (1,0) [0|0] "" Vector__XXX
 SG_ VCFRONT2_a386_exvMotorWarning m6 : 29|1@1+ (1,0) [0|0] "" Vector__XXX
 SG_ VCFRONT2_a446_cabinHVACUnavailableContext m7 : 29|1@1+ (1,0) [0|0] "" Vector__XXX
 SG_ VCFRONT2_a506_invalidRefrigerantSystemConfig m8 : 29|1@1+ (1,0) [0|0] "" Vector__XXX
 SG_ VCFRONT2_a566_leftFrontTurnLightFault m9 : 29|1@1+ (1,0) [0|0] "" Vector__XXX
 SG_ VCFRONT2_a447_cabinHVACUnavailable m7 : 30|1@1+ (1,0) [0|0] "" Vector__XXX
 SG_ VCFRONT2_a507_leftHeadlampAimingFault m8 : 30|1@1+ (1,0) [0|0] "" Vector__XXX
 SG_ VCFRONT2_a028_UsageFault m0 : 31|1@1+ (1,0) [0|0] "" Vector__XXX
 SG_ VCFRONT2_a568_leftDaytimeRunningLightFault m9 : 31|1@1+ (1,0) [0|0] "" Vector__XXX
 SG_ VCFRONT2_a029_CoreDump m0 : 32|1@1+ (1,0) [0|0] "" Vector__XXX
 SG_ VCFRONT2_a030_ECULogUploadRequest m0 : 33|1@1+ (1,0) [0|0] "" Vector__XXX
 SG_ VCFRONT2_a090_APS_MIA m1 : 33|1@1+ (1,0) [0|0] "" Vector__XXX
 SG_ VCFRONT2_a150_pumpBatLowRPMCBang m2 : 33|1@1+ (1,0) [0|0] "" Vector__XXX
 SG_ VCFRONT2_a210_coolantValveCalib m3 : 33|1@1+ (1,0) [0|0] "" Vector__XXX
 SG_ VCFRONT2_a570_headlampsAdaptedToLeftHandTraffic m9 : 33|1@1+ (1,0) [0|0] "" Vector__XXX
 SG_ VCFRONT2_a630_leftHeadlampFactoryFault m10 : 33|1@1+ (1,0) [0|0] "" Vector__XXX
 SG_ VCFRONT2_a031_UDSActive m0 : 34|1@1+ (1,0) [0|0] "" Vector__XXX
 SG_ VCFRONT2_a091_CMPD_MIA m1 : 34|1@1+ (1,0) [0|0] "" Vector__XXX
 SG_ VCFRONT2_a451_refrigerantNotCommissioned m7 : 34|1@1+ (1,0) [0|0] "" Vector__XXX
 SG_ VCFRONT2_a511_DCDCSaturationLoadShed m8 : 34|1@1+ (1,0) [0|0] "" Vector__XXX
 SG_ VCFRONT2_a571_headlampsAdaptedToRightHandTraffic m9 : 34|1@1+ (1,0) [0|0] "" Vector__XXX
 SG_ VCFRONT2_a452_dischargePresSensIntermittent m7 : 35|1@1+ (1,0) [0|0] "" Vector__XXX
 SG_ VCFRONT2_a572_hvacCompressorEFuseTrip m9 : 35|1@1+ (1,0) [0|0] "" Vector__XXX
 SG_ VCFRONT2_a153_userPresenceDisplayMismatchClrd m2 : 36|1@1+ (1,0) [0|0] "" Vector__XXX
 SG_ VCFRONT2_a273_wiperFrictionModelFault m4 : 36|1@1+ (1,0) [0|0] "" Vector__XXX
 SG_ VCFRONT2_a393_ambientTempNetworkSna m6 : 36|1@1+ (1,0) [0|0] "" Vector__XXX
 SG_ VCFRONT2_a453_dischargeTempSensIntermittent m7 : 36|1@1+ (1,0) [0|0] "" Vector__XXX
 SG_ VCFRONT2_a214_ptPumpCompromised m3 : 37|1@1+ (1,0) [0|0] "" Vector__XXX
 SG_ VCFRONT2_a394_pressureSensorCheckFault m6 : 37|1@1+ (1,0) [0|0] "" Vector__XXX
 SG_ VCFRONT2_a454_suctionPresSensIntermittent m7 : 37|1@1+ (1,0) [0|0] "" Vector__XXX
 SG_ VCFRONT2_a155_autopilotDriveNotAuthed m2 : 38|1@1+ (1,0) [0|0] "" Vector__XXX
 SG_ VCFRONT2_a215_ptPumpMIA m3 : 38|1@1+ (1,0) [0|0] "" Vector__XXX
 SG_ VCFRONT2_a395_pressureSensorCheckInconclusive m6 : 38|1@1+ (1,0) [0|0] "" Vector__XXX
 SG_ VCFRONT2_a455_suctionTempSensIntermittent m7 : 38|1@1+ (1,0) [0|0] "" Vector__XXX
 SG_ VCFRONT2_a036_UnknownIrq m0 : 39|1@1+ (1,0) [0|0] "" Vector__XXX
 SG_ VCFRONT2_a096_OCS1P_MIA m1 : 39|1@1+ (1,0) [0|0] "" Vector__XXX
 SG_ VCFRONT2_a396_coolantLevelLowUserFacing m6 : 39|1@1+ (1,0) [0|0] "" Vector__XXX
 SG_ VCFRONT2_a456_liquidPresSensIntermittent m7 : 39|1@1+ (1,0) [0|0] "" Vector__XXX
 SG_ VCFRONT2_a037_MemManageFault m0 : 40|1@1+ (1,0) [0|0] "" Vector__XXX
 SG_ VCFRONT2_a217_battPumpCompromised m3 : 40|1@1+ (1,0) [0|0] "" Vector__XXX
 SG_ VCFRONT2_a397_temperatureSensorCheckFault m6 : 40|1@1+ (1,0) [0|0] "" Vector__XXX
 SG_ VCFRONT2_a457_liquidTempSensIntermittent m7 : 40|1@1+ (1,0) [0|0] "" Vector__XXX
 SG_ VCFRONT2_a697_leftHeadlampNotAimed m11 : 40|1@1+ (1,0) [0|0] "" Vector__XXX
 SG_ VCFRONT2_a038_ProtFaultInfo m0 : 41|1@1+ (1,0) [0|0] "" Vector__XXX
 SG_ VCFRONT2_a098_DIR_MIA m1 : 41|1@1+ (1,0) [0|0] "" Vector__XXX
 SG_ VCFRONT2_a218_socMonitorDetectedThresholdSoc m3 : 41|1@1+ (1,0) [0|0] "" Vector__XXX
 SG_ VCFRONT2_a398_tempSensorCheckInconclusive m6 : 41|1@1+ (1,0) [0|0] "" Vector__XXX
 SG_ VCFRONT2_a458_grosslyLowRefrigerant m7 : 41|1@1+ (1,0) [0|0] "" Vector__XXX
 SG_ VCFRONT2_a578_vbusFusedLowCurrentFeedEFuseTrip m9 : 41|1@1+ (1,0) [0|0] "" Vector__XXX
 SG_ VCFRONT2_a039_ProtFaultAddress m0 : 42|1@1+ (1,0) [0|0] "" Vector__XXX
 SG_ VCFRONT2_a159_coolantValveFault m2 : 42|1@1+ (1,0) [0|0] "" Vector__XXX
 SG_ VCFRONT2_a279_refrigLiquidTempSns m4 : 42|1@1+ (1,0) [0|0] "" Vector__XXX
 SG_ VCFRONT2_a459_thermalFillAndDrive m7 : 42|1@1+ (1,0) [0|0] "" Vector__XXX
 SG_ VCFRONT2_a040_Backtrace m0 : 43|1@1+ (1,0) [0|0] "" Vector__XXX
 SG_ VCFRONT2_a100_CANbus_MIA m1 : 43|1@1+ (1,0) [0|0] "" Vector__XXX
 SG_ VCFRONT2_a160_compressorInhibited m2 : 43|1@1+ (1,0) [0|0] "" Vector__XXX
 SG_ VCFRONT2_a280_refrigLiquidPresSns m4 : 43|1@1+ (1,0) [0|0] "" Vector__XXX
 SG_ VCFRONT2_a460_hardIsentropicTdFailed m7 : 43|1@1+ (1,0) [0|0] "" Vector__XXX
 SG_ VCFRONT2_a041_HighCPULoad m0 : 44|1@1+ (1,0) [0|0] "" Vector__XXX
 SG_ VCFRONT2_a161_compressorSelfFault m2 : 44|1@1+ (1,0) [0|0] "" Vector__XXX
 SG_ VCFRONT2_a281_alcoholInterlockBlockingDrive m4 : 44|1@1+ (1,0) [0|0] "" Vector__XXX
 SG_ VCFRONT2_a042_HighStackUsage m0 : 45|1@1+ (1,0) [0|0] "" Vector__XXX
 SG_ VCFRONT2_a162_compressorInhibitedContext m2 : 45|1@1+ (1,0) [0|0] "" Vector__XXX
 SG_ VCFRONT2_a282_coolantLevelSensorFault m4 : 45|1@1+ (1,0) [0|0] "" Vector__XXX
 SG_ VCFRONT2_a043_Task1msError m0 : 46|1@1+ (1,0) [0|0] "" Vector__XXX
 SG_ VCFRONT2_a103_CP_MIA m1 : 46|1@1+ (1,0) [0|0] "" Vector__XXX
 SG_ VCFRONT2_a163_compressorDisabledFSR m2 : 46|1@1+ (1,0) [0|0] "" Vector__XXX
 SG_ VCFRONT2_a283_thmlFanLimitedByCurrent m4 : 46|1@1+ (1,0) [0|0] "" Vector__XXX
 SG_ VCFRONT2_a044_Task10msError m0 : 47|1@1+ (1,0) [0|0] "" Vector__XXX
 SG_ VCFRONT2_a104_DAS_MIA m1 : 47|1@1+ (1,0) [0|0] "" Vector__XXX
 SG_ VCFRONT2_a284_chillerExvFault m4 : 47|1@1+ (1,0) [0|0] "" Vector__XXX
 SG_ VCFRONT2_a464_highFlowIndexHighSubcoolFlagged m7 : 47|1@1+ (1,0) [0|0] "" Vector__XXX
 SG_ VCFRONT2_a045_Task100msError m0 : 48|1@1+ (1,0) [0|0] "" Vector__XXX
 SG_ VCFRONT2_a105_TAS_MIA m1 : 48|1@1+ (1,0) [0|0] "" Vector__XXX
 SG_ VCFRONT2_a225_driveBlckdByShowroom m3 : 48|1@1+ (1,0) [0|0] "" Vector__XXX
 SG_ VCFRONT2_a285_evaporatorExvFault m4 : 48|1@1+ (1,0) [0|0] "" Vector__XXX
 SG_ VCFRONT2_a465_lowFlowIndexHighSubcoolFlagged m7 : 48|1@1+ (1,0) [0|0] "" Vector__XXX
 SG_ VCFRONT2_a585_bothHeadlampsInternalError m9 : 48|1@1+ (1,0) [0|0] "" Vector__XXX
 SG_ VCFRONT2_a046_Task1000msError m0 : 49|1@1+ (1,0) [0|0] "" Vector__XXX
 SG_ VCFRONT2_a106_PCS_MIA m1 : 49|1@1+ (1,0) [0|0] "" Vector__XXX
 SG_ VCFRONT2_a226_battPumpMIA m3 : 49|1@1+ (1,0) [0|0] "" Vector__XXX
 SG_ VCFRONT2_a286_recircExvFault m4 : 49|1@1+ (1,0) [0|0] "" Vector__XXX
 SG_ VCFRONT2_a466_highFlowIndexLowSubcoolFlagged m7 : 49|1@1+ (1,0) [0|0] "" Vector__XXX
 SG_ VCFRONT2_a107_BMS_MIA m1 : 50|1@1+ (1,0) [0|0] "" Vector__XXX
 SG_ VCFRONT2_a167_leftHCMMIA m2 : 50|1@1+ (1,0) [0|0] "" Vector__XXX
 SG_ VCFRONT2_a287_lccExvFault m4 : 50|1@1+ (1,0) [0|0] "" Vector__XXX
 SG_ VCFRONT2_a467_lowPowerIndexFlagged m7 : 50|1@1+ (1,0) [0|0] "" Vector__XXX
 SG_ VCFRONT2_a108_DIF_MIA m1 : 51|1@1+ (1,0) [0|0] "" Vector__XXX
 SG_ VCFRONT2_a288_ccLeftExvFault m4 : 51|1@1+ (1,0) [0|0] "" Vector__XXX
 SG_ VCFRONT2_a468_highPowerIndexFlagged m7 : 51|1@1+ (1,0) [0|0] "" Vector__XXX
 SG_ VCFRONT2_a289_ccRightExvFault m4 : 52|1@1+ (1,0) [0|0] "" Vector__XXX
 SG_ VCFRONT2_a409_invalidConfiguration m6 : 52|1@1+ (1,0) [0|0] "" Vector__XXX
 SG_ VCFRONT2_a469_prvPopDetected m7 : 52|1@1+ (1,0) [0|0] "" Vector__XXX
 SG_ VCFRONT2_a110_GTW_MIA m1 : 53|1@1+ (1,0) [0|0] "" Vector__XXX
 SG_ VCFRONT2_a470_implausiblePdPlDetected m7 : 53|1@1+ (1,0) [0|0] "" Vector__XXX
 SG_ VCFRONT2_a111_EPBR_MIA m1 : 54|1@1+ (1,0) [0|0] "" Vector__XXX
 SG_ VCFRONT2_a171_driveBlckdByMsmtch m2 : 54|1@1+ (1,0) [0|0] "" Vector__XXX
 SG_ VCFRONT2_a471_hcm5Debug m7 : 54|1@1+ (1,0) [0|0] "" Vector__XXX
 SG_ VCFRONT2_a531_lowPowerIndexFlaggedUserFacing m8 : 54|1@1+ (1,0) [0|0] "" Vector__XXX
 SG_ VCFRONT2_a112_EPBL_MIA m1 : 55|1@1+ (1,0) [0|0] "" Vector__XXX
 SG_ VCFRONT2_a172_wsteHtBlckdByMsmtch m2 : 55|1@1+ (1,0) [0|0] "" Vector__XXX
 SG_ VCFRONT2_a232_lowSideControllerHighFdbk m3 : 55|1@1+ (1,0) [0|0] "" Vector__XXX
 SG_ VCFRONT2_a053_wiperCommErrorUser m0 : 56|1@1+ (1,0) [0|0] "" Vector__XXX
 SG_ VCFRONT2_a113_UI_MIA m1 : 56|1@1+ (1,0) [0|0] "" Vector__XXX
 SG_ VCFRONT2_a173_HVBlckdByMsmtch m2 : 56|1@1+ (1,0) [0|0] "" Vector__XXX
 SG_ VCFRONT2_a054_compressorLowFlowUserFacing m0 : 57|1@1+ (1,0) [0|0] "" Vector__XXX
 SG_ VCFRONT2_a114_ESP_MIA m1 : 57|1@1+ (1,0) [0|0] "" Vector__XXX
 SG_ VCFRONT2_a174_driveNotAuthed m2 : 57|1@1+ (1,0) [0|0] "" Vector__XXX
 SG_ VCFRONT2_a294_leftSideRepeaterLightFault m4 : 57|1@1+ (1,0) [0|0] "" Vector__XXX
 SG_ VCFRONT2_a474_leftHeadlampInternalError m7 : 57|1@1+ (1,0) [0|0] "" Vector__XXX
 SG_ VCFRONT2_a534_chillerExvCalibInitDebug m8 : 57|1@1+ (1,0) [0|0] "" Vector__XXX
 SG_ VCFRONT2_a115_VCSEC_MIA m1 : 58|1@1+ (1,0) [0|0] "" Vector__XXX
 SG_ VCFRONT2_a235_ptTempSnsIrrational m3 : 58|1@1+ (1,0) [0|0] "" Vector__XXX
 SG_ VCFRONT2_a355_coolantSysLockout m5 : 58|1@1+ (1,0) [0|0] "" Vector__XXX
 SG_ VCFRONT2_a535_evapExvCalibInitDebug m8 : 58|1@1+ (1,0) [0|0] "" Vector__XXX
 SG_ VCFRONT2_a116_VCRIGHT_MIA m1 : 59|1@1+ (1,0) [0|0] "" Vector__XXX
 SG_ VCFRONT2_a176_vehicleInSelfTest m2 : 59|1@1+ (1,0) [0|0] "" Vector__XXX
 SG_ VCFRONT2_a236_batTempSnsIrrational m3 : 59|1@1+ (1,0) [0|0] "" Vector__XXX
 SG_ VCFRONT2_a356_refrigSysLockout m5 : 59|1@1+ (1,0) [0|0] "" Vector__XXX
 SG_ VCFRONT2_a536_recircExvCalibInitDebug m8 : 59|1@1+ (1,0) [0|0] "" Vector__XXX
 SG_ VCFRONT2_a117_VCLEFT_MIA m1 : 60|1@1+ (1,0) [0|0] "" Vector__XXX
 SG_ VCFRONT2_a537_lccExvCalibInitDebug m8 : 60|1@1+ (1,0) [0|0] "" Vector__XXX
 SG_ VCFRONT2_a058_inputRHighSyncDebug m0 : 61|1@1+ (1,0) [0|0] "" Vector__XXX
 SG_ VCFRONT2_a118_VCFRONT_MIA m1 : 61|1@1+ (1,0) [0|0] "" Vector__XXX
 SG_ VCFRONT2_a178_compLiquidPumpOut m2 : 61|1@1+ (1,0) [0|0] "" Vector__XXX
 SG_ VCFRONT2_a298_radiatorLowAirFlowDetected m4 : 61|1@1+ (1,0) [0|0] "" Vector__XXX
 SG_ VCFRONT2_a538_cclExvCalibInitDebug m8 : 61|1@1+ (1,0) [0|0] "" Vector__XXX
 SG_ VCFRONT2_a059_inputResistanceHigh m0 : 62|1@1+ (1,0) [0|0] "" Vector__XXX
 SG_ VCFRONT2_a119_SCCM_MIA m1 : 62|1@1+ (1,0) [0|0] "" Vector__XXX
 SG_ VCFRONT2_a539_ccrExvCalibInitDebug m8 : 62|1@1+ (1,0) [0|0] "" Vector__XXX
 SG_ VCFRONT2_a060_engineeringBuild m0 : 63|1@1+ (1,0) [0|0] "" Vector__XXX
 SG_ VCFRONT2_a120_DI_DRIVE_MIA m1 : 63|1@1+ (1,0) [0|0] "" Vector__XXX
 SG_ VCFRONT2_a240_lowSideCompromised m3 : 63|1@1+ (1,0) [0|0] "" Vector__XXX
 SG_ VCFRONT2_a360_ungracefulAccPlusExit m5 : 63|1@1+ (1,0) [0|0] "" Vector__XXX
 SG_ VCFRONT2_a420_holidayParty m6 : 63|1@1+ (1,0) [0|0] "" Vector__XXX
 SG_ VCFRONT2_a540_radiatorSteamDetected m8 : 63|1@1+ (1,0) [0|0] "" Vector__XXX

BO_ 835 VCRIGHT_status: 8 Vector__XXX
 SG_ VCRIGHT_autonomyBehaviorStatus : 6|2@1+ (1,0) [0|0] "" Vector__XXX
 SG_ VCRIGHT_LVBatteryTypeDBG : 8|3@1+ (1,0) [0|0] "" Vector__XXX
 SG_ VCRIGHT_rearDefrostState : 11|3@1+ (1,0) [0|0] "" Vector__XXX
 SG_ VCRIGHT_mirrorHeatState : 14|3@1+ (1,0) [0|0] "" Vector__XXX
 SG_ VCRIGHT_OTAState : 17|1@1+ (1,0) [0|0] "" Vector__XXX
 SG_ VCRIGHT_5AVoltage : 18|10@1+ (0.005443676098,0) [0|0] "" Vector__XXX
 SG_ VCRIGHT_vbatProt : 28|12@1+ (0.005443676098,0) [0|0] "" Vector__XXX
 SG_ VCRIGHT_rationalityAggregateCurrent : 40|8@1+ (0.5,0) [0|0] "" Vector__XXX
 SG_ VCRIGHT_eFuseMgmtVoltageMonitor : 48|7@1+ (0.125,0) [0|0] "" Vector__XXX
 SG_ VCRIGHT_isSteeringWheelHeaterReq : 55|1@1+ (1,0) [0|0] "" Vector__XXX
 SG_ VCRIGHT_steeringWheelHeaterDCTgt : 56|7@1+ (0.01,0) [0|0] "" Vector__XXX

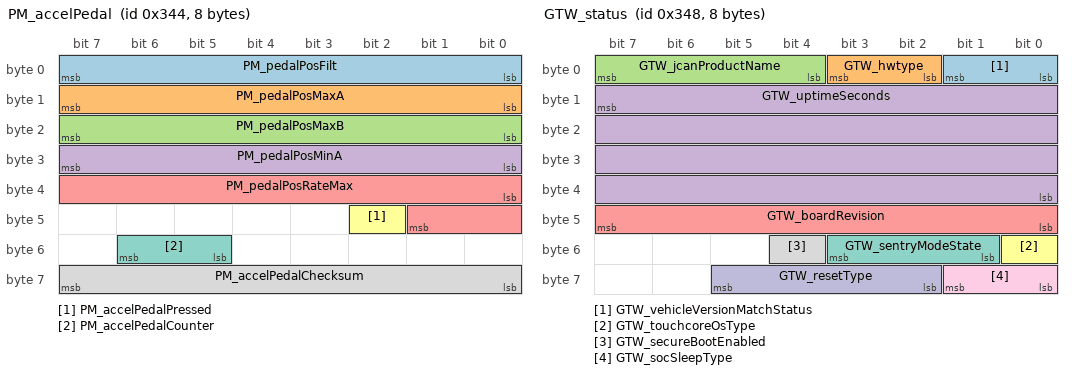
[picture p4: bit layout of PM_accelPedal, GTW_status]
BO_ 836 PM_accelPedal: 8 Vector__XXX
 SG_ PM_pedalPosFilt : 0|8@1+ (0.4,0) [0|0] "" Vector__XXX
 SG_ PM_pedalPosMaxA : 8|8@1+ (0.4,0) [0|0] "" Vector__XXX
 SG_ PM_pedalPosMaxB : 16|8@1+ (0.4,0) [0|0] "" Vector__XXX
 SG_ PM_pedalPosMinA : 24|8@1+ (0.4,0) [0|0] "" Vector__XXX
 SG_ PM_pedalPosRateMax : 32|10@1+ (3,0) [0|0] "" Vector__XXX
 SG_ PM_accelPedalPressed : 42|1@1+ (1,0) [0|0] "" Vector__XXX
 SG_ PM_accelPedalCounter : 53|2@1+ (1,0) [0|0] "" Vector__XXX
 SG_ PM_accelPedalChecksum : 56|8@1+ (1,0) [0|0] "" Vector__XXX

BO_ 837 PTC_info: 8 Vector__XXX
 SG_ PTC_infoIndex M : 0|8@1+ (1,0) [0|0] "" Vector__XXX
 SG_ PTC_infoAppGitHash m17 : 8|56@1+ (1,0) [0|0] "" Vector__XXX
 SG_ PTC_infoBootGitHash m18 : 8|56@1+ (1,0) [0|0] "" Vector__XXX
 SG_ PTC_infoBootSvnRev m14 : 8|24@1+ (1,0) [0|0] "" Vector__XXX
 SG_ PTC_infoBootUdsProtoVersion m20 : 8|8@1+ (1,0) [0|0] "" Vector__XXX
 SG_ PTC_infoBuildType m10 : 8|3@1+ (1,0) [0|0] "" Vector__XXX
 SG_ PTC_infoPlatformType m13 : 8|8@1+ (1,0) [0|0] "" Vector__XXX
 SG_ PTC_infoBuildConfigId m10 : 16|16@1+ (1,0) [0|0] "" Vector__XXX
 SG_ PTC_infoPcbaId m11 : 16|8@1+ (1,0) [0|0] "" Vector__XXX
 SG_ PTC_infoAssemblyId m11 : 24|8@1+ (1,0) [0|0] "" Vector__XXX
 SG_ PTC_infoAppCrc m13 : 32|32@1+ (1,0) [0|0] "" Vector__XXX
 SG_ PTC_infoBootCrc m20 : 32|32@1+ (1,0) [0|0] "" Vector__XXX
 SG_ PTC_infoBootSvnUrlHash m14 : 32|32@1+ (1,0) [0|0] "" Vector__XXX
 SG_ PTC_infoHardwareId m10 : 32|16@1+ (1,0) [0|0] "" Vector__XXX
 SG_ PTC_infoUsageId m11 : 32|16@1+ (1,0) [0|0] "" Vector__XXX
 SG_ PTC_infoComponentId m10 : 48|16@1+ (1,0) [0|0] "" Vector__XXX
 SG_ PTC_infoSubUsageId m11 : 48|16@1+ (1,0) [0|0] "" Vector__XXX

BO_ 840 GTW_status: 8 Vector__XXX
 SG_ GTW_vehicleVersionMatchStatus : 0|2@1+ (1,0) [0|0] "" Vector__XXX
 SG_ GTW_hwtype : 2|2@1+ (1,0) [0|0] "" Vector__XXX
 SG_ GTW_jcanProductName : 4|4@1+ (1,0) [0|0] "" Vector__XXX
 SG_ GTW_uptimeSeconds : 15|32@0+ (1,0) [0|0] "" Vector__XXX
 SG_ GTW_boardRevision : 40|8@1+ (1,0) [0|0] "" Vector__XXX
 SG_ GTW_touchcoreOsType : 48|1@1+ (1,0) [0|0] "" Vector__XXX
 SG_ GTW_sentryModeState : 49|3@1+ (1,0) [0|0] "" Vector__XXX
 SG_ GTW_secureBootEnabled : 52|1@1+ (1,0) [0|0] "" Vector__XXX
 SG_ GTW_socSleepType : 56|2@1+ (1,0) [0|0] "" Vector__XXX
 SG_ GTW_resetType : 58|4@1+ (1,0) [0|0] "" Vector__XXX

BO_ 842 VCSEC_NFCDebug: 8 Vector__XXX
 SG_ VCSEC_NFCReaderIndexDebug M : 0|2@1+ (1,0) [0|0] "" Vector__XXX
 SG_ VCSEC_BPillarNFCCardCollisionL m0 : 3|1@1+ (1,0) [0|0] "" Vector__XXX
 SG_ VCSEC_BPillarNFCCardCollisionR m1 : 3|1@1+ (1,0) [0|0] "" Vector__XXX
 SG_ VCSEC_BPillarNFCPhaseL m3 : 3|8@1+ (1,0) [0|0] "" Vector__XXX
 SG_ VCSEC_CenterNFCCardCollision m2 : 3|1@1+ (1,0) [0|0] "" Vector__XXX
 SG_ VCSEC_BPillarNFCCardUIDSizeL m0 : 4|4@1+ (1,0) [0|0] "" Vector__XXX
 SG_ VCSEC_BPillarNFCCardUIDSizeR m1 : 4|4@1+ (1,0) [0|0] "" Vector__XXX
 SG_ VCSEC_CenterNFCCardUIDSize m2 : 4|4@1+ (1,0) [0|0] "" Vector__XXX
 SG_ VCSEC_BPillarNFCTrimSettingL m0 : 8|4@1+ (1,0) [0|0] "" Vector__XXX
 SG_ VCSEC_BPillarNFCTrimSettingR m1 : 8|4@1+ (1,0) [0|0] "" Vector__XXX
 SG_ VCSEC_CenterNFCTrimSetting m2 : 8|4@1+ (1,0) [0|0] "" Vector__XXX
 SG_ VCSEC_BPillarNFCPhaseR m3 : 11|8@1+ (1,0) [0|0] "" Vector__XXX
 SG_ VCSEC_BPillarNFCWakeUpCounterL m0 : 12|16@1+ (1,0) [0|0] "" Vector__XXX
 SG_ VCSEC_BPillarNFCWakeUpCounterR m1 : 12|16@1+ (1,0) [0|0] "" Vector__XXX
 SG_ VCSEC_CenterNFCCardATQa m2 : 12|16@1+ (1,0) [0|0] "" Vector__XXX
 SG_ VCSEC_CenterNFCPhase m3 : 19|8@1+ (1,0) [0|0] "" Vector__XXX
 SG_ VCSEC_BPillarNFCReaderStateL m0 : 28|2@1+ (1,0) [0|0] "" Vector__XXX
 SG_ VCSEC_BPillarNFCReaderStateR m1 : 28|2@1+ (1,0) [0|0] "" Vector__XXX
 SG_ VCSEC_CenterNFCReaderState m2 : 28|2@1+ (1,0) [0|0] "" Vector__XXX
 SG_ VCSEC_BPillarNFCAmplitudeL m0 : 36|8@1+ (1,0) [0|0] "" Vector__XXX
 SG_ VCSEC_BPillarNFCAmplitudeR m1 : 36|8@1+ (1,0) [0|0] "" Vector__XXX
 SG_ VCSEC_CenterNFCAmplitude m2 : 36|8@1+ (1,0) [0|0] "" Vector__XXX
 SG_ VCSEC_BPillarNFCDevLayerStateL m0 : 44|8@1+ (1,0) [0|0] "" Vector__XXX
 SG_ VCSEC_BPillarNFCDevLayerStateR m1 : 44|8@1+ (1,0) [0|0] "" Vector__XXX
 SG_ VCSEC_CenterNFCDevLayerState m2 : 44|8@1+ (1,0) [0|0] "" Vector__XXX
 SG_ VCSEC_BPillarNFCAntennaCalResultL m0 : 52|8@1+ (1,0) [0|0] "" Vector__XXX
 SG_ VCSEC_BPillarNFCAntennaCalResultR m1 : 52|8@1+ (1,0) [0|0] "" Vector__XXX
 SG_ VCSEC_CenterNFCAntennaCalResult m2 : 52|8@1+ (1,0) [0|0] "" Vector__XXX
 SG_ VCSEC_BPillarNFCStateReasonL m0 : 60|3@1+ (1,0) [0|0] "" Vector__XXX
 SG_ VCSEC_BPillarNFCStateReasonR m1 : 60|3@1+ (1,0) [0|0] "" Vector__XXX
 SG_ VCSEC_CenterNFCStateReason m2 : 60|4@1+ (1,0) [0|0] "" Vector__XXX

BO_ 850 BMS_energyStatus: 8 Vector__XXX
 SG_ BMS_energyStatusMultiplexer M : 0|2@1+ (1,0) [0|0] "" Vector__XXX
 SG_ BMS_energyRemainingDisplay m2 : 8|16@1+ (0.02,0) [0|0] "" Vector__XXX
 SG_ BMS_fullChargeComplete m1 : 15|1@1+ (1,0) [0|0] "" Vector__XXX
 SG_ BMS_energyBuffer m1 : 16|16@1+ (0.01,0) [0|0] "" Vector__XXX
 SG_ BMS_nominalFullPackEnergy m0 : 16|16@1+ (0.02,0) [0|0] "" Vector__XXX
 SG_ BMS_energyRemainingTDisplay m2 : 24|16@1+ (0.02,0) [0|0] "" Vector__XXX
 SG_ BMS_expectedEnergyRemaining m1 : 32|16@1+ (0.02,0) [0|0] "" Vector__XXX
 SG_ BMS_nominalEnergyRemaining m0 : 32|16@1+ (0.02,0) [0|0] "" Vector__XXX
 SG_ BMS_energyDisplayErrorBlendRate m2 : 40|12@1+ (0.01562881562881563,0) [0|0] "" Vector__XXX
 SG_ BMS_energyToChargeComplete m1 : 48|16@1+ (0.02,0) [0|0] "" Vector__XXX
 SG_ BMS_idealEnergyRemaining m0 : 48|16@1+ (0.02,0) [0|0] "" Vector__XXX
 SG_ BMS_userFacingSoe m2 : 52|11@1+ (0.05,0) [0|0] "" Vector__XXX

BO_ 851 UI_status: 8 Vector__XXX
 SG_ UI_touchActive : 0|1@1+ (1,0) [0|0] "" Vector__XXX
 SG_ UI_audioActive : 1|1@1+ (1,0) [0|0] "" Vector__XXX
 SG_ UI_bluetoothActive : 2|1@1+ (1,0) [0|0] "" Vector__XXX
 SG_ UI_cellActive : 3|1@1+ (1,0) [0|0] "" Vector__XXX
 SG_ UI_displayReady : 4|1@1+ (1,0) [0|0] "" Vector__XXX
 SG_ UI_displayOn : 5|1@1+ (1,0) [0|0] "" Vector__XXX
 SG_ UI_wifiActive : 6|1@1+ (1,0) [0|0] "" Vector__XXX
 SG_ UI_wifiConnected : 7|1@1+ (1,0) [0|0] "" Vector__XXX
 SG_ UI_systemActive : 8|1@1+ (1,0) [0|0] "" Vector__XXX
 SG_ UI_readyForDrive : 9|1@1+ (1,0) [0|0] "" Vector__XXX
 SG_ UI_cellConnected : 10|1@1+ (1,0) [0|0] "" Vector__XXX
 SG_ UI_vpnActive : 11|1@1+ (1,0) [0|0] "" Vector__XXX
 SG_ UI_autopilotTrial : 12|2@1+ (1,0) [0|0] "" Vector__XXX
 SG_ UI_factoryReset : 14|2@1+ (1,0) [0|0] "" Vector__XXX
 SG_ UI_gpsActive : 16|1@1+ (1,0) [0|0] "" Vector__XXX
 SG_ UI_screenshotActive : 17|1@1+ (1,0) [0|0] "" Vector__XXX
 SG_ UI_radioActive : 18|1@1+ (1,0) [0|0] "" Vector__XXX
 SG_ UI_cellNetworkTechnology : 19|4@1+ (1,0) [0|0] "" Vector__XXX
 SG_ UI_cellReceiverPower : 24|8@1+ (1,-128) [0|0] "" Vector__XXX
 SG_ UI_falseTouchCounter : 32|8@1+ (1,0) [0|0] "" Vector__XXX
 SG_ UI_developmentCar : 40|1@1+ (1,0) [0|0] "" Vector__XXX
 SG_ UI_cameraActive : 41|1@1+ (1,0) [0|0] "" Vector__XXX
 SG_ UI_cellSignalBars : 42|3@1+ (1,0) [0|0] "" Vector__XXX
 SG_ UI_trailerModeTelltale : 45|2@1+ (1,0) [0|0] "" Vector__XXX
 SG_ UI_pcbTemperature : 48|8@1- (1,40) [0|0] "" Vector__XXX
 SG_ UI_cpuTemperature : 56|8@1- (1,40) [0|0] "" Vector__XXX

BO_ 853 UI_vehicleControlThermal: 8 Vector__XXX
 SG_ UI_coolantFlowRequest : 0|5@1+ (1,0) [0|0] "" Vector__XXX
 SG_ UI_inletActiveCoolTarget : 5|7@1+ (1,0) [0|0] "" Vector__XXX
 SG_ UI_disableHVPTThermalLoads : 12|1@1+ (1,0) [0|0] "" Vector__XXX
 SG_ UI_enableCompLiquidPumpOut : 13|1@1+ (1,0) [0|0] "" Vector__XXX
 SG_ UI_enableCOP1HighSHOperation : 14|1@1+ (1,0) [0|0] "" Vector__XXX
 SG_ UI_enableIncreasedEvapRampRate : 15|1@1+ (1,0) [0|0] "" Vector__XXX
 SG_ UI_enableCOP1BatteryHeating : 16|1@1+ (1,0) [0|0] "" Vector__XXX
 SG_ UI_enableCOP1CabinHeatingBatteryHeating : 17|1@1+ (1,0) [0|0] "" Vector__XXX
 SG_ UI_enableLouverAutoDetection : 18|1@1+ (1,0) [0|0] "" Vector__XXX
 SG_ UI_enableUserFacingLowFlowDeliveryAlert : 19|1@1+ (1,0) [0|0] "" Vector__XXX
 SG_ UI_disableHvacCameraOnlyDefog : 20|1@1+ (1,0) [0|0] "" Vector__XXX
 SG_ UI_enableEXVFastCalibration : 21|1@1+ (1,0) [0|0] "" Vector__XXX
 SG_ UI_enableThermalDriverlessSelfTest : 22|1@1+ (1,0) [0|0] "" Vector__XXX
 SG_ UI_enableCoolantDasTarget : 23|1@1+ (1,0) [0|0] "" Vector__XXX
 SG_ UI_geofencedLiftgateHeight : 24|8@1+ (1,0) [0|0] "" Vector__XXX
 SG_ UI_convenienceFeatureLimit : 32|7@1+ (1,0) [0|0] "" Vector__XXX
 SG_ UI_allowConvenienceFeatures : 39|1@1+ (1,0) [0|0] "" Vector__XXX
 SG_ UI_enableConservativeBatteryHeating : 40|1@1+ (1,0) [0|0] "" Vector__XXX
 SG_ UI_enableDefaultApTempTarget : 41|1@1+ (1,0) [0|0] "" Vector__XXX
 SG_ UI_enableHVACCompressorWasteHeat : 42|1@1+ (1,0) [0|0] "" Vector__XXX
 SG_ UI_disablePhoneChargingPads : 43|1@1+ (1,0) [0|0] "" Vector__XXX
 SG_ UI_isAtTeslaFacility : 45|1@1+ (1,0) [0|0] "" Vector__XXX
 SG_ UI_enableThermalPowerBudget : 46|1@1+ (1,0) [0|0] "" Vector__XXX
 SG_ UI_enableHVACAPFanHeaterControl : 48|1@1+ (1,0) [0|0] "" Vector__XXX
 SG_ UI_enableAutopilotAirPurge : 49|1@1+ (1,0) [0|0] "" Vector__XXX

BO_ 854 DIF_alertMatrix1: 8 Vector__XXX
 SG_ DIF_a001_hwPhaseAgateDrive : 0|1@1+ (1,0) [0|0] "" Vector__XXX
 SG_ DIF_a002_hwPhaseBgateDrive : 1|1@1+ (1,0) [0|0] "" Vector__XXX
 SG_ DIF_a003_hwPhaseCgateDrive : 2|1@1+ (1,0) [0|0] "" Vector__XXX
 SG_ DIF_a004_hwPhaseApeak : 3|1@1+ (1,0) [0|0] "" Vector__XXX
 SG_ DIF_a005_hwPhaseBpeak : 4|1@1+ (1,0) [0|0] "" Vector__XXX
 SG_ DIF_a006_hwPhaseCpeak : 5|1@1+ (1,0) [0|0] "" Vector__XXX
 SG_ DIF_a007_statorAnomalyDetected : 6|1@1+ (1,0) [0|0] "" Vector__XXX
 SG_ DIF_a008_hwEncoderA : 7|1@1+ (1,0) [0|0] "" Vector__XXX
 SG_ DIF_a009_hwEncoderB : 8|1@1+ (1,0) [0|0] "" Vector__XXX
 SG_ DIF_a010_unintendedReset : 9|1@1+ (1,0) [0|0] "" Vector__XXX
 SG_ DIF_a011_swPowerStageNotReady : 10|1@1+ (1,0) [0|0] "" Vector__XXX
 SG_ DIF_a013_eccError : 12|1@1+ (1,0) [0|0] "" Vector__XXX
 SG_ DIF_a014_activeDamping : 13|1@1+ (1,0) [0|0] "" Vector__XXX
 SG_ DIF_a015_mechSafeStateAnomaly : 14|1@1+ (1,0) [0|0] "" Vector__XXX
 SG_ DIF_a016_safeStateApplied : 15|1@1+ (1,0) [0|0] "" Vector__XXX
 SG_ DIF_a017_hwPedalMonitor : 16|1@1+ (1,0) [0|0] "" Vector__XXX
 SG_ DIF_a018_hwLVSupplyUV : 17|1@1+ (1,0) [0|0] "" Vector__XXX
 SG_ DIF_a020_hwMotorEncoder : 19|1@1+ (1,0) [0|0] "" Vector__XXX
 SG_ DIF_a021_hwBusOV : 20|1@1+ (1,0) [0|0] "" Vector__XXX
 SG_ DIF_a022_hw5vSupplyUV : 21|1@1+ (1,0) [0|0] "" Vector__XXX
 SG_ DIF_a024_selfTest : 23|1@1+ (1,0) [0|0] "" Vector__XXX
 SG_ DIF_a025_phaseApeak : 24|1@1+ (1,0) [0|0] "" Vector__XXX
 SG_ DIF_a026_phaseBpeak : 25|1@1+ (1,0) [0|0] "" Vector__XXX
 SG_ DIF_a027_phaseCpeak : 26|1@1+ (1,0) [0|0] "" Vector__XXX
 SG_ DIF_a028_phaseArms : 27|1@1+ (1,0) [0|0] "" Vector__XXX
 SG_ DIF_a029_phaseBrms : 28|1@1+ (1,0) [0|0] "" Vector__XXX
 SG_ DIF_a030_phaseCrms : 29|1@1+ (1,0) [0|0] "" Vector__XXX
 SG_ DIF_a031_phaseAcurrentOffset : 30|1@1+ (1,0) [0|0] "" Vector__XXX
 SG_ DIF_a032_phaseBcurrentOffset : 31|1@1+ (1,0) [0|0] "" Vector__XXX
 SG_ DIF_a033_phaseAcurrentSensor : 32|1@1+ (1,0) [0|0] "" Vector__XXX
 SG_ DIF_a034_phaseBcurrentSensor : 33|1@1+ (1,0) [0|0] "" Vector__XXX
 SG_ DIF_a035_phaseCurrentBalance : 34|1@1+ (1,0) [0|0] "" Vector__XXX
 SG_ DIF_a036_busOV : 35|1@1+ (1,0) [0|0] "" Vector__XXX
 SG_ DIF_a037_busUV : 36|1@1+ (1,0) [0|0] "" Vector__XXX
 SG_ DIF_a038_busVsensor : 37|1@1+ (1,0) [0|0] "" Vector__XXX
 SG_ DIF_a040_difMIA : 39|1@1+ (1,0) [0|0] "" Vector__XXX
 SG_ DIF_a041_sdcMIA : 40|1@1+ (1,0) [0|0] "" Vector__XXX
 SG_ DIF_a042_inletSensor : 41|1@1+ (1,0) [0|0] "" Vector__XXX
 SG_ DIF_a043_outletOT : 42|1@1+ (1,0) [0|0] "" Vector__XXX
 SG_ DIF_a044_outletUT : 43|1@1+ (1,0) [0|0] "" Vector__XXX
 SG_ DIF_a045_outletSensor : 44|1@1+ (1,0) [0|0] "" Vector__XXX
 SG_ DIF_a046_statorOT : 45|1@1+ (1,0) [0|0] "" Vector__XXX
 SG_ DIF_a047_statorSensor1 : 46|1@1+ (1,0) [0|0] "" Vector__XXX
 SG_ DIF_a048_statorSensor2 : 47|1@1+ (1,0) [0|0] "" Vector__XXX
 SG_ DIF_a049_statorSensorDiff : 48|1@1+ (1,0) [0|0] "" Vector__XXX
 SG_ DIF_a050_noStatorSensor : 49|1@1+ (1,0) [0|0] "" Vector__XXX
 SG_ DIF_a052_dirMIA : 51|1@1+ (1,0) [0|0] "" Vector__XXX
 SG_ DIF_a053_unexpectedLatchState : 52|1@1+ (1,0) [0|0] "" Vector__XXX
 SG_ DIF_a054_driveInverterOT : 53|1@1+ (1,0) [0|0] "" Vector__XXX
 SG_ DIF_a055_trqCrossCheck : 54|1@1+ (1,0) [0|0] "" Vector__XXX
 SG_ DIF_a056_ambientOT : 55|1@1+ (1,0) [0|0] "" Vector__XXX
 SG_ DIF_a057_ambientUT : 56|1@1+ (1,0) [0|0] "" Vector__XXX
 SG_ DIF_a058_ambientSensor : 57|1@1+ (1,0) [0|0] "" Vector__XXX
 SG_ DIF_a059_heatsinkOT : 58|1@1+ (1,0) [0|0] "" Vector__XXX
 SG_ DIF_a060_heatsinkUT : 59|1@1+ (1,0) [0|0] "" Vector__XXX
 SG_ DIF_a061_heatsinkSensor : 60|1@1+ (1,0) [0|0] "" Vector__XXX
 SG_ DIF_a062_systemLimpMode : 61|1@1+ (1,0) [0|0] "" Vector__XXX
 SG_ DIF_a064_torqueIntervention : 63|1@1+ (1,0) [0|0] "" Vector__XXX

BO_ 855 DIF_alertMatrix2: 8 Vector__XXX
 SG_ DIF_a065_canHardwareBusB : 0|1@1+ (1,0) [0|0] "" Vector__XXX
 SG_ DIF_a066_canDataBusB : 1|1@1+ (1,0) [0|0] "" Vector__XXX
 SG_ DIF_a067_canOverrunBusB : 2|1@1+ (1,0) [0|0] "" Vector__XXX
 SG_ DIF_a069_rotorTempLimit : 4|1@1+ (1,0) [0|0] "" Vector__XXX
 SG_ DIF_a070_udsTransactionInitiated : 5|1@1+ (1,0) [0|0] "" Vector__XXX
 SG_ DIF_a071_busDisconnected : 6|1@1+ (1,0) [0|0] "" Vector__XXX
 SG_ DIF_a072_gateDriveFaultCounter : 7|1@1+ (1,0) [0|0] "" Vector__XXX
 SG_ DIF_a073_motorSpeed : 8|1@1+ (1,0) [0|0] "" Vector__XXX
 SG_ DIF_a074_motorEncoder : 9|1@1+ (1,0) [0|0] "" Vector__XXX
 SG_ DIF_a075_motorSpeedMismatch : 10|1@1+ (1,0) [0|0] "" Vector__XXX
 SG_ DIF_a076_lvSupplyOV : 11|1@1+ (1,0) [0|0] "" Vector__XXX
 SG_ DIF_a077_lvSupplyUV : 12|1@1+ (1,0) [0|0] "" Vector__XXX
 SG_ DIF_a078_adcRefLow : 13|1@1+ (1,0) [0|0] "" Vector__XXX
 SG_ DIF_a079_adcRefHigh : 14|1@1+ (1,0) [0|0] "" Vector__XXX
 SG_ DIF_a084_eccTestData0 : 19|1@1+ (1,0) [0|0] "" Vector__XXX
 SG_ DIF_a086_activeDischargeOn : 21|1@1+ (1,0) [0|0] "" Vector__XXX
 SG_ DIF_a087_gtwMIA : 22|1@1+ (1,0) [0|0] "" Vector__XXX
 SG_ DIF_a088_uiMIA : 23|1@1+ (1,0) [0|0] "" Vector__XXX
 SG_ DIF_a090_pmMIA : 25|1@1+ (1,0) [0|0] "" Vector__XXX
 SG_ DIF_a091_espMIA : 26|1@1+ (1,0) [0|0] "" Vector__XXX
 SG_ DIF_a092_bmsMIA : 27|1@1+ (1,0) [0|0] "" Vector__XXX
 SG_ DIF_a093_canHardwareBusA : 28|1@1+ (1,0) [0|0] "" Vector__XXX
 SG_ DIF_a094_canDataBusA : 29|1@1+ (1,0) [0|0] "" Vector__XXX
 SG_ DIF_a095_canOverrunBusA : 30|1@1+ (1,0) [0|0] "" Vector__XXX
 SG_ DIF_a096_memoryError : 31|1@1+ (1,0) [0|0] "" Vector__XXX
 SG_ DIF_a097_eepromError : 32|1@1+ (1,0) [0|0] "" Vector__XXX
 SG_ DIF_a098_intTimeTooLong : 33|1@1+ (1,0) [0|0] "" Vector__XXX
 SG_ DIF_a099_threadOverrun : 34|1@1+ (1,0) [0|0] "" Vector__XXX
 SG_ DIF_a100_assertion : 35|1@1+ (1,0) [0|0] "" Vector__XXX
 SG_ DIF_a101_eccTestData1 : 36|1@1+ (1,0) [0|0] "" Vector__XXX
 SG_ DIF_a103_lowFlow : 38|1@1+ (1,0) [0|0] "" Vector__XXX
 SG_ DIF_a107_fpgaError : 42|1@1+ (1,0) [0|0] "" Vector__XXX
 SG_ DIF_a108_stateTrans : 43|1@1+ (1,0) [0|0] "" Vector__XXX
 SG_ DIF_a110_brakeMIA : 45|1@1+ (1,0) [0|0] "" Vector__XXX
 SG_ DIF_a111_badPhaseSensorCalib : 46|1@1+ (1,0) [0|0] "" Vector__XXX
 SG_ DIF_a112_noPhaseCurrent : 47|1@1+ (1,0) [0|0] "" Vector__XXX
 SG_ DIF_a113_noFuncHeatsinkSensor : 48|1@1+ (1,0) [0|0] "" Vector__XXX
 SG_ DIF_a117_diMIA : 52|1@1+ (1,0) [0|0] "" Vector__XXX
 SG_ DIF_a119_hvpMIA : 54|1@1+ (1,0) [0|0] "" Vector__XXX
 SG_ DIF_a120_hvlinkMIA : 55|1@1+ (1,0) [0|0] "" Vector__XXX
 SG_ DIF_a121_motorControlRegulation : 56|1@1+ (1,0) [0|0] "" Vector__XXX
 SG_ DIF_a122_highStackUsage : 57|1@1+ (1,0) [0|0] "" Vector__XXX
 SG_ DIF_a123_lossMotorControl : 58|1@1+ (1,0) [0|0] "" Vector__XXX
 SG_ DIF_a126_limpMode : 61|1@1+ (1,0) [0|0] "" Vector__XXX
 SG_ DIF_a127_gracefulPowerOff : 62|1@1+ (1,0) [0|0] "" Vector__XXX
 SG_ DIF_a128_fpgaVersionMismatch : 63|1@1+ (1,0) [0|0] "" Vector__XXX

BO_ 857 VCSEC_DeviceStatus: 8 Vector__XXX
 SG_ VCSEC_DeviceStatusIndex M : 0|7@1+ (1,0) [0|0] "" Vector__XXX
 SG_ VCSEC_Device0AuthResponseTime m0 : 7|7@1+ (50,0) [0|0] "" Vector__XXX
 SG_ VCSEC_Device0AwakeTime m1 : 7|27@1+ (1,0) [0|0] "" Vector__XXX
 SG_ VCSEC_Device10AuthResponseTime m60 : 7|7@1+ (50,0) [0|0] "" Vector__XXX
 SG_ VCSEC_Device10AwakeTime m61 : 7|27@1+ (1,0) [0|0] "" Vector__XXX
 SG_ VCSEC_Device11AuthResponseTime m66 : 7|7@1+ (50,0) [0|0] "" Vector__XXX
 SG_ VCSEC_Device11AwakeTime m67 : 7|27@1+ (1,0) [0|0] "" Vector__XXX
 SG_ VCSEC_Device12AuthResponseTime m72 : 7|7@1+ (50,0) [0|0] "" Vector__XXX
 SG_ VCSEC_Device12AwakeTime m73 : 7|27@1+ (1,0) [0|0] "" Vector__XXX
 SG_ VCSEC_Device13AuthResponseTime m78 : 7|7@1+ (50,0) [0|0] "" Vector__XXX
 SG_ VCSEC_Device13AwakeTime m79 : 7|27@1+ (1,0) [0|0] "" Vector__XXX
 SG_ VCSEC_Device14AuthResponseTime m84 : 7|7@1+ (50,0) [0|0] "" Vector__XXX
 SG_ VCSEC_Device14AwakeTime m85 : 7|27@1+ (1,0) [0|0] "" Vector__XXX
 SG_ VCSEC_Device15AuthResponseTime m90 : 7|7@1+ (50,0) [0|0] "" Vector__XXX
 SG_ VCSEC_Device15AwakeTime m91 : 7|27@1+ (1,0) [0|0] "" Vector__XXX
 SG_ VCSEC_Device16AuthResponseTime m96 : 7|7@1+ (50,0) [0|0] "" Vector__XXX
 SG_ VCSEC_Device16AwakeTime m97 : 7|27@1+ (1,0) [0|0] "" Vector__XXX
 SG_ VCSEC_Device17AuthResponseTime m102 : 7|7@1+ (50,0) [0|0] "" Vector__XXX
 SG_ VCSEC_Device17AwakeTime m103 : 7|27@1+ (1,0) [0|0] "" Vector__XXX
 SG_ VCSEC_Device18AuthResponseTime m108 : 7|7@1+ (50,0) [0|0] "" Vector__XXX
 SG_ VCSEC_Device18AwakeTime m109 : 7|27@1+ (1,0) [0|0] "" Vector__XXX
 SG_ VCSEC_Device19AuthResponseTime m114 : 7|7@1+ (50,0) [0|0] "" Vector__XXX
 SG_ VCSEC_Device19AwakeTime m115 : 7|27@1+ (1,0) [0|0] "" Vector__XXX
 SG_ VCSEC_Device1AuthResponseTime m6 : 7|7@1+ (50,0) [0|0] "" Vector__XXX
 SG_ VCSEC_Device1AwakeTime m7 : 7|27@1+ (1,0) [0|0] "" Vector__XXX
 SG_ VCSEC_Device2AuthResponseTime m12 : 7|7@1+ (50,0) [0|0] "" Vector__XXX
 SG_ VCSEC_Device2AwakeTime m13 : 7|27@1+ (1,0) [0|0] "" Vector__XXX
 SG_ VCSEC_Device3AuthResponseTime m18 : 7|7@1+ (50,0) [0|0] "" Vector__XXX
 SG_ VCSEC_Device3AwakeTime m19 : 7|27@1+ (1,0) [0|0] "" Vector__XXX
 SG_ VCSEC_Device4AuthResponseTime m24 : 7|7@1+ (50,0) [0|0] "" Vector__XXX
 SG_ VCSEC_Device4AwakeTime m25 : 7|27@1+ (1,0) [0|0] "" Vector__XXX
 SG_ VCSEC_Device5AuthResponseTime m30 : 7|7@1+ (50,0) [0|0] "" Vector__XXX
 SG_ VCSEC_Device5AwakeTime m31 : 7|27@1+ (1,0) [0|0] "" Vector__XXX
 SG_ VCSEC_Device6AuthResponseTime m36 : 7|7@1+ (50,0) [0|0] "" Vector__XXX
 SG_ VCSEC_Device6AwakeTime m37 : 7|27@1+ (1,0) [0|0] "" Vector__XXX
 SG_ VCSEC_Device7AuthResponseTime m42 : 7|7@1+ (50,0) [0|0] "" Vector__XXX
 SG_ VCSEC_Device7AwakeTime m43 : 7|27@1+ (1,0) [0|0] "" Vector__XXX
 SG_ VCSEC_Device8AuthResponseTime m48 : 7|7@1+ (50,0) [0|0] "" Vector__XXX
 SG_ VCSEC_Device8AwakeTime m49 : 7|27@1+ (1,0) [0|0] "" Vector__XXX
 SG_ VCSEC_Device9AuthResponseTime m54 : 7|7@1+ (50,0) [0|0] "" Vector__XXX
 SG_ VCSEC_Device9AwakeTime m55 : 7|27@1+ (1,0) [0|0] "" Vector__XXX
 SG_ VCSEC_Device0Bonded m2 : 8|1@1+ (1,0) [0|0] "" Vector__XXX
 SG_ VCSEC_Device0ManufacturerHashBits m5 : 8|24@1+ (1,0) [0|0] "" Vector__XXX
 SG_ VCSEC_Device0ModelHash m4 : 8|56@1+ (1,0) [0|0] "" Vector__XXX
 SG_ VCSEC_Device10Bonded m62 : 8|1@1+ (1,0) [0|0] "" Vector__XXX
 SG_ VCSEC_Device10ManufacturerHashBits m65 : 8|24@1+ (1,0) [0|0] "" Vector__XXX
 SG_ VCSEC_Device10ModelHash m64 : 8|56@1+ (1,0) [0|0] "" Vector__XXX
 SG_ VCSEC_Device11Bonded m68 : 8|1@1+ (1,0) [0|0] "" Vector__XXX
 SG_ VCSEC_Device11ManufacturerHashBits m71 : 8|24@1+ (1,0) [0|0] "" Vector__XXX
 SG_ VCSEC_Device11ModelHash m70 : 8|56@1+ (1,0) [0|0] "" Vector__XXX
 SG_ VCSEC_Device12Bonded m74 : 8|1@1+ (1,0) [0|0] "" Vector__XXX
 SG_ VCSEC_Device12ManufacturerHashBits m77 : 8|24@1+ (1,0) [0|0] "" Vector__XXX
 SG_ VCSEC_Device12ModelHash m76 : 8|56@1+ (1,0) [0|0] "" Vector__XXX
 SG_ VCSEC_Device13Bonded m80 : 8|1@1+ (1,0) [0|0] "" Vector__XXX
 SG_ VCSEC_Device13ManufacturerHashBits m83 : 8|24@1+ (1,0) [0|0] "" Vector__XXX
 SG_ VCSEC_Device13ModelHash m82 : 8|56@1+ (1,0) [0|0] "" Vector__XXX
 SG_ VCSEC_Device14Bonded m86 : 8|1@1+ (1,0) [0|0] "" Vector__XXX
 SG_ VCSEC_Device14ManufacturerHashBits m89 : 8|24@1+ (1,0) [0|0] "" Vector__XXX
 SG_ VCSEC_Device14ModelHash m88 : 8|56@1+ (1,0) [0|0] "" Vector__XXX
 SG_ VCSEC_Device15Bonded m92 : 8|1@1+ (1,0) [0|0] "" Vector__XXX
 SG_ VCSEC_Device15ManufacturerHashBits m95 : 8|24@1+ (1,0) [0|0] "" Vector__XXX
 SG_ VCSEC_Device15ModelHash m94 : 8|56@1+ (1,0) [0|0] "" Vector__XXX
 SG_ VCSEC_Device16Bonded m98 : 8|1@1+ (1,0) [0|0] "" Vector__XXX
 SG_ VCSEC_Device16ManufacturerHashBits m101 : 8|24@1+ (1,0) [0|0] "" Vector__XXX
 SG_ VCSEC_Device16ModelHash m100 : 8|56@1+ (1,0) [0|0] "" Vector__XXX
 SG_ VCSEC_Device17Bonded m104 : 8|1@1+ (1,0) [0|0] "" Vector__XXX
 SG_ VCSEC_Device17ManufacturerHashBits m107 : 8|24@1+ (1,0) [0|0] "" Vector__XXX
 SG_ VCSEC_Device17ModelHash m106 : 8|56@1+ (1,0) [0|0] "" Vector__XXX
 SG_ VCSEC_Device18Bonded m110 : 8|1@1+ (1,0) [0|0] "" Vector__XXX
 SG_ VCSEC_Device18ManufacturerHashBits m113 : 8|24@1+ (1,0) [0|0] "" Vector__XXX
 SG_ VCSEC_Device18ModelHash m112 : 8|56@1+ (1,0) [0|0] "" Vector__XXX
 SG_ VCSEC_Device19Bonded m116 : 8|1@1+ (1,0) [0|0] "" Vector__XXX
 SG_ VCSEC_Device19ManufacturerHashBits m119 : 8|24@1+ (1,0) [0|0] "" Vector__XXX
 SG_ VCSEC_Device19ModelHash m118 : 8|56@1+ (1,0) [0|0] "" Vector__XXX
 SG_ VCSEC_Device1Bonded m8 : 8|1@1+ (1,0) [0|0] "" Vector__XXX
 SG_ VCSEC_Device1ManufacturerHashBits m11 : 8|24@1+ (1,0) [0|0] "" Vector__XXX
 SG_ VCSEC_Device1ModelHash m10 : 8|56@1+ (1,0) [0|0] "" Vector__XXX
 SG_ VCSEC_Device2Bonded m14 : 8|1@1+ (1,0) [0|0] "" Vector__XXX
 SG_ VCSEC_Device2ManufacturerHashBits m17 : 8|24@1+ (1,0) [0|0] "" Vector__XXX
 SG_ VCSEC_Device2ModelHash m16 : 8|56@1+ (1,0) [0|0] "" Vector__XXX
 SG_ VCSEC_Device3Bonded m20 : 8|1@1+ (1,0) [0|0] "" Vector__XXX
 SG_ VCSEC_Device3ManufacturerHashBits m23 : 8|24@1+ (1,0) [0|0] "" Vector__XXX
 SG_ VCSEC_Device3ModelHash m22 : 8|56@1+ (1,0) [0|0] "" Vector__XXX
 SG_ VCSEC_Device4Bonded m26 : 8|1@1+ (1,0) [0|0] "" Vector__XXX
 SG_ VCSEC_Device4ManufacturerHashBits m29 : 8|24@1+ (1,0) [0|0] "" Vector__XXX
 SG_ VCSEC_Device4ModelHash m28 : 8|56@1+ (1,0) [0|0] "" Vector__XXX
 SG_ VCSEC_Device5Bonded m32 : 8|1@1+ (1,0) [0|0] "" Vector__XXX
 SG_ VCSEC_Device5ManufacturerHashBits m35 : 8|24@1+ (1,0) [0|0] "" Vector__XXX
 SG_ VCSEC_Device5ModelHash m34 : 8|56@1+ (1,0) [0|0] "" Vector__XXX
 SG_ VCSEC_Device6Bonded m38 : 8|1@1+ (1,0) [0|0] "" Vector__XXX
 SG_ VCSEC_Device6ManufacturerHashBits m41 : 8|24@1+ (1,0) [0|0] "" Vector__XXX
 SG_ VCSEC_Device6ModelHash m40 : 8|56@1+ (1,0) [0|0] "" Vector__XXX
 SG_ VCSEC_Device7Bonded m44 : 8|1@1+ (1,0) [0|0] "" Vector__XXX
 SG_ VCSEC_Device7ManufacturerHashBits m47 : 8|24@1+ (1,0) [0|0] "" Vector__XXX
 SG_ VCSEC_Device7ModelHash m46 : 8|56@1+ (1,0) [0|0] "" Vector__XXX
 SG_ VCSEC_Device8Bonded m50 : 8|1@1+ (1,0) [0|0] "" Vector__XXX
 SG_ VCSEC_Device8ManufacturerHashBits m53 : 8|24@1+ (1,0) [0|0] "" Vector__XXX
 SG_ VCSEC_Device8ModelHash m52 : 8|56@1+ (1,0) [0|0] "" Vector__XXX
 SG_ VCSEC_Device9Bonded m56 : 8|1@1+ (1,0) [0|0] "" Vector__XXX
 SG_ VCSEC_Device9ManufacturerHashBits m59 : 8|24@1+ (1,0) [0|0] "" Vector__XXX
 SG_ VCSEC_Device9ModelHash m58 : 8|56@1+ (1,0) [0|0] "" Vector__XXX
 SG_ VCSEC_Device0Role m2 : 9|4@1+ (1,0) [0|0] "" Vector__XXX
 SG_ VCSEC_Device10Role m62 : 9|4@1+ (1,0) [0|0] "" Vector__XXX
 SG_ VCSEC_Device11Role m68 : 9|4@1+ (1,0) [0|0] "" Vector__XXX
 SG_ VCSEC_Device12Role m74 : 9|4@1+ (1,0) [0|0] "" Vector__XXX
 SG_ VCSEC_Device13Role m80 : 9|4@1+ (1,0) [0|0] "" Vector__XXX
 SG_ VCSEC_Device14Role m86 : 9|4@1+ (1,0) [0|0] "" Vector__XXX
 SG_ VCSEC_Device15Role m92 : 9|4@1+ (1,0) [0|0] "" Vector__XXX
 SG_ VCSEC_Device16Role m98 : 9|4@1+ (1,0) [0|0] "" Vector__XXX
 SG_ VCSEC_Device17Role m104 : 9|4@1+ (1,0) [0|0] "" Vector__XXX
 SG_ VCSEC_Device18Role m110 : 9|4@1+ (1,0) [0|0] "" Vector__XXX
 SG_ VCSEC_Device19Role m116 : 9|4@1+ (1,0) [0|0] "" Vector__XXX
 SG_ VCSEC_Device1Role m8 : 9|4@1+ (1,0) [0|0] "" Vector__XXX
 SG_ VCSEC_Device2Role m14 : 9|4@1+ (1,0) [0|0] "" Vector__XXX
 SG_ VCSEC_Device3Role m20 : 9|4@1+ (1,0) [0|0] "" Vector__XXX
 SG_ VCSEC_Device4Role m26 : 9|4@1+ (1,0) [0|0] "" Vector__XXX
 SG_ VCSEC_Device5Role m32 : 9|4@1+ (1,0) [0|0] "" Vector__XXX
 SG_ VCSEC_Device6Role m38 : 9|4@1+ (1,0) [0|0] "" Vector__XXX
 SG_ VCSEC_Device7Role m44 : 9|4@1+ (1,0) [0|0] "" Vector__XXX
 SG_ VCSEC_Device8Role m50 : 9|4@1+ (1,0) [0|0] "" Vector__XXX
 SG_ VCSEC_Device9Role m56 : 9|4@1+ (1,0) [0|0] "" Vector__XXX
 SG_ VCSEC_Device0Impermanent m0 : 14|1@1+ (1,0) [0|0] "" Vector__XXX
 SG_ VCSEC_Device10Impermanent m60 : 14|1@1+ (1,0) [0|0] "" Vector__XXX
 SG_ VCSEC_Device11Impermanent m66 : 14|1@1+ (1,0) [0|0] "" Vector__XXX
 SG_ VCSEC_Device12Impermanent m72 : 14|1@1+ (1,0) [0|0] "" Vector__XXX
 SG_ VCSEC_Device13Impermanent m78 : 14|1@1+ (1,0) [0|0] "" Vector__XXX
 SG_ VCSEC_Device14Impermanent m84 : 14|1@1+ (1,0) [0|0] "" Vector__XXX
 SG_ VCSEC_Device15Impermanent m90 : 14|1@1+ (1,0) [0|0] "" Vector__XXX
 SG_ VCSEC_Device16Impermanent m96 : 14|1@1+ (1,0) [0|0] "" Vector__XXX
 SG_ VCSEC_Device17Impermanent m102 : 14|1@1+ (1,0) [0|0] "" Vector__XXX
 SG_ VCSEC_Device18Impermanent m108 : 14|1@1+ (1,0) [0|0] "" Vector__XXX
 SG_ VCSEC_Device19Impermanent m114 : 14|1@1+ (1,0) [0|0] "" Vector__XXX
 SG_ VCSEC_Device1Impermanent m6 : 14|1@1+ (1,0) [0|0] "" Vector__XXX
 SG_ VCSEC_Device2Impermanent m12 : 14|1@1+ (1,0) [0|0] "" Vector__XXX
 SG_ VCSEC_Device3Impermanent m18 : 14|1@1+ (1,0) [0|0] "" Vector__XXX
 SG_ VCSEC_Device4Impermanent m24 : 14|1@1+ (1,0) [0|0] "" Vector__XXX
 SG_ VCSEC_Device5Impermanent m30 : 14|1@1+ (1,0) [0|0] "" Vector__XXX
 SG_ VCSEC_Device6Impermanent m36 : 14|1@1+ (1,0) [0|0] "" Vector__XXX
 SG_ VCSEC_Device7Impermanent m42 : 14|1@1+ (1,0) [0|0] "" Vector__XXX
 SG_ VCSEC_Device8Impermanent m48 : 14|1@1+ (1,0) [0|0] "" Vector__XXX
 SG_ VCSEC_Device9Impermanent m54 : 14|1@1+ (1,0) [0|0] "" Vector__XXX
 SG_ VCSEC_Device0SELockedDown m0 : 15|1@1+ (1,0) [0|0] "" Vector__XXX
 SG_ VCSEC_Device10SELockedDown m60 : 15|1@1+ (1,0) [0|0] "" Vector__XXX
 SG_ VCSEC_Device11SELockedDown m66 : 15|1@1+ (1,0) [0|0] "" Vector__XXX
 SG_ VCSEC_Device12SELockedDown m72 : 15|1@1+ (1,0) [0|0] "" Vector__XXX
 SG_ VCSEC_Device13SELockedDown m78 : 15|1@1+ (1,0) [0|0] "" Vector__XXX
 SG_ VCSEC_Device14SELockedDown m84 : 15|1@1+ (1,0) [0|0] "" Vector__XXX
 SG_ VCSEC_Device15SELockedDown m90 : 15|1@1+ (1,0) [0|0] "" Vector__XXX
 SG_ VCSEC_Device16SELockedDown m96 : 15|1@1+ (1,0) [0|0] "" Vector__XXX
 SG_ VCSEC_Device17SELockedDown m102 : 15|1@1+ (1,0) [0|0] "" Vector__XXX
 SG_ VCSEC_Device18SELockedDown m108 : 15|1@1+ (1,0) [0|0] "" Vector__XXX
 SG_ VCSEC_Device19SELockedDown m114 : 15|1@1+ (1,0) [0|0] "" Vector__XXX
 SG_ VCSEC_Device1SELockedDown m6 : 15|1@1+ (1,0) [0|0] "" Vector__XXX
 SG_ VCSEC_Device2SELockedDown m12 : 15|1@1+ (1,0) [0|0] "" Vector__XXX
 SG_ VCSEC_Device3SELockedDown m18 : 15|1@1+ (1,0) [0|0] "" Vector__XXX
 SG_ VCSEC_Device4SELockedDown m24 : 15|1@1+ (1,0) [0|0] "" Vector__XXX
 SG_ VCSEC_Device5SELockedDown m30 : 15|1@1+ (1,0) [0|0] "" Vector__XXX
 SG_ VCSEC_Device6SELockedDown m36 : 15|1@1+ (1,0) [0|0] "" Vector__XXX
 SG_ VCSEC_Device7SELockedDown m42 : 15|1@1+ (1,0) [0|0] "" Vector__XXX
 SG_ VCSEC_Device8SELockedDown m48 : 15|1@1+ (1,0) [0|0] "" Vector__XXX
 SG_ VCSEC_Device9SELockedDown m54 : 15|1@1+ (1,0) [0|0] "" Vector__XXX
 SG_ VCSEC_Device0Version m0 : 16|16@1+ (1,0) [0|0] "" Vector__XXX
 SG_ VCSEC_Device0WhitelistActiveTime m2 : 16|16@1+ (1,0) [0|0] "" Vector__XXX
 SG_ VCSEC_Device10Version m60 : 16|16@1+ (1,0) [0|0] "" Vector__XXX
 SG_ VCSEC_Device10WhitelistActiveTime m62 : 16|16@1+ (1,0) [0|0] "" Vector__XXX
 SG_ VCSEC_Device11Version m66 : 16|16@1+ (1,0) [0|0] "" Vector__XXX
 SG_ VCSEC_Device11WhitelistActiveTime m68 : 16|16@1+ (1,0) [0|0] "" Vector__XXX
 SG_ VCSEC_Device12Version m72 : 16|16@1+ (1,0) [0|0] "" Vector__XXX
 SG_ VCSEC_Device12WhitelistActiveTime m74 : 16|16@1+ (1,0) [0|0] "" Vector__XXX
 SG_ VCSEC_Device13Version m78 : 16|16@1+ (1,0) [0|0] "" Vector__XXX
 SG_ VCSEC_Device13WhitelistActiveTime m80 : 16|16@1+ (1,0) [0|0] "" Vector__XXX
 SG_ VCSEC_Device14Version m84 : 16|16@1+ (1,0) [0|0] "" Vector__XXX
 SG_ VCSEC_Device14WhitelistActiveTime m86 : 16|16@1+ (1,0) [0|0] "" Vector__XXX
 SG_ VCSEC_Device15Version m90 : 16|16@1+ (1,0) [0|0] "" Vector__XXX
 SG_ VCSEC_Device15WhitelistActiveTime m92 : 16|16@1+ (1,0) [0|0] "" Vector__XXX
 SG_ VCSEC_Device16Version m96 : 16|16@1+ (1,0) [0|0] "" Vector__XXX
 SG_ VCSEC_Device16WhitelistActiveTime m98 : 16|16@1+ (1,0) [0|0] "" Vector__XXX
 SG_ VCSEC_Device17Version m102 : 16|16@1+ (1,0) [0|0] "" Vector__XXX
 SG_ VCSEC_Device17WhitelistActiveTime m104 : 16|16@1+ (1,0) [0|0] "" Vector__XXX
 SG_ VCSEC_Device18Version m108 : 16|16@1+ (1,0) [0|0] "" Vector__XXX
 SG_ VCSEC_Device18WhitelistActiveTime m110 : 16|16@1+ (1,0) [0|0] "" Vector__XXX
 SG_ VCSEC_Device19Version m114 : 16|16@1+ (1,0) [0|0] "" Vector__XXX
 SG_ VCSEC_Device19WhitelistActiveTime m116 : 16|16@1+ (1,0) [0|0] "" Vector__XXX
 SG_ VCSEC_Device1Version m6 : 16|16@1+ (1,0) [0|0] "" Vector__XXX
 SG_ VCSEC_Device1WhitelistActiveTime m8 : 16|16@1+ (1,0) [0|0] "" Vector__XXX
 SG_ VCSEC_Device2Version m12 : 16|16@1+ (1,0) [0|0] "" Vector__XXX
 SG_ VCSEC_Device2WhitelistActiveTime m14 : 16|16@1+ (1,0) [0|0] "" Vector__XXX
 SG_ VCSEC_Device3Version m18 : 16|16@1+ (1,0) [0|0] "" Vector__XXX
 SG_ VCSEC_Device3WhitelistActiveTime m20 : 16|16@1+ (1,0) [0|0] "" Vector__XXX
 SG_ VCSEC_Device4Version m24 : 16|16@1+ (1,0) [0|0] "" Vector__XXX
 SG_ VCSEC_Device4WhitelistActiveTime m26 : 16|16@1+ (1,0) [0|0] "" Vector__XXX
 SG_ VCSEC_Device5Version m30 : 16|16@1+ (1,0) [0|0] "" Vector__XXX
 SG_ VCSEC_Device5WhitelistActiveTime m32 : 16|16@1+ (1,0) [0|0] "" Vector__XXX
 SG_ VCSEC_Device6Version m36 : 16|16@1+ (1,0) [0|0] "" Vector__XXX
 SG_ VCSEC_Device6WhitelistActiveTime m38 : 16|16@1+ (1,0) [0|0] "" Vector__XXX
 SG_ VCSEC_Device7Version m42 : 16|16@1+ (1,0) [0|0] "" Vector__XXX
 SG_ VCSEC_Device7WhitelistActiveTime m44 : 16|16@1+ (1,0) [0|0] "" Vector__XXX
 SG_ VCSEC_Device8Version m48 : 16|16@1+ (1,0) [0|0] "" Vector__XXX
 SG_ VCSEC_Device8WhitelistActiveTime m50 : 16|16@1+ (1,0) [0|0] "" Vector__XXX
 SG_ VCSEC_Device9Version m54 : 16|16@1+ (1,0) [0|0] "" Vector__XXX
 SG_ VCSEC_Device9WhitelistActiveTime m56 : 16|16@1+ (1,0) [0|0] "" Vector__XXX
 SG_ VCSEC_Device0BuildNumberHashBits m5 : 32|32@1+ (1,0) [0|0] "" Vector__XXX
 SG_ VCSEC_Device0Permissions m3 : 32|32@1+ (1,0) [0|0] "" Vector__XXX
 SG_ VCSEC_Device0SHA1 m2 : 32|32@1+ (1,0) [0|0] "" Vector__XXX
 SG_ VCSEC_Device0WLEntry m0 : 32|5@1+ (1,0) [0|0] "" Vector__XXX
 SG_ VCSEC_Device10BuildNumberHashBits m65 : 32|32@1+ (1,0) [0|0] "" Vector__XXX
 SG_ VCSEC_Device10Permissions m63 : 32|32@1+ (1,0) [0|0] "" Vector__XXX
 SG_ VCSEC_Device10SHA1 m62 : 32|32@1+ (1,0) [0|0] "" Vector__XXX
 SG_ VCSEC_Device10WLEntry m60 : 32|5@1+ (1,0) [0|0] "" Vector__XXX
 SG_ VCSEC_Device11BuildNumberHashBits m71 : 32|32@1+ (1,0) [0|0] "" Vector__XXX
 SG_ VCSEC_Device11Permissions m69 : 32|32@1+ (1,0) [0|0] "" Vector__XXX
 SG_ VCSEC_Device11SHA1 m68 : 32|32@1+ (1,0) [0|0] "" Vector__XXX
 SG_ VCSEC_Device11WLEntry m66 : 32|5@1+ (1,0) [0|0] "" Vector__XXX
 SG_ VCSEC_Device12BuildNumberHashBits m77 : 32|32@1+ (1,0) [0|0] "" Vector__XXX
 SG_ VCSEC_Device12Permissions m75 : 32|32@1+ (1,0) [0|0] "" Vector__XXX
 SG_ VCSEC_Device12SHA1 m74 : 32|32@1+ (1,0) [0|0] "" Vector__XXX
 SG_ VCSEC_Device12WLEntry m72 : 32|5@1+ (1,0) [0|0] "" Vector__XXX
 SG_ VCSEC_Device13BuildNumberHashBits m83 : 32|32@1+ (1,0) [0|0] "" Vector__XXX
 SG_ VCSEC_Device13Permissions m81 : 32|32@1+ (1,0) [0|0] "" Vector__XXX
 SG_ VCSEC_Device13SHA1 m80 : 32|32@1+ (1,0) [0|0] "" Vector__XXX
 SG_ VCSEC_Device13WLEntry m78 : 32|5@1+ (1,0) [0|0] "" Vector__XXX
 SG_ VCSEC_Device14BuildNumberHashBits m89 : 32|32@1+ (1,0) [0|0] "" Vector__XXX
 SG_ VCSEC_Device14Permissions m87 : 32|32@1+ (1,0) [0|0] "" Vector__XXX
 SG_ VCSEC_Device14SHA1 m86 : 32|32@1+ (1,0) [0|0] "" Vector__XXX
 SG_ VCSEC_Device14WLEntry m84 : 32|5@1+ (1,0) [0|0] "" Vector__XXX
 SG_ VCSEC_Device15BuildNumberHashBits m95 : 32|32@1+ (1,0) [0|0] "" Vector__XXX
 SG_ VCSEC_Device15Permissions m93 : 32|32@1+ (1,0) [0|0] "" Vector__XXX
 SG_ VCSEC_Device15SHA1 m92 : 32|32@1+ (1,0) [0|0] "" Vector__XXX
 SG_ VCSEC_Device15WLEntry m90 : 32|5@1+ (1,0) [0|0] "" Vector__XXX
 SG_ VCSEC_Device16BuildNumberHashBits m101 : 32|32@1+ (1,0) [0|0] "" Vector__XXX
 SG_ VCSEC_Device16Permissions m99 : 32|32@1+ (1,0) [0|0] "" Vector__XXX
 SG_ VCSEC_Device16SHA1 m98 : 32|32@1+ (1,0) [0|0] "" Vector__XXX
 SG_ VCSEC_Device16WLEntry m96 : 32|5@1+ (1,0) [0|0] "" Vector__XXX
 SG_ VCSEC_Device17BuildNumberHashBits m107 : 32|32@1+ (1,0) [0|0] "" Vector__XXX
 SG_ VCSEC_Device17Permissions m105 : 32|32@1+ (1,0) [0|0] "" Vector__XXX
 SG_ VCSEC_Device17SHA1 m104 : 32|32@1+ (1,0) [0|0] "" Vector__XXX
 SG_ VCSEC_Device17WLEntry m102 : 32|5@1+ (1,0) [0|0] "" Vector__XXX
 SG_ VCSEC_Device18BuildNumberHashBits m113 : 32|32@1+ (1,0) [0|0] "" Vector__XXX
 SG_ VCSEC_Device18Permissions m111 : 32|32@1+ (1,0) [0|0] "" Vector__XXX
 SG_ VCSEC_Device18SHA1 m110 : 32|32@1+ (1,0) [0|0] "" Vector__XXX
 SG_ VCSEC_Device18WLEntry m108 : 32|5@1+ (1,0) [0|0] "" Vector__XXX
 SG_ VCSEC_Device19BuildNumberHashBits m119 : 32|32@1+ (1,0) [0|0] "" Vector__XXX
 SG_ VCSEC_Device19Permissions m117 : 32|32@1+ (1,0) [0|0] "" Vector__XXX
 SG_ VCSEC_Device19SHA1 m116 : 32|32@1+ (1,0) [0|0] "" Vector__XXX
 SG_ VCSEC_Device19WLEntry m114 : 32|5@1+ (1,0) [0|0] "" Vector__XXX
 SG_ VCSEC_Device1BuildNumberHashBits m11 : 32|32@1+ (1,0) [0|0] "" Vector__XXX
 SG_ VCSEC_Device1Permissions m9 : 32|32@1+ (1,0) [0|0] "" Vector__XXX
 SG_ VCSEC_Device1SHA1 m8 : 32|32@1+ (1,0) [0|0] "" Vector__XXX
 SG_ VCSEC_Device1WLEntry m6 : 32|5@1+ (1,0) [0|0] "" Vector__XXX
 SG_ VCSEC_Device2BuildNumberHashBits m17 : 32|32@1+ (1,0) [0|0] "" Vector__XXX
 SG_ VCSEC_Device2Permissions m15 : 32|32@1+ (1,0) [0|0] "" Vector__XXX
 SG_ VCSEC_Device2SHA1 m14 : 32|32@1+ (1,0) [0|0] "" Vector__XXX
 SG_ VCSEC_Device2WLEntry m12 : 32|5@1+ (1,0) [0|0] "" Vector__XXX
 SG_ VCSEC_Device3BuildNumberHashBits m23 : 32|32@1+ (1,0) [0|0] "" Vector__XXX
 SG_ VCSEC_Device3Permissions m21 : 32|32@1+ (1,0) [0|0] "" Vector__XXX
 SG_ VCSEC_Device3SHA1 m20 : 32|32@1+ (1,0) [0|0] "" Vector__XXX
 SG_ VCSEC_Device3WLEntry m18 : 32|5@1+ (1,0) [0|0] "" Vector__XXX
 SG_ VCSEC_Device4BuildNumberHashBits m29 : 32|32@1+ (1,0) [0|0] "" Vector__XXX
 SG_ VCSEC_Device4Permissions m27 : 32|32@1+ (1,0) [0|0] "" Vector__XXX
 SG_ VCSEC_Device4SHA1 m26 : 32|32@1+ (1,0) [0|0] "" Vector__XXX
 SG_ VCSEC_Device4WLEntry m24 : 32|5@1+ (1,0) [0|0] "" Vector__XXX
 SG_ VCSEC_Device5BuildNumberHashBits m35 : 32|32@1+ (1,0) [0|0] "" Vector__XXX
 SG_ VCSEC_Device5Permissions m33 : 32|32@1+ (1,0) [0|0] "" Vector__XXX
 SG_ VCSEC_Device5SHA1 m32 : 32|32@1+ (1,0) [0|0] "" Vector__XXX
 SG_ VCSEC_Device5WLEntry m30 : 32|5@1+ (1,0) [0|0] "" Vector__XXX
 SG_ VCSEC_Device6BuildNumberHashBits m41 : 32|32@1+ (1,0) [0|0] "" Vector__XXX
 SG_ VCSEC_Device6Permissions m39 : 32|32@1+ (1,0) [0|0] "" Vector__XXX
 SG_ VCSEC_Device6SHA1 m38 : 32|32@1+ (1,0) [0|0] "" Vector__XXX
 SG_ VCSEC_Device6WLEntry m36 : 32|5@1+ (1,0) [0|0] "" Vector__XXX
 SG_ VCSEC_Device7BuildNumberHashBits m47 : 32|32@1+ (1,0) [0|0] "" Vector__XXX
 SG_ VCSEC_Device7Permissions m45 : 32|32@1+ (1,0) [0|0] "" Vector__XXX
 SG_ VCSEC_Device7SHA1 m44 : 32|32@1+ (1,0) [0|0] "" Vector__XXX
 SG_ VCSEC_Device7WLEntry m42 : 32|5@1+ (1,0) [0|0] "" Vector__XXX
 SG_ VCSEC_Device8BuildNumberHashBits m53 : 32|32@1+ (1,0) [0|0] "" Vector__XXX
 SG_ VCSEC_Device8Permissions m51 : 32|32@1+ (1,0) [0|0] "" Vector__XXX
 SG_ VCSEC_Device8SHA1 m50 : 32|32@1+ (1,0) [0|0] "" Vector__XXX
 SG_ VCSEC_Device8WLEntry m48 : 32|5@1+ (1,0) [0|0] "" Vector__XXX
 SG_ VCSEC_Device9BuildNumberHashBits m59 : 32|32@1+ (1,0) [0|0] "" Vector__XXX
 SG_ VCSEC_Device9Permissions m57 : 32|32@1+ (1,0) [0|0] "" Vector__XXX
 SG_ VCSEC_Device9SHA1 m56 : 32|32@1+ (1,0) [0|0] "" Vector__XXX
 SG_ VCSEC_Device9WLEntry m54 : 32|5@1+ (1,0) [0|0] "" Vector__XXX
 SG_ VCSEC_Device0CpuTime m1 : 34|30@1+ (1,0) [0|0] "" Vector__XXX
 SG_ VCSEC_Device10CpuTime m61 : 34|30@1+ (1,0) [0|0] "" Vector__XXX
 SG_ VCSEC_Device11CpuTime m67 : 34|30@1+ (1,0) [0|0] "" Vector__XXX
 SG_ VCSEC_Device12CpuTime m73 : 34|30@1+ (1,0) [0|0] "" Vector__XXX
 SG_ VCSEC_Device13CpuTime m79 : 34|30@1+ (1,0) [0|0] "" Vector__XXX
 SG_ VCSEC_Device14CpuTime m85 : 34|30@1+ (1,0) [0|0] "" Vector__XXX
 SG_ VCSEC_Device15CpuTime m91 : 34|30@1+ (1,0) [0|0] "" Vector__XXX
 SG_ VCSEC_Device16CpuTime m97 : 34|30@1+ (1,0) [0|0] "" Vector__XXX
 SG_ VCSEC_Device17CpuTime m103 : 34|30@1+ (1,0) [0|0] "" Vector__XXX
 SG_ VCSEC_Device18CpuTime m109 : 34|30@1+ (1,0) [0|0] "" Vector__XXX
 SG_ VCSEC_Device19CpuTime m115 : 34|30@1+ (1,0) [0|0] "" Vector__XXX
 SG_ VCSEC_Device1CpuTime m7 : 34|30@1+ (1,0) [0|0] "" Vector__XXX
 SG_ VCSEC_Device2CpuTime m13 : 34|30@1+ (1,0) [0|0] "" Vector__XXX
 SG_ VCSEC_Device3CpuTime m19 : 34|30@1+ (1,0) [0|0] "" Vector__XXX
 SG_ VCSEC_Device4CpuTime m25 : 34|30@1+ (1,0) [0|0] "" Vector__XXX
 SG_ VCSEC_Device5CpuTime m31 : 34|30@1+ (1,0) [0|0] "" Vector__XXX
 SG_ VCSEC_Device6CpuTime m37 : 34|30@1+ (1,0) [0|0] "" Vector__XXX
 SG_ VCSEC_Device7CpuTime m43 : 34|30@1+ (1,0) [0|0] "" Vector__XXX
 SG_ VCSEC_Device8CpuTime m49 : 34|30@1+ (1,0) [0|0] "" Vector__XXX
 SG_ VCSEC_Device9CpuTime m55 : 34|30@1+ (1,0) [0|0] "" Vector__XXX
 SG_ VCSEC_Device0OSVersion m0 : 37|12@1+ (1,0) [0|0] "" Vector__XXX
 SG_ VCSEC_Device10OSVersion m60 : 37|12@1+ (1,0) [0|0] "" Vector__XXX
 SG_ VCSEC_Device11OSVersion m66 : 37|12@1+ (1,0) [0|0] "" Vector__XXX
 SG_ VCSEC_Device12OSVersion m72 : 37|12@1+ (1,0) [0|0] "" Vector__XXX
 SG_ VCSEC_Device13OSVersion m78 : 37|12@1+ (1,0) [0|0] "" Vector__XXX
 SG_ VCSEC_Device14OSVersion m84 : 37|12@1+ (1,0) [0|0] "" Vector__XXX
 SG_ VCSEC_Device15OSVersion m90 : 37|12@1+ (1,0) [0|0] "" Vector__XXX
 SG_ VCSEC_Device16OSVersion m96 : 37|12@1+ (1,0) [0|0] "" Vector__XXX
 SG_ VCSEC_Device17OSVersion m102 : 37|12@1+ (1,0) [0|0] "" Vector__XXX
 SG_ VCSEC_Device18OSVersion m108 : 37|12@1+ (1,0) [0|0] "" Vector__XXX
 SG_ VCSEC_Device19OSVersion m114 : 37|12@1+ (1,0) [0|0] "" Vector__XXX
 SG_ VCSEC_Device1OSVersion m6 : 37|12@1+ (1,0) [0|0] "" Vector__XXX
 SG_ VCSEC_Device2OSVersion m12 : 37|12@1+ (1,0) [0|0] "" Vector__XXX
 SG_ VCSEC_Device3OSVersion m18 : 37|12@1+ (1,0) [0|0] "" Vector__XXX
 SG_ VCSEC_Device4OSVersion m24 : 37|12@1+ (1,0) [0|0] "" Vector__XXX
 SG_ VCSEC_Device5OSVersion m30 : 37|12@1+ (1,0) [0|0] "" Vector__XXX
 SG_ VCSEC_Device6OSVersion m36 : 37|12@1+ (1,0) [0|0] "" Vector__XXX
 SG_ VCSEC_Device7OSVersion m42 : 37|12@1+ (1,0) [0|0] "" Vector__XXX
 SG_ VCSEC_Device8OSVersion m48 : 37|12@1+ (1,0) [0|0] "" Vector__XXX
 SG_ VCSEC_Device9OSVersion m54 : 37|12@1+ (1,0) [0|0] "" Vector__XXX
 SG_ VCSEC_Device0BatteryLevel m0 : 49|8@1+ (0.015625,0) [0|0] "" Vector__XXX
 SG_ VCSEC_Device10BatteryLevel m60 : 49|8@1+ (0.015625,0) [0|0] "" Vector__XXX
 SG_ VCSEC_Device11BatteryLevel m66 : 49|8@1+ (0.015625,0) [0|0] "" Vector__XXX
 SG_ VCSEC_Device12BatteryLevel m72 : 49|8@1+ (0.015625,0) [0|0] "" Vector__XXX
 SG_ VCSEC_Device13BatteryLevel m78 : 49|8@1+ (0.015625,0) [0|0] "" Vector__XXX
 SG_ VCSEC_Device14BatteryLevel m84 : 49|8@1+ (0.015625,0) [0|0] "" Vector__XXX
 SG_ VCSEC_Device15BatteryLevel m90 : 49|8@1+ (0.015625,0) [0|0] "" Vector__XXX
 SG_ VCSEC_Device16BatteryLevel m96 : 49|8@1+ (0.015625,0) [0|0] "" Vector__XXX
 SG_ VCSEC_Device17BatteryLevel m102 : 49|8@1+ (0.015625,0) [0|0] "" Vector__XXX
 SG_ VCSEC_Device18BatteryLevel m108 : 49|8@1+ (0.015625,0) [0|0] "" Vector__XXX
 SG_ VCSEC_Device19BatteryLevel m114 : 49|8@1+ (0.015625,0) [0|0] "" Vector__XXX
 SG_ VCSEC_Device1BatteryLevel m6 : 49|8@1+ (0.015625,0) [0|0] "" Vector__XXX
 SG_ VCSEC_Device2BatteryLevel m12 : 49|8@1+ (0.015625,0) [0|0] "" Vector__XXX
 SG_ VCSEC_Device3BatteryLevel m18 : 49|8@1+ (0.015625,0) [0|0] "" Vector__XXX
 SG_ VCSEC_Device4BatteryLevel m24 : 49|8@1+ (0.015625,0) [0|0] "" Vector__XXX
 SG_ VCSEC_Device5BatteryLevel m30 : 49|8@1+ (0.015625,0) [0|0] "" Vector__XXX
 SG_ VCSEC_Device6BatteryLevel m36 : 49|8@1+ (0.015625,0) [0|0] "" Vector__XXX
 SG_ VCSEC_Device7BatteryLevel m42 : 49|8@1+ (0.015625,0) [0|0] "" Vector__XXX
 SG_ VCSEC_Device8BatteryLevel m48 : 49|8@1+ (0.015625,0) [0|0] "" Vector__XXX
 SG_ VCSEC_Device9BatteryLevel m54 : 49|8@1+ (0.015625,0) [0|0] "" Vector__XXX
 SG_ VCSEC_Device0Formfactor m0 : 57|5@1+ (1,0) [0|0] "" Vector__XXX
 SG_ VCSEC_Device10Formfactor m60 : 57|5@1+ (1,0) [0|0] "" Vector__XXX
 SG_ VCSEC_Device11Formfactor m66 : 57|5@1+ (1,0) [0|0] "" Vector__XXX
 SG_ VCSEC_Device12Formfactor m72 : 57|5@1+ (1,0) [0|0] "" Vector__XXX
 SG_ VCSEC_Device13Formfactor m78 : 57|5@1+ (1,0) [0|0] "" Vector__XXX
 SG_ VCSEC_Device14Formfactor m84 : 57|5@1+ (1,0) [0|0] "" Vector__XXX
 SG_ VCSEC_Device15Formfactor m90 : 57|5@1+ (1,0) [0|0] "" Vector__XXX
 SG_ VCSEC_Device16Formfactor m96 : 57|5@1+ (1,0) [0|0] "" Vector__XXX
 SG_ VCSEC_Device17Formfactor m102 : 57|5@1+ (1,0) [0|0] "" Vector__XXX
 SG_ VCSEC_Device18Formfactor m108 : 57|5@1+ (1,0) [0|0] "" Vector__XXX
 SG_ VCSEC_Device19Formfactor m114 : 57|5@1+ (1,0) [0|0] "" Vector__XXX
 SG_ VCSEC_Device1Formfactor m6 : 57|5@1+ (1,0) [0|0] "" Vector__XXX
 SG_ VCSEC_Device2Formfactor m12 : 57|5@1+ (1,0) [0|0] "" Vector__XXX
 SG_ VCSEC_Device3Formfactor m18 : 57|5@1+ (1,0) [0|0] "" Vector__XXX
 SG_ VCSEC_Device4Formfactor m24 : 57|5@1+ (1,0) [0|0] "" Vector__XXX
 SG_ VCSEC_Device5Formfactor m30 : 57|5@1+ (1,0) [0|0] "" Vector__XXX
 SG_ VCSEC_Device6Formfactor m36 : 57|5@1+ (1,0) [0|0] "" Vector__XXX
 SG_ VCSEC_Device7Formfactor m42 : 57|5@1+ (1,0) [0|0] "" Vector__XXX
 SG_ VCSEC_Device8Formfactor m48 : 57|5@1+ (1,0) [0|0] "" Vector__XXX
 SG_ VCSEC_Device9Formfactor m54 : 57|5@1+ (1,0) [0|0] "" Vector__XXX
 SG_ VCSEC_Device0BlacklistStatus m0 : 62|1@1+ (1,0) [0|0] "" Vector__XXX
 SG_ VCSEC_Device10BlacklistStatus m60 : 62|1@1+ (1,0) [0|0] "" Vector__XXX
 SG_ VCSEC_Device11BlacklistStatus m66 : 62|1@1+ (1,0) [0|0] "" Vector__XXX
 SG_ VCSEC_Device12BlacklistStatus m72 : 62|1@1+ (1,0) [0|0] "" Vector__XXX
 SG_ VCSEC_Device13BlacklistStatus m78 : 62|1@1+ (1,0) [0|0] "" Vector__XXX
 SG_ VCSEC_Device14BlacklistStatus m84 : 62|1@1+ (1,0) [0|0] "" Vector__XXX
 SG_ VCSEC_Device15BlacklistStatus m90 : 62|1@1+ (1,0) [0|0] "" Vector__XXX
 SG_ VCSEC_Device16BlacklistStatus m96 : 62|1@1+ (1,0) [0|0] "" Vector__XXX
 SG_ VCSEC_Device17BlacklistStatus m102 : 62|1@1+ (1,0) [0|0] "" Vector__XXX
 SG_ VCSEC_Device18BlacklistStatus m108 : 62|1@1+ (1,0) [0|0] "" Vector__XXX
 SG_ VCSEC_Device19BlacklistStatus m114 : 62|1@1+ (1,0) [0|0] "" Vector__XXX
 SG_ VCSEC_Device1BlacklistStatus m6 : 62|1@1+ (1,0) [0|0] "" Vector__XXX
 SG_ VCSEC_Device2BlacklistStatus m12 : 62|1@1+ (1,0) [0|0] "" Vector__XXX
 SG_ VCSEC_Device3BlacklistStatus m18 : 62|1@1+ (1,0) [0|0] "" Vector__XXX
 SG_ VCSEC_Device4BlacklistStatus m24 : 62|1@1+ (1,0) [0|0] "" Vector__XXX
 SG_ VCSEC_Device5BlacklistStatus m30 : 62|1@1+ (1,0) [0|0] "" Vector__XXX
 SG_ VCSEC_Device6BlacklistStatus m36 : 62|1@1+ (1,0) [0|0] "" Vector__XXX
 SG_ VCSEC_Device7BlacklistStatus m42 : 62|1@1+ (1,0) [0|0] "" Vector__XXX
 SG_ VCSEC_Device8BlacklistStatus m48 : 62|1@1+ (1,0) [0|0] "" Vector__XXX
 SG_ VCSEC_Device9BlacklistStatus m54 : 62|1@1+ (1,0) [0|0] "" Vector__XXX
 SG_ VCSEC_Device0Stationary m0 : 63|1@1+ (1,0) [0|0] "" Vector__XXX
 SG_ VCSEC_Device10Stationary m60 : 63|1@1+ (1,0) [0|0] "" Vector__XXX
 SG_ VCSEC_Device11Stationary m66 : 63|1@1+ (1,0) [0|0] "" Vector__XXX
 SG_ VCSEC_Device12Stationary m72 : 63|1@1+ (1,0) [0|0] "" Vector__XXX
 SG_ VCSEC_Device13Stationary m78 : 63|1@1+ (1,0) [0|0] "" Vector__XXX
 SG_ VCSEC_Device14Stationary m84 : 63|1@1+ (1,0) [0|0] "" Vector__XXX
 SG_ VCSEC_Device15Stationary m90 : 63|1@1+ (1,0) [0|0] "" Vector__XXX
 SG_ VCSEC_Device16Stationary m96 : 63|1@1+ (1,0) [0|0] "" Vector__XXX
 SG_ VCSEC_Device17Stationary m102 : 63|1@1+ (1,0) [0|0] "" Vector__XXX
 SG_ VCSEC_Device18Stationary m108 : 63|1@1+ (1,0) [0|0] "" Vector__XXX
 SG_ VCSEC_Device19Stationary m114 : 63|1@1+ (1,0) [0|0] "" Vector__XXX
 SG_ VCSEC_Device1Stationary m6 : 63|1@1+ (1,0) [0|0] "" Vector__XXX
 SG_ VCSEC_Device2Stationary m12 : 63|1@1+ (1,0) [0|0] "" Vector__XXX
 SG_ VCSEC_Device3Stationary m18 : 63|1@1+ (1,0) [0|0] "" Vector__XXX
 SG_ VCSEC_Device4Stationary m24 : 63|1@1+ (1,0) [0|0] "" Vector__XXX
 SG_ VCSEC_Device5Stationary m30 : 63|1@1+ (1,0) [0|0] "" Vector__XXX
 SG_ VCSEC_Device6Stationary m36 : 63|1@1+ (1,0) [0|0] "" Vector__XXX
 SG_ VCSEC_Device7Stationary m42 : 63|1@1+ (1,0) [0|0] "" Vector__XXX
 SG_ VCSEC_Device8Stationary m48 : 63|1@1+ (1,0) [0|0] "" Vector__XXX
 SG_ VCSEC_Device9Stationary m54 : 63|1@1+ (1,0) [0|0] "" Vector__XXX

BO_ 858 DIF_alertMatrix3: 8 Vector__XXX
 SG_ DIF_a133_capacitorOT : 4|1@1+ (1,0) [0|0] "" Vector__XXX
 SG_ DIF_a134_wheelSpeedIrrational : 5|1@1+ (1,0) [0|0] "" Vector__XXX
 SG_ DIF_a136_spiError : 7|1@1+ (1,0) [0|0] "" Vector__XXX
 SG_ DIF_a142_highLashAngle : 13|1@1+ (1,0) [0|0] "" Vector__XXX
 SG_ DIF_a144_configMismatch : 15|1@1+ (1,0) [0|0] "" Vector__XXX
 SG_ DIF_a147_highTorqueWearLimit : 18|1@1+ (1,0) [0|0] "" Vector__XXX
 SG_ DIF_a148_burnInCycleEnded : 19|1@1+ (1,0) [0|0] "" Vector__XXX
 SG_ DIF_a149_oilPumpFailure : 20|1@1+ (1,0) [0|0] "" Vector__XXX
 SG_ DIF_a150_busVD : 21|1@1+ (1,0) [0|0] "" Vector__XXX
 SG_ DIF_a151_shockTorqueLimiter : 22|1@1+ (1,0) [0|0] "" Vector__XXX
 SG_ DIF_a152_linError : 23|1@1+ (1,0) [0|0] "" Vector__XXX
 SG_ DIF_a153_oilPumpDiagnostics : 24|1@1+ (1,0) [0|0] "" Vector__XXX
 SG_ DIF_a154_resolver : 25|1@1+ (1,0) [0|0] "" Vector__XXX
 SG_ DIF_a155_vcfrontMIA : 26|1@1+ (1,0) [0|0] "" Vector__XXX
 SG_ DIF_a156_currentObserver : 27|1@1+ (1,0) [0|0] "" Vector__XXX
 SG_ DIF_a157_rcmMIA : 28|1@1+ (1,0) [0|0] "" Vector__XXX
 SG_ DIF_a158_ibstMIA : 29|1@1+ (1,0) [0|0] "" Vector__XXX
 SG_ DIF_a160_busVoltageAnomaly : 31|1@1+ (1,0) [0|0] "" Vector__XXX
 SG_ DIF_a161_epas3pMIA : 32|1@1+ (1,0) [0|0] "" Vector__XXX
 SG_ DIF_a162_endOfLifetimeBurnIn : 33|1@1+ (1,0) [0|0] "" Vector__XXX
 SG_ DIF_a172_statorOilTempOT : 43|1@1+ (1,0) [0|0] "" Vector__XXX
 SG_ DIF_a173_ascFdbkDiagnostic : 44|1@1+ (1,0) [0|0] "" Vector__XXX
 SG_ DIF_a174_unitMayNotRestart : 45|1@1+ (1,0) [0|0] "" Vector__XXX
 SG_ DIF_a176_safetyICFault : 47|1@1+ (1,0) [0|0] "" Vector__XXX
 SG_ DIF_a177_fluxReferenceCorrected : 48|1@1+ (1,0) [0|0] "" Vector__XXX

BO_ 859 DIF_alertMatrix4: 8 Vector__XXX
 SG_ DIF_a202_excessHeatUnavailable : 9|1@1+ (1,0) [0|0] "" Vector__XXX
 SG_ DIF_a225_tmpEstPlausibility : 32|1@1+ (1,0) [0|0] "" Vector__XXX
 SG_ DIF_a229_busVsensorOverCAN : 36|1@1+ (1,0) [0|0] "" Vector__XXX
 SG_ DIF_a233_diMsgMissed : 40|1@1+ (1,0) [0|0] "" Vector__XXX
 SG_ DIF_a234_pcsMIA : 41|1@1+ (1,0) [0|0] "" Vector__XXX
 SG_ DIF_a236_tasMIA : 43|1@1+ (1,0) [0|0] "" Vector__XXX
 SG_ DIF_a240_clearFusesRoutine : 47|1@1+ (1,0) [0|0] "" Vector__XXX
 SG_ DIF_a241_systemThermallyLimited : 48|1@1+ (1,0) [0|0] "" Vector__XXX
 SG_ DIF_a242_spinDownLearning : 49|1@1+ (1,0) [0|0] "" Vector__XXX
 SG_ DIF_a243_ecuLogAvailable : 50|1@1+ (1,0) [0|0] "" Vector__XXX
 SG_ DIF_a244_mechSafeStateApplied : 51|1@1+ (1,0) [0|0] "" Vector__XXX
 SG_ DIF_a245_mechSafeStatePreWarn : 52|1@1+ (1,0) [0|0] "" Vector__XXX
 SG_ DIF_a246_recoveryAtSpeedError : 53|1@1+ (1,0) [0|0] "" Vector__XXX
 SG_ DIF_a247_rotorOffsetError : 54|1@1+ (1,0) [0|0] "" Vector__XXX
 SG_ DIF_a249_highStatorTempFromResist : 56|1@1+ (1,0) [0|0] "" Vector__XXX
 SG_ DIF_a250_preregulatorRail : 57|1@1+ (1,0) [0|0] "" Vector__XXX
 SG_ DIF_a251_oilPumpService : 58|1@1+ (1,0) [0|0] "" Vector__XXX
 SG_ DIF_a252_currentCoreFallback : 59|1@1+ (1,0) [0|0] "" Vector__XXX
 SG_ DIF_a253_lvBoostedRail : 60|1@1+ (1,0) [0|0] "" Vector__XXX
 SG_ DIF_a254_activeDischargeRail : 61|1@1+ (1,0) [0|0] "" Vector__XXX
 SG_ DIF_a255_currentGainFallback : 62|1@1+ (1,0) [0|0] "" Vector__XXX

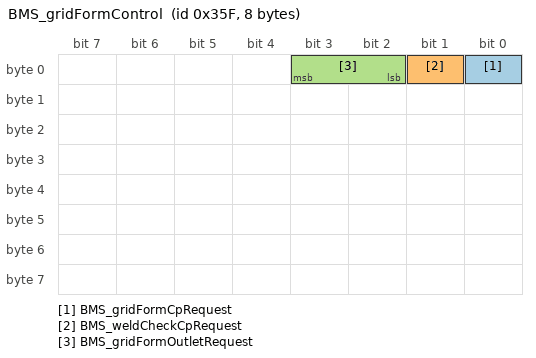
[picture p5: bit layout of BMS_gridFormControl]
BO_ 863 BMS_gridFormControl: 8 Vector__XXX
 SG_ BMS_gridFormCpRequest : 0|1@1+ (1,0) [0|0] "" Vector__XXX
 SG_ BMS_weldCheckCpRequest : 1|1@1+ (1,0) [0|0] "" Vector__XXX
 SG_ BMS_gridFormOutletRequest : 2|2@1+ (1,0) [0|0] "" Vector__XXX

VAL_ 800 BMS_matrixIndex 0 "AlertMatrix0" 1 "AlertMatrix1" 2 "AlertMatrix2" ;
VAL_ 801 VCFRONT_tempCoolantBatInlet 1023 "SNA" ;
VAL_ 801 VCFRONT_tempCoolantPTInlet 2047 "SNA" ;
VAL_ 801 VCFRONT_coolantLevel 0 "NOT_OK" 1 "FILLED" ;
VAL_ 801 VCFRONT_brakeFluidLevel 0 "SNA" 1 "LOW" 2 "NORMAL" ;
VAL_ 801 VCFRONT_tempAmbient 0 "SNA" ;
VAL_ 801 VCFRONT_washerFluidLevel 0 "SNA" 1 "LOW" 2 "NORMAL" ;
VAL_ 801 VCFRONT_tempAmbientFiltered 0 "SNA" ;
VAL_ 810 BMS_isolationResistance 1023 "SNA" ;
VAL_ 810 BMS_chgTimeToFull 4095 "SNA" ;
VAL_ 812 CC_logIndex 0 "Mux0" 1 "Mux1" 2 "Mux2" 3 "Mux3" 4 "Mux4" 10 "Mux10" 11 "Mux11" 12 "Mux12" 13 "Mux13" ;
VAL_ 812 CC_activeConnectorID 255 "SNA" ;
VAL_ 812 CC_conn1Current 255 "SNA" ;
VAL_ 812 CC_conn2Current 255 "SNA" ;
VAL_ 812 CC_conn3Current 255 "SNA" ;
VAL_ 812 CC_conn4Current 255 "SNA" ;
VAL_ 812 CC_temperature1 127 "SNA" ;
VAL_ 812 CC_temperature2 127 "SNA" ;
VAL_ 812 CC_temperature3 127 "SNA" ;
VAL_ 812 CC_contactor1Closed 0 "OPEN" 1 "CLOSED" 3 "SNA" ;
VAL_ 812 CC_contactor2Closed 0 "OPEN" 1 "CLOSED" 3 "SNA" ;
VAL_ 812 CC_temperature4 127 "SNA" ;
VAL_ 816 SCCM_infoIndex 10 "BUILD_HWID_COMPONENTID" 11 "PCBAID_ASSYID_USAGEID" 13 "APP_CRC" 14 "BOOTLOADER_SVN" 16 "SUBCOMPONENT1" 17 "APP_SVNHASH" 18 "BOOTLOADER_SVNHASH" 20 "UDS_PROTOCOL_BOOTCRC" 255 "END" ;
VAL_ 816 SCCM_infoBuildType 0 "UNKNOWN_BUILD" 1 "PLATFORM_BUILD" 2 "LOCAL_BUILD" 3 "TRACEABLE_CI_BUILD" 4 "MFG_BUILD" ;
VAL_ 816 SCCM_infoAssemblyId 1 "ASSEMBLY1" 255 "ASSEMBLY_SNA" ;
VAL_ 818 BMS_bmbMinMaxMultiplexer 0 "THERM_MUX0" 1 "VOLT_MUX1" 2 "END" ;
VAL_ 819 UI_brickVLoggingRequest 0 "FALSE" 1 "TRUE" ;
VAL_ 819 UI_brickBalancingDisabled 0 "FALSE" 1 "TRUE" ;
VAL_ 819 UI_acChargeCurrentLimit 127 "SNA" ;
VAL_ 820 UI_systemPowerLimit 31 "SNA" ;
VAL_ 820 UI_pedalMap 0 "CHILL" 1 "SPORT" 2 "PERFORMANCE" ;
VAL_ 820 UI_systemTorqueLimit 63 "SNA" ;
VAL_ 820 UI_closureConfirmed 0 "NONE" 1 "FRUNK" 2 "PROX" 3 "FALCON" ;
VAL_ 820 UI_limitMode 0 "NORMAL" 1 "VALET" 2 "FACTORY" 3 "SERVICE" ;
VAL_ 820 UI_motorOnMode 0 "NORMAL" 1 "FRONT_ONLY" 2 "REAR_ONLY" ;
VAL_ 820 UI_wasteMode 0 "NONE" 1 "PARTIAL" 2 "FULL" 3 "BURN_IN" ;
VAL_ 820 UI_wasteModeRegenLimit 0 "MAX" 1 "30A" 2 "10A" 3 "0A" ;
VAL_ 820 UI_stoppingMode 0 "STANDARD" 1 "CREEP" 2 "HOLD" ;
VAL_ 820 UI_speedLimit 511 "SNA" ;
VAL_ 821 DIR_infoIndex 0 "DEPRECATED_0" 1 "DEPRECATED_1" 2 "DEPRECATED_2" 3 "DEPRECATED_3" 4 "DEPRECATED_4" 5 "DEPRECATED_5" 6 "DEPRECATED_6" 7 "DEPRECATED_7" 8 "DEPRECATED_8" 9 "DEPRECATED_9" 10 "BUILD_HWID_COMPONENTID" 11 "PCBAID_ASSYID_USAGEID" 13 "APP_CRC" 14 "BOOTLOADER_SVN" 15 "BOOTLOADER_CRC" 16 "SUBCOMPONENT" 17 "APP_GITHASH" 18 "BOOTLOADER_GITHASH" 19 "VERSION_DEPRECATED" 20 "UDS_PROTOCOL_BOOTCRC" 23 "SUBCOMPONENT2" 31 "SUBCOMPONENT_GITHASH" 32 "SUBCOMPONENT2_GITHASH" 33 "SUBCOMPONENT_HWID" 34 "SUBCOMPONENT2_HWID" 255 "END" ;
VAL_ 821 DIR_buildType 0 "UNKNOWN_BUILD" 1 "PLATFORM_BUILD" 2 "LOCAL_BUILD" 3 "TRACEABLE_CI_BUILD" 4 "MFG_BUILD" ;
VAL_ 821 DIR_oilPumpBuildType 0 "UNKNOWN_BUILD" 1 "PLATFORM_BUILD" 2 "LOCAL_BUILD" 3 "TRACEABLE_CI_BUILD" 4 "MFG_BUILD" ;
VAL_ 821 DIR_hardwareId 252 "CONFIGURABLE_HWID_PLACEHOLDER" ;
VAL_ 821 DIR_FPGA_version 254 "LOCAL_BUILD" 255 "SNA" ;
VAL_ 825 VCSEC_vehicleLockStatus 0 "SNA" 1 "ACTIVE_NFC_UNLOCKED" 2 "ACTIVE_NFC_LOCKED" 3 "PASSIVE_SELECTIVE_UNLOCKED" 4 "PASSIVE_BLE_UNLOCKED" 5 "PASSIVE_BLE_LOCKED" 6 "ACTIVE_SELECTIVE_UNLOCKED" 7 "ACTIVE_BLE_UNLOCKED" 8 "ACTIVE_BLE_LOCKED" 9 "ACTIVE_UI_UNLOCKED" 10 "ACTIVE_UI_LOCKED" 11 "ACTIVE_REMOTE_UNLOCKED" 12 "ACTIVE_REMOTE_LOCKED" 13 "CRASH_UNLOCKED" 14 "PASSIVE_INTERNAL_UNLOCKED" 15 "PASSIVE_INTERNAL_LOCKED" ;
VAL_ 825 VCSEC_authenticationStatus 0 "NONE" 1 "AUTHENTICATED_FOR_UNLOCK" 2 "AUTHENTICATED_FOR_DRIVE" ;
VAL_ 825 VCSEC_chargePortLockStatus 0 "UNLOCKED" 1 "LOCKED" ;
VAL_ 825 VCSEC_leftFrontLockStatus 0 "UNLOCKED" 1 "LOCKED" ;
VAL_ 825 VCSEC_leftRearLockStatus 0 "UNLOCKED" 1 "LOCKED" ;
VAL_ 825 VCSEC_rightFrontLockStatus 0 "UNLOCKED" 1 "LOCKED" ;
VAL_ 825 VCSEC_rightRearLockStatus 0 "UNLOCKED" 1 "LOCKED" ;
VAL_ 825 VCSEC_trunkLockStatus 0 "UNLOCKED" 1 "LOCKED" ;
VAL_ 825 VCSEC_lockRequestType 0 "NONE" 1 "PASSIVE_SHIFT_TO_P_UNLOCK" 2 "PASSIVE_PARKBUTTON_UNLOCK" 3 "PASSIVE_INTERNAL_HANDLE_UNLOCK" 4 "PASSIVE_DRIVE_AWAY_LOCK" 5 "PASSIVE_BLE_WALKUP_UNLOCK" 6 "PASSIVE_BLE_EXTERIOR_CHARGEHANDLEBUTTON_UNLOCK" 7 "PASSIVE_BLE_EXTERIOR_HANDLE_UNLOCK" 8 "PASSIVE_BLE_INTERIOR_HANDLE_UNLOCK" 9 "PASSIVE_BLE_LOCK" 10 "CRASH_UNLOCK" 11 "ACTIVE_UI_BUTTON_UNLOCK" 12 "ACTIVE_UI_BUTTON_LOCK" 13 "ACTIVE_REMOTE_UNLOCK" 14 "ACTIVE_REMOTE_LOCK" 15 "ACTIVE_NFC_UNLOCK" 16 "ACTIVE_NFC_LOCK" 17 "ACTIVE_BLE_UNLOCK" 18 "ACTIVE_BLE_LOCK" 19 "PASSIVE_INTERNAL_LOCK_PROMOTION" 20 "PASSIVE_AUTO_PRESENT_DOOR_REQUEST" 21 "KEYFOB_OPEN_DOOR_REQUEST" ;
VAL_ 825 VCSEC_summonRequest 0 "IDLE" 1 "PRIME" 2 "FORWARD" 3 "BACKWARD" 4 "STOP" 5 "SNA" ;
VAL_ 825 VCSEC_MCUCommandType 0 "NONE" 1 "REMOTE_UNLOCK" 2 "REMOTE_START" 3 "COMMAND3" 4 "COMMAND4" 5 "COMMAND5" ;
VAL_ 825 VCSEC_alarmStatus 0 "DISARMED" 1 "ARMED" 2 "PARTIAL_ARMED" 3 "TRIGGERED_FLASH_ACTIVE" 4 "ERROR" 5 "TRIGGERED_FLASH_INACTIVE" 6 "IMMINENT" 7 "DEFAULT" 15 "SNA" ;
VAL_ 825 VCSEC_immobilizerState 0 "IDLE" 1 "PREPARE" 2 "ENCRYPT_BEGIN" 3 "ENCRYPT" 4 "SEND_AUTH_RESPONSE" 5 "SEND_NO_GO_AUTH_RESPONSE" ;
VAL_ 825 VCSEC_lockIndicationRequest 0 "NONE_SNA" 1 "SINGLE" 2 "DOUBLE" 3 "TRIPLE" 4 "HOLD" ;
VAL_ 825 VCSEC_simpleLockStatus 0 "SNA" 1 "UNLOCKED" 2 "LOCKED" ;
VAL_ 825 VCSEC_keyChannelIndexed 15 "SNA" ;
VAL_ 825 VCSEC_remoteStartActive 0 "NONE" 1 "LEGACY" 2 "SIGNED_COMMAND" ;
VAL_ 832 VCFRONT_matrixIndex 0 "AlertMatrix0" 1 "AlertMatrix1" 2 "AlertMatrix2" 3 "AlertMatrix3" 4 "AlertMatrix4" 5 "AlertMatrix5" 6 "AlertMatrix6" 7 "AlertMatrix7" 8 "AlertMatrix8" 9 "AlertMatrix9" ;
VAL_ 833 VCFRONT1_matrixIndex 0 "AlertMatrix0" 1 "AlertMatrix1" 2 "AlertMatrix2" ;
VAL_ 834 VCFRONT2_matrixIndex 0 "AlertMatrix0" 1 "AlertMatrix1" 2 "AlertMatrix2" ;
VAL_ 835 VCRIGHT_mirrorHeatState 0 "SNA" 1 "ON" 2 "OFF" 3 "OFF_UNAVAILABLE" 4 "FAULT" ;
VAL_ 837 PTC_infoIndex 0 "DEPRECATED_0" 1 "DEPRECATED_1" 2 "DEPRECATED_2" 3 "DEPRECATED_3" 4 "DEPRECATED_4" 5 "DEPRECATED_5" 6 "DEPRECATED_6" 7 "DEPRECATED_7" 8 "DEPRECATED_8" 9 "DEPRECATED_9" 10 "BUILD_HWID_COMPONENTID" 11 "PCBAID_ASSYID_USAGEID" 13 "APP_CRC" 14 "BOOTLOADER_SVN" 15 "BOOTLOADER_CRC" 16 "SUBCOMPONENT" 17 "APP_GITHASH" 18 "BOOTLOADER_GITHASH" 19 "VERSION_DEPRECATED" 20 "UDS_PROTOCOL_BOOTCRC" 22 "VARIANTCRC" 25 "PACKAGE_PN_1_7" 26 "PACKAGE_PN_8_14" 27 "PACKAGE_PN_15_20" 29 "PACKAGE_SN_1_7" 30 "PACKAGE_SN_8_14" 31 "SUBCOMPONENT_GITHASH" 255 "END" ;
VAL_ 837 PTC_infoBuildType 0 "UNKNOWN_BUILD" 1 "PLATFORM_BUILD" 2 "LOCAL_BUILD" 3 "TRACEABLE_CI_BUILD" 4 "MFG_BUILD" ;
VAL_ 837 PTC_infoAssemblyId 1 "ASSEMBLY1" 255 "ASSEMBLY_SNA" ;
VAL_ 840 GTW_vehicleVersionMatchStatus 0 "NOT_CALCULATED_YET" 1 "MISMATCHED" 2 "MATCHED" ;
VAL_ 840 GTW_hwtype 0 "SNA" 1 "MPC57" 2 "SPC58" ;
VAL_ 840 GTW_sentryModeState 0 "OFF" 1 "IDLE" 2 "ARMED" 3 "AWARE" 4 "PANIC" 5 "QUIET" 6 "SNA" ;
VAL_ 850 BMS_energyBuffer 255 "SNA" ;
VAL_ 850 BMS_nominalFullPackEnergy 2047 "SNA" ;
VAL_ 850 BMS_expectedEnergyRemaining 2047 "SNA" ;
VAL_ 850 BMS_nominalEnergyRemaining 2047 "SNA" ;
VAL_ 850 BMS_energyToChargeComplete 2047 "SNA" ;
VAL_ 850 BMS_idealEnergyRemaining 2047 "SNA" ;
VAL_ 851 UI_autopilotTrial 0 "NONE" 1 "START" 2 "STOP" 3 "ACTIVE" ;
VAL_ 851 UI_factoryReset 0 "NONE_SNA" 1 "DEVELOPER" 2 "DIAGNOSTIC" 3 "CUSTOMER" ;
VAL_ 851 UI_cellNetworkTechnology 0 "NONE" 1 "GPRS" 2 "EDGE" 3 "UMTS" 4 "HSDPA" 5 "HSUPA" 6 "HSPA" 7 "LTE" 8 "GSM" 9 "CDMA" 10 "WCDMA" 15 "SNA" ;
VAL_ 851 UI_cellSignalBars 0 "ZERO" 1 "ONE" 2 "TWO" 3 "THREE" 4 "FOUR" 5 "FIVE" 7 "SNA" ;
VAL_ 851 UI_trailerModeTelltale 0 "OFF" 1 "BLUE" 2 "YELLOW" 3 "RED" ;
VAL_ 857 VCSEC_DeviceStatusIndex 0 "0_VITALS" 1 "0_STATS" 2 "0_INFO" 3 "0_INFO2" 4 "0_MODEL_NUMBER" 5 "1_VITALS" 6 "1_STATS" 7 "1_INFO" 8 "1_INFO2" 9 "1_MODEL_NUMBER" 10 "2_VITALS" 11 "2_STATS" 12 "2_INFO" 13 "2_INFO2" 14 "2_MODEL_NUMBER" 15 "3_VITALS" 16 "3_STATS" 17 "3_INFO" 18 "3_INFO2" 19 "3_MODEL_NUMBER" 20 "4_VITALS" 21 "4_STATS" 22 "4_INFO" 23 "4_INFO2" 24 "4_MODEL_NUMBER" 25 "5_VITALS" 26 "5_STATS" 27 "5_INFO" 28 "5_INFO2" 29 "5_MODEL_NUMBER" 30 "6_VITALS" 31 "6_STATS" 32 "6_INFO" 33 "6_INFO2" 34 "6_MODEL_NUMBER" 35 "7_VITALS" 36 "7_STATS" 37 "7_INFO" 38 "7_INFO2" 39 "7_MODEL_NUMBER" 40 "8_VITALS" 41 "8_STATS" 42 "8_INFO" 43 "8_INFO2" 44 "8_MODEL_NUMBER" 45 "9_VITALS" 46 "9_STATS" 47 "9_INFO" 48 "9_INFO2" 49 "9_MODEL_NUMBER" 50 "10_VITALS" 51 "10_STATS" 52 "10_INFO" 53 "10_INFO2" 54 "10_MODEL_NUMBER" 55 "11_VITALS" 56 "11_STATS" 57 "11_INFO" 58 "11_INFO2" 59 "11_MODEL_NUMBER" 60 "12_VITALS" 61 "12_STATS" 62 "12_INFO" 63 "12_INFO2" 64 "12_MODEL_NUMBER" 65 "13_VITALS" 66 "13_STATS" 67 "13_INFO" 68 "13_INFO2" 69 "13_MODEL_NUMBER" 70 "14_VITALS" 71 "14_STATS" 72 "14_INFO" 73 "14_INFO2" 74 "14_MODEL_NUMBER" 75 "15_VITALS" 76 "15_STATS" 77 "15_INFO" 78 "15_INFO2" 79 "15_MODEL_NUMBER" 80 "16_VITALS" 81 "16_STATS" 82 "16_INFO" 83 "16_INFO2" 84 "16_MODEL_NUMBER" 85 "17_VITALS" 86 "17_STATS" 87 "17_INFO" 88 "17_INFO2" 89 "17_MODEL_NUMBER" 90 "18_VITALS" 91 "18_STATS" 92 "18_INFO" 93 "18_INFO2" 94 "18_MODEL_NUMBER" 95 "19_VITALS" 96 "19_STATS" 97 "19_INFO" 98 "19_INFO2" 99 "19_MODEL_NUMBER" ;
VAL_ 857 VCSEC_Device0Role 0 "NONE" 1 "SERVICE_KEY" 2 "OWNER_KEY" 3 "USER_KEY" 4 "FM_KEY" ;
VAL_ 857 VCSEC_Device10Role 0 "NONE" 1 "SERVICE_KEY" 2 "OWNER_KEY" 3 "USER_KEY" 4 "FM_KEY" ;
VAL_ 857 VCSEC_Device11Role 0 "NONE" 1 "SERVICE_KEY" 2 "OWNER_KEY" 3 "USER_KEY" 4 "FM_KEY" ;
VAL_ 857 VCSEC_Device12Role 0 "NONE" 1 "SERVICE_KEY" 2 "OWNER_KEY" 3 "USER_KEY" 4 "FM_KEY" ;
VAL_ 857 VCSEC_Device13Role 0 "NONE" 1 "SERVICE_KEY" 2 "OWNER_KEY" 3 "USER_KEY" 4 "FM_KEY" ;
VAL_ 857 VCSEC_Device14Role 0 "NONE" 1 "SERVICE_KEY" 2 "OWNER_KEY" 3 "USER_KEY" 4 "FM_KEY" ;
VAL_ 857 VCSEC_Device15Role 0 "NONE" 1 "SERVICE_KEY" 2 "OWNER_KEY" 3 "USER_KEY" 4 "FM_KEY" ;
VAL_ 857 VCSEC_Device16Role 0 "NONE" 1 "SERVICE_KEY" 2 "OWNER_KEY" 3 "USER_KEY" 4 "FM_KEY" ;
VAL_ 857 VCSEC_Device17Role 0 "NONE" 1 "SERVICE_KEY" 2 "OWNER_KEY" 3 "USER_KEY" 4 "FM_KEY" ;
VAL_ 857 VCSEC_Device18Role 0 "NONE" 1 "SERVICE_KEY" 2 "OWNER_KEY" 3 "USER_KEY" 4 "FM_KEY" ;
VAL_ 857 VCSEC_Device19Role 0 "NONE" 1 "SERVICE_KEY" 2 "OWNER_KEY" 3 "USER_KEY" 4 "FM_KEY" ;
VAL_ 857 VCSEC_Device1Role 0 "NONE" 1 "SERVICE_KEY" 2 "OWNER_KEY" 3 "USER_KEY" 4 "FM_KEY" ;
VAL_ 857 VCSEC_Device2Role 0 "NONE" 1 "SERVICE_KEY" 2 "OWNER_KEY" 3 "USER_KEY" 4 "FM_KEY" ;
VAL_ 857 VCSEC_Device3Role 0 "NONE" 1 "SERVICE_KEY" 2 "OWNER_KEY" 3 "USER_KEY" 4 "FM_KEY" ;
VAL_ 857 VCSEC_Device4Role 0 "NONE" 1 "SERVICE_KEY" 2 "OWNER_KEY" 3 "USER_KEY" 4 "FM_KEY" ;
VAL_ 857 VCSEC_Device5Role 0 "NONE" 1 "SERVICE_KEY" 2 "OWNER_KEY" 3 "USER_KEY" 4 "FM_KEY" ;
VAL_ 857 VCSEC_Device6Role 0 "NONE" 1 "SERVICE_KEY" 2 "OWNER_KEY" 3 "USER_KEY" 4 "FM_KEY" ;
VAL_ 857 VCSEC_Device7Role 0 "NONE" 1 "SERVICE_KEY" 2 "OWNER_KEY" 3 "USER_KEY" 4 "FM_KEY" ;
VAL_ 857 VCSEC_Device8Role 0 "NONE" 1 "SERVICE_KEY" 2 "OWNER_KEY" 3 "USER_KEY" 4 "FM_KEY" ;
VAL_ 857 VCSEC_Device9Role 0 "NONE" 1 "SERVICE_KEY" 2 "OWNER_KEY" 3 "USER_KEY" 4 "FM_KEY" ;
VAL_ 857 VCSEC_Device0Formfactor 0 "UNKNOWN" 1 "NFC_CARD" 2 "3_BUTTON_BLE_CAR_KEYFOB" 3 "BLE_DEVICE" 4 "NFC_DEVICE" 5 "BLE_AND_NFC_DEVICE" 6 "IOS_DEVICE" 7 "ANDROID_DEVICE" 8 "3_BUTTON_BLE_CAR_KEYFOB_P60" 9 "CLOUD_KEY" 10 "3_BUTTON_GEN2_CAR_KEYFOB_P60" 11 "5_BUTTON_GEN2_CAR_KEYFOB_P60" 12 "3_BUTTON_GEN2_CAR_KEYFOB_P60_V2" 13 "3_BUTTON_GEN2_CAR_KEYFOB_P60_V3" ;
VAL_ 857 VCSEC_Device10Formfactor 0 "UNKNOWN" 1 "NFC_CARD" 2 "3_BUTTON_BLE_CAR_KEYFOB" 3 "BLE_DEVICE" 4 "NFC_DEVICE" 5 "BLE_AND_NFC_DEVICE" 6 "IOS_DEVICE" 7 "ANDROID_DEVICE" 8 "3_BUTTON_BLE_CAR_KEYFOB_P60" 9 "CLOUD_KEY" 10 "3_BUTTON_GEN2_CAR_KEYFOB_P60" 11 "5_BUTTON_GEN2_CAR_KEYFOB_P60" 12 "3_BUTTON_GEN2_CAR_KEYFOB_P60_V2" 13 "3_BUTTON_GEN2_CAR_KEYFOB_P60_V3" ;
VAL_ 857 VCSEC_Device11Formfactor 0 "UNKNOWN" 1 "NFC_CARD" 2 "3_BUTTON_BLE_CAR_KEYFOB" 3 "BLE_DEVICE" 4 "NFC_DEVICE" 5 "BLE_AND_NFC_DEVICE" 6 "IOS_DEVICE" 7 "ANDROID_DEVICE" 8 "3_BUTTON_BLE_CAR_KEYFOB_P60" 9 "CLOUD_KEY" 10 "3_BUTTON_GEN2_CAR_KEYFOB_P60" 11 "5_BUTTON_GEN2_CAR_KEYFOB_P60" 12 "3_BUTTON_GEN2_CAR_KEYFOB_P60_V2" 13 "3_BUTTON_GEN2_CAR_KEYFOB_P60_V3" ;
VAL_ 857 VCSEC_Device12Formfactor 0 "UNKNOWN" 1 "NFC_CARD" 2 "3_BUTTON_BLE_CAR_KEYFOB" 3 "BLE_DEVICE" 4 "NFC_DEVICE" 5 "BLE_AND_NFC_DEVICE" 6 "IOS_DEVICE" 7 "ANDROID_DEVICE" 8 "3_BUTTON_BLE_CAR_KEYFOB_P60" 9 "CLOUD_KEY" 10 "3_BUTTON_GEN2_CAR_KEYFOB_P60" 11 "5_BUTTON_GEN2_CAR_KEYFOB_P60" 12 "3_BUTTON_GEN2_CAR_KEYFOB_P60_V2" 13 "3_BUTTON_GEN2_CAR_KEYFOB_P60_V3" ;
VAL_ 857 VCSEC_Device13Formfactor 0 "UNKNOWN" 1 "NFC_CARD" 2 "3_BUTTON_BLE_CAR_KEYFOB" 3 "BLE_DEVICE" 4 "NFC_DEVICE" 5 "BLE_AND_NFC_DEVICE" 6 "IOS_DEVICE" 7 "ANDROID_DEVICE" 8 "3_BUTTON_BLE_CAR_KEYFOB_P60" 9 "CLOUD_KEY" 10 "3_BUTTON_GEN2_CAR_KEYFOB_P60" 11 "5_BUTTON_GEN2_CAR_KEYFOB_P60" 12 "3_BUTTON_GEN2_CAR_KEYFOB_P60_V2" 13 "3_BUTTON_GEN2_CAR_KEYFOB_P60_V3" ;
VAL_ 857 VCSEC_Device14Formfactor 0 "UNKNOWN" 1 "NFC_CARD" 2 "3_BUTTON_BLE_CAR_KEYFOB" 3 "BLE_DEVICE" 4 "NFC_DEVICE" 5 "BLE_AND_NFC_DEVICE" 6 "IOS_DEVICE" 7 "ANDROID_DEVICE" 8 "3_BUTTON_BLE_CAR_KEYFOB_P60" 9 "CLOUD_KEY" 10 "3_BUTTON_GEN2_CAR_KEYFOB_P60" 11 "5_BUTTON_GEN2_CAR_KEYFOB_P60" 12 "3_BUTTON_GEN2_CAR_KEYFOB_P60_V2" 13 "3_BUTTON_GEN2_CAR_KEYFOB_P60_V3" ;
VAL_ 857 VCSEC_Device15Formfactor 0 "UNKNOWN" 1 "NFC_CARD" 2 "3_BUTTON_BLE_CAR_KEYFOB" 3 "BLE_DEVICE" 4 "NFC_DEVICE" 5 "BLE_AND_NFC_DEVICE" 6 "IOS_DEVICE" 7 "ANDROID_DEVICE" 8 "3_BUTTON_BLE_CAR_KEYFOB_P60" 9 "CLOUD_KEY" 10 "3_BUTTON_GEN2_CAR_KEYFOB_P60" 11 "5_BUTTON_GEN2_CAR_KEYFOB_P60" 12 "3_BUTTON_GEN2_CAR_KEYFOB_P60_V2" 13 "3_BUTTON_GEN2_CAR_KEYFOB_P60_V3" ;
VAL_ 857 VCSEC_Device16Formfactor 0 "UNKNOWN" 1 "NFC_CARD" 2 "3_BUTTON_BLE_CAR_KEYFOB" 3 "BLE_DEVICE" 4 "NFC_DEVICE" 5 "BLE_AND_NFC_DEVICE" 6 "IOS_DEVICE" 7 "ANDROID_DEVICE" 8 "3_BUTTON_BLE_CAR_KEYFOB_P60" 9 "CLOUD_KEY" 10 "3_BUTTON_GEN2_CAR_KEYFOB_P60" 11 "5_BUTTON_GEN2_CAR_KEYFOB_P60" 12 "3_BUTTON_GEN2_CAR_KEYFOB_P60_V2" 13 "3_BUTTON_GEN2_CAR_KEYFOB_P60_V3" ;
VAL_ 857 VCSEC_Device17Formfactor 0 "UNKNOWN" 1 "NFC_CARD" 2 "3_BUTTON_BLE_CAR_KEYFOB" 3 "BLE_DEVICE" 4 "NFC_DEVICE" 5 "BLE_AND_NFC_DEVICE" 6 "IOS_DEVICE" 7 "ANDROID_DEVICE" 8 "3_BUTTON_BLE_CAR_KEYFOB_P60" 9 "CLOUD_KEY" 10 "3_BUTTON_GEN2_CAR_KEYFOB_P60" 11 "5_BUTTON_GEN2_CAR_KEYFOB_P60" 12 "3_BUTTON_GEN2_CAR_KEYFOB_P60_V2" 13 "3_BUTTON_GEN2_CAR_KEYFOB_P60_V3" ;
VAL_ 857 VCSEC_Device18Formfactor 0 "UNKNOWN" 1 "NFC_CARD" 2 "3_BUTTON_BLE_CAR_KEYFOB" 3 "BLE_DEVICE" 4 "NFC_DEVICE" 5 "BLE_AND_NFC_DEVICE" 6 "IOS_DEVICE" 7 "ANDROID_DEVICE" 8 "3_BUTTON_BLE_CAR_KEYFOB_P60" 9 "CLOUD_KEY" 10 "3_BUTTON_GEN2_CAR_KEYFOB_P60" 11 "5_BUTTON_GEN2_CAR_KEYFOB_P60" 12 "3_BUTTON_GEN2_CAR_KEYFOB_P60_V2" 13 "3_BUTTON_GEN2_CAR_KEYFOB_P60_V3" ;
VAL_ 857 VCSEC_Device19Formfactor 0 "UNKNOWN" 1 "NFC_CARD" 2 "3_BUTTON_BLE_CAR_KEYFOB" 3 "BLE_DEVICE" 4 "NFC_DEVICE" 5 "BLE_AND_NFC_DEVICE" 6 "IOS_DEVICE" 7 "ANDROID_DEVICE" 8 "3_BUTTON_BLE_CAR_KEYFOB_P60" 9 "CLOUD_KEY" 10 "3_BUTTON_GEN2_CAR_KEYFOB_P60" 11 "5_BUTTON_GEN2_CAR_KEYFOB_P60" 12 "3_BUTTON_GEN2_CAR_KEYFOB_P60_V2" 13 "3_BUTTON_GEN2_CAR_KEYFOB_P60_V3" ;
VAL_ 857 VCSEC_Device1Formfactor 0 "UNKNOWN" 1 "NFC_CARD" 2 "3_BUTTON_BLE_CAR_KEYFOB" 3 "BLE_DEVICE" 4 "NFC_DEVICE" 5 "BLE_AND_NFC_DEVICE" 6 "IOS_DEVICE" 7 "ANDROID_DEVICE" 8 "3_BUTTON_BLE_CAR_KEYFOB_P60" 9 "CLOUD_KEY" 10 "3_BUTTON_GEN2_CAR_KEYFOB_P60" 11 "5_BUTTON_GEN2_CAR_KEYFOB_P60" 12 "3_BUTTON_GEN2_CAR_KEYFOB_P60_V2" 13 "3_BUTTON_GEN2_CAR_KEYFOB_P60_V3" ;
VAL_ 857 VCSEC_Device2Formfactor 0 "UNKNOWN" 1 "NFC_CARD" 2 "3_BUTTON_BLE_CAR_KEYFOB" 3 "BLE_DEVICE" 4 "NFC_DEVICE" 5 "BLE_AND_NFC_DEVICE" 6 "IOS_DEVICE" 7 "ANDROID_DEVICE" 8 "3_BUTTON_BLE_CAR_KEYFOB_P60" 9 "CLOUD_KEY" 10 "3_BUTTON_GEN2_CAR_KEYFOB_P60" 11 "5_BUTTON_GEN2_CAR_KEYFOB_P60" 12 "3_BUTTON_GEN2_CAR_KEYFOB_P60_V2" 13 "3_BUTTON_GEN2_CAR_KEYFOB_P60_V3" ;
VAL_ 857 VCSEC_Device3Formfactor 0 "UNKNOWN" 1 "NFC_CARD" 2 "3_BUTTON_BLE_CAR_KEYFOB" 3 "BLE_DEVICE" 4 "NFC_DEVICE" 5 "BLE_AND_NFC_DEVICE" 6 "IOS_DEVICE" 7 "ANDROID_DEVICE" 8 "3_BUTTON_BLE_CAR_KEYFOB_P60" 9 "CLOUD_KEY" 10 "3_BUTTON_GEN2_CAR_KEYFOB_P60" 11 "5_BUTTON_GEN2_CAR_KEYFOB_P60" 12 "3_BUTTON_GEN2_CAR_KEYFOB_P60_V2" 13 "3_BUTTON_GEN2_CAR_KEYFOB_P60_V3" ;
VAL_ 857 VCSEC_Device4Formfactor 0 "UNKNOWN" 1 "NFC_CARD" 2 "3_BUTTON_BLE_CAR_KEYFOB" 3 "BLE_DEVICE" 4 "NFC_DEVICE" 5 "BLE_AND_NFC_DEVICE" 6 "IOS_DEVICE" 7 "ANDROID_DEVICE" 8 "3_BUTTON_BLE_CAR_KEYFOB_P60" 9 "CLOUD_KEY" 10 "3_BUTTON_GEN2_CAR_KEYFOB_P60" 11 "5_BUTTON_GEN2_CAR_KEYFOB_P60" 12 "3_BUTTON_GEN2_CAR_KEYFOB_P60_V2" 13 "3_BUTTON_GEN2_CAR_KEYFOB_P60_V3" ;
VAL_ 857 VCSEC_Device5Formfactor 0 "UNKNOWN" 1 "NFC_CARD" 2 "3_BUTTON_BLE_CAR_KEYFOB" 3 "BLE_DEVICE" 4 "NFC_DEVICE" 5 "BLE_AND_NFC_DEVICE" 6 "IOS_DEVICE" 7 "ANDROID_DEVICE" 8 "3_BUTTON_BLE_CAR_KEYFOB_P60" 9 "CLOUD_KEY" 10 "3_BUTTON_GEN2_CAR_KEYFOB_P60" 11 "5_BUTTON_GEN2_CAR_KEYFOB_P60" 12 "3_BUTTON_GEN2_CAR_KEYFOB_P60_V2" 13 "3_BUTTON_GEN2_CAR_KEYFOB_P60_V3" ;
VAL_ 857 VCSEC_Device6Formfactor 0 "UNKNOWN" 1 "NFC_CARD" 2 "3_BUTTON_BLE_CAR_KEYFOB" 3 "BLE_DEVICE" 4 "NFC_DEVICE" 5 "BLE_AND_NFC_DEVICE" 6 "IOS_DEVICE" 7 "ANDROID_DEVICE" 8 "3_BUTTON_BLE_CAR_KEYFOB_P60" 9 "CLOUD_KEY" 10 "3_BUTTON_GEN2_CAR_KEYFOB_P60" 11 "5_BUTTON_GEN2_CAR_KEYFOB_P60" 12 "3_BUTTON_GEN2_CAR_KEYFOB_P60_V2" 13 "3_BUTTON_GEN2_CAR_KEYFOB_P60_V3" ;
VAL_ 857 VCSEC_Device7Formfactor 0 "UNKNOWN" 1 "NFC_CARD" 2 "3_BUTTON_BLE_CAR_KEYFOB" 3 "BLE_DEVICE" 4 "NFC_DEVICE" 5 "BLE_AND_NFC_DEVICE" 6 "IOS_DEVICE" 7 "ANDROID_DEVICE" 8 "3_BUTTON_BLE_CAR_KEYFOB_P60" 9 "CLOUD_KEY" 10 "3_BUTTON_GEN2_CAR_KEYFOB_P60" 11 "5_BUTTON_GEN2_CAR_KEYFOB_P60" 12 "3_BUTTON_GEN2_CAR_KEYFOB_P60_V2" 13 "3_BUTTON_GEN2_CAR_KEYFOB_P60_V3" ;
VAL_ 857 VCSEC_Device8Formfactor 0 "UNKNOWN" 1 "NFC_CARD" 2 "3_BUTTON_BLE_CAR_KEYFOB" 3 "BLE_DEVICE" 4 "NFC_DEVICE" 5 "BLE_AND_NFC_DEVICE" 6 "IOS_DEVICE" 7 "ANDROID_DEVICE" 8 "3_BUTTON_BLE_CAR_KEYFOB_P60" 9 "CLOUD_KEY" 10 "3_BUTTON_GEN2_CAR_KEYFOB_P60" 11 "5_BUTTON_GEN2_CAR_KEYFOB_P60" 12 "3_BUTTON_GEN2_CAR_KEYFOB_P60_V2" 13 "3_BUTTON_GEN2_CAR_KEYFOB_P60_V3" ;
VAL_ 857 VCSEC_Device9Formfactor 0 "UNKNOWN" 1 "NFC_CARD" 2 "3_BUTTON_BLE_CAR_KEYFOB" 3 "BLE_DEVICE" 4 "NFC_DEVICE" 5 "BLE_AND_NFC_DEVICE" 6 "IOS_DEVICE" 7 "ANDROID_DEVICE" 8 "3_BUTTON_BLE_CAR_KEYFOB_P60" 9 "CLOUD_KEY" 10 "3_BUTTON_GEN2_CAR_KEYFOB_P60" 11 "5_BUTTON_GEN2_CAR_KEYFOB_P60" 12 "3_BUTTON_GEN2_CAR_KEYFOB_P60_V2" 13 "3_BUTTON_GEN2_CAR_KEYFOB_P60_V3" ;
